VERSION ""

NS_ :

BS_:

BU_: FC ADS HPP APA FR

BO_ 400 FC_190: 64 FC
 SG_ FC_Line03_BlockCtr : 495|4@0+ (1,0) [0|15] "-"  HPP,ADS,APA
 SG_ FC_RollingCounter_190 : 491|4@0+ (1,0) [0|15] ""  HPP,ADS,APA
 SG_ FC_CRCCheck_190 : 503|16@0+ (1,0) [0|65535] ""  HPP,ADS,APA
 SG_ FC_Line_03_MeasureType : 465|2@0+ (1,0) [0|2] ""  HPP,ADS,APA
 SG_ FC_Line_03_curvature_alteration : 371|12@0+ (3.8147E-006,-0.0078125) [-0.0078125|0.0078086965] "1/m2"  HPP,ADS,APA
 SG_ FC_Line_03__curve : 479|13@0+ (3.8147E-006,-0.015625) [-0.015625|0.0156212077] "1/m"  HPP,ADS,APA
 SG_ FC_Line_03_HeadingAngle : 351|13@0+ (0.000488281,-1.6) [-1.6|1.6] "rad"  HPP,ADS,APA
 SG_ FC_Line_03_dy : 462|12@0+ (0.015625,-32) [-32|31.984375] "m"  HPP,ADS,APA
 SG_ FC_Line_03_dx_End_std : 455|9@0+ (0.0078125,0) [0|3.992187] "m"  HPP,ADS,APA
 SG_ FC_Line_03__dx_End : 433|10@0+ (0.25,0) [0|255.75] "m"  HPP,ADS,APA
 SG_ FC_Line_03_dx_Start_std : 426|9@0+ (0.0078125,0) [0|3.9921875] "m"  HPP,ADS,APA
 SG_ FC_Line_03_dx_Start : 423|13@0+ (0.025,0) [0|204.775] "m"  HPP,ADS,APA
 SG_ FC_Line_03_Width : 415|8@0+ (0.01,0) [0|2.55] "m"  HPP,ADS,APA
 SG_ FC_Line_03_color : 402|3@0+ (1,0) [0|7] ""  HPP,ADS,APA
 SG_ FC_Line_03_Id : 399|8@0+ (1,0) [1|255] ""  HPP,ADS,APA
 SG_ FC_Line_03_TypeConfidence : 391|6@0+ (2,0) [0|100] "%"  HPP,ADS,APA
 SG_ FC_Line_03_Type : 407|5@0+ (1,0) [0|31] ""  HPP,ADS,APA
 SG_ FC_Line_02__exist_prob : 325|6@0+ (2,0) [0|100] "%"  HPP,ADS,APA
 SG_ FC_Line_02_MeasureType : 310|2@0+ (1,0) [0|2] ""  HPP,ADS,APA
 SG_ FC_Line_02_curvature_alteration : 307|12@0+ (3.8147E-006,-0.0078125) [-0.0078125|0.0078086965] "1/m2"  HPP,ADS,APA
 SG_ FC_Line_02__curve : 292|13@0+ (3.8147E-006,-0.015625) [-0.015625|0.0156212077] "1/m"  HPP,ADS,APA
 SG_ FC_Line_02_HeadingAngle : 335|13@0+ (0.000488281,-1.6) [-1.6|1.6] "rad"  HPP,ADS,APA
 SG_ FC_Line_02_dy : 270|12@0+ (0.015625,-32) [-32|31.984375] "m"  HPP,ADS,APA
 SG_ FC_Line_02_dx_End_std : 263|9@0+ (0.0078125,0) [0|3.992187] "m"  HPP,ADS,APA
 SG_ FC_Line_02__dx_End : 241|10@0+ (0.25,0) [0|255.75] "m"  HPP,ADS,APA
 SG_ FC_Line_02_dx_Start_std : 234|9@0+ (0.0078125,0) [0|3.9921875] "m"  HPP,ADS,APA
 SG_ FC_Line_02_dx_Start : 231|13@0+ (0.025,0) [0|204.775] "m"  HPP,ADS,APA
 SG_ FC_Line_02_Width : 223|8@0+ (0.01,0) [0|2.55] "m"  HPP,ADS,APA
 SG_ FC_Line_02_color : 210|3@0+ (1,0) [0|7] ""  HPP,ADS,APA
 SG_ FC_Line_02_Id : 207|8@0+ (1,0) [1|255] ""  HPP,ADS,APA
 SG_ FC_Line_02_TypeConfidence : 199|6@0+ (2,0) [0|100] "%"  HPP,ADS,APA
 SG_ FC_Line_02_Type : 215|5@0+ (1,0) [0|31] ""  HPP,ADS,APA
 SG_ FC_Line02_BlockCtr : 187|4@0+ (1,0) [0|15] "-"  HPP,ADS,APA
 SG_ FC_Line01_BlockCtr : 191|4@0+ (1,0) [0|15] "-"  HPP,ADS,APA
 SG_ FC_LineTiOut : 146|1@0+ (1,0) [0|1] "-"  HPP,ADS,APA
 SG_ FC_LineTiLeap : 145|1@0+ (1,0) [0|1] "-"  HPP,ADS,APA
 SG_ FC_LineTiBas : 144|1@0+ (1,0) [0|1] "-"  HPP,ADS,APA
 SG_ FC_LineTiStamp : 159|32@0+ (0.0001,0) [0|429496.7295] "s"  HPP,ADS,APA
 SG_ FC_Line_01__exist_prob : 133|6@0+ (2,0) [0|100] "%"  HPP,ADS,APA
 SG_ FC_Line_01_MeasureType : 118|2@0+ (1,0) [0|2] ""  HPP,ADS,APA
 SG_ FC_Line_01_curvature_alteration : 115|12@0+ (3.8147E-006,-0.0078125) [-0.0078125|0.0078086965] "1/m2"  HPP,ADS,APA
 SG_ FC_Line_01__curve : 100|13@0+ (3.8147E-006,-0.015625) [-0.015625|0.0156212077] "1/m"  HPP,ADS,APA
 SG_ FC_Line_01_HeadingAngle : 143|13@0+ (0.000488281,-1.6) [-1.6|1.6] "rad"  HPP,ADS,APA
 SG_ FC_Line_01_dy : 78|12@0+ (0.015625,-32) [-32|31.984375] "m"  HPP,ADS,APA
 SG_ FC_Line_01_dx_End_std : 71|9@0+ (0.0078125,0) [0|3.992187] "m"  HPP,ADS,APA
 SG_ FC_Line_01__dx_End : 49|10@0+ (0.25,0) [0|255.75] "m"  HPP,ADS,APA
 SG_ FC_Line_01_dx_Start_std : 42|9@0+ (0.0078125,0) [0|3.9921875] "m"  HPP,ADS,APA
 SG_ FC_Line_01_dx_Start : 39|13@0+ (0.025,0) [0|204.775] "m"  HPP,ADS,APA
 SG_ FC_Line_01_Width : 31|8@0+ (0.01,0) [0|2.55] "m"  HPP,ADS,APA
 SG_ FC_Line_01_color : 18|3@0+ (1,0) [0|7] ""  HPP,ADS,APA
 SG_ FC_Line_01_Id : 15|8@0+ (1,0) [1|255] ""  HPP,ADS,APA
 SG_ FC_Line_01_TypeConfidence : 7|6@0+ (2,0) [0|100] "%"  HPP,ADS,APA
 SG_ FC_Line_01_Type : 23|5@0+ (1,0) [0|31] ""  HPP,ADS,APA

BO_ 401 FC_191: 64 FC
 SG_ FC_RollingCounter_191 : 491|4@0+ (1,0) [0|15] ""  HPP,ADS,APA
 SG_ FC_CRCCheck_191 : 503|16@0+ (1,0) [0|65535] ""  HPP,ADS,APA
 SG_ FC_Line_06__exist_prob : 333|6@0+ (2,0) [0|100] "%"  HPP,ADS,APA
 SG_ FC_Line_06_MeasureType : 465|2@0+ (1,0) [0|2] ""  HPP,ADS,APA
 SG_ FC_Line_06_curvature_alteration : 371|12@0+ (3.8147E-006,-0.0078125) [-0.0078125|0.0078086965] "1/m2"  HPP,ADS,APA
 SG_ FC_Line_06__curve : 479|13@0+ (3.8147E-006,-0.015625) [-0.015625|0.0156212077] "1/m"  HPP,ADS,APA
 SG_ FC_Line_06_HeadingAngle : 343|13@0+ (0.000488281,-1.6) [-1.6|1.6] "rad"  HPP,ADS,APA
 SG_ FC_Line_06_dy : 462|12@0+ (0.015625,-32) [-32|31.984375] "m"  HPP,ADS,APA
 SG_ FC_Line_06_dx_End_std : 455|9@0+ (0.0078125,0) [0|3.992187] "m"  HPP,ADS,APA
 SG_ FC_Line_06__dx_End : 433|10@0+ (0.25,0) [0|255.75] "m"  HPP,ADS,APA
 SG_ FC_Line_06_dx_Start_std : 426|9@0+ (0.0078125,0) [0|3.9921875] "m"  HPP,ADS,APA
 SG_ FC_Line_06_dx_Start : 423|13@0+ (0.025,0) [0|204.775] "m"  HPP,ADS,APA
 SG_ FC_Line_06_Width : 415|8@0+ (0.01,0) [0|2.55] "m"  HPP,ADS,APA
 SG_ FC_Line_06_color : 402|3@0+ (1,0) [0|7] ""  HPP,ADS,APA
 SG_ FC_Line_06_Id : 399|8@0+ (1,0) [1|255] ""  HPP,ADS,APA
 SG_ FC_Line_06_TypeConfidence : 391|6@0+ (2,0) [0|100] "%"  HPP,ADS,APA
 SG_ FC_Line_06_Type : 407|5@0+ (1,0) [0|31] ""  HPP,ADS,APA
 SG_ FC_Line_05__exist_prob : 325|6@0+ (2,0) [0|100] "%"  HPP,ADS,APA
 SG_ FC_Line_05_MeasureType : 310|2@0+ (1,0) [0|2] ""  HPP,ADS,APA
 SG_ FC_Line_05_curvature_alteration : 307|12@0+ (3.8147E-006,-0.0078125) [-0.0078125|0.0078086965] "1/m2"  HPP,ADS,APA
 SG_ FC_Line_05__curve : 292|13@0+ (3.8147E-006,-0.015625) [-0.015625|0.0156212077] "1/m"  HPP,ADS,APA
 SG_ FC_Line_05_HeadingAngle : 167|13@0+ (0.000488281,-1.6) [-1.6|1.6] "rad"  HPP,ADS,APA
 SG_ FC_Line_05_dy : 270|12@0+ (0.015625,-32) [-32|31.984375] "m"  HPP,ADS,APA
 SG_ FC_Line_05_dx_End_std : 263|9@0+ (0.0078125,0) [0|3.992187] "m"  HPP,ADS,APA
 SG_ FC_Line_05__dx_End : 241|10@0+ (0.25,0) [0|255.75] "m"  HPP,ADS,APA
 SG_ FC_Line_05_dx_Start_std : 234|9@0+ (0.0078125,0) [0|3.9921875] "m"  HPP,ADS,APA
 SG_ FC_Line_05_dx_Start : 231|13@0+ (0.025,0) [0|204.775] "m"  HPP,ADS,APA
 SG_ FC_Line_05_Width : 223|8@0+ (0.01,0) [0|2.55] "m"  HPP,ADS,APA
 SG_ FC_Line_05_color : 210|3@0+ (1,0) [0|7] ""  HPP,ADS,APA
 SG_ FC_Line_05_Id : 207|8@0+ (1,0) [1|255] ""  HPP,ADS,APA
 SG_ FC_Line_05_TypeConfidence : 199|6@0+ (2,0) [0|100] "%"  HPP,ADS,APA
 SG_ FC_Line_05_Type : 215|5@0+ (1,0) [0|31] ""  HPP,ADS,APA
 SG_ FC_Line_04__exist_prob : 133|6@0+ (2,0) [0|100] "%"  HPP,ADS,APA
 SG_ FC_Line_04_MeasureType : 118|2@0+ (1,0) [0|2] ""  HPP,ADS,APA
 SG_ FC_Line_04_curvature_alteration : 115|12@0+ (3.8147E-006,-0.0078125) [-0.0078125|0.0078086965] "1/m2"  HPP,ADS,APA
 SG_ FC_Line_04__curve : 100|13@0+ (3.8147E-006,-0.015625) [-0.015625|0.0156212077] "1/m"  HPP,ADS,APA
 SG_ FC_Line_04_HeadingAngle : 151|13@0+ (0.000488281,-1.6) [-1.6|1.6] "rad"  HPP,ADS,APA
 SG_ FC_Line_04_dy : 78|12@0+ (0.015625,-32) [-32|31.984375] "m"  HPP,ADS,APA
 SG_ FC_Line_04_dx_End_std : 71|9@0+ (0.0078125,0) [0|3.992187] "m"  HPP,ADS,APA
 SG_ FC_Line_04__dx_End : 49|10@0+ (0.25,0) [0|255.75] "m"  HPP,ADS,APA
 SG_ FC_Line_04_dx_Start_std : 42|9@0+ (0.0078125,0) [0|3.9921875] "m"  HPP,ADS,APA
 SG_ FC_Line_04_dx_Start : 39|13@0+ (0.025,0) [0|204.775] "m"  HPP,ADS,APA
 SG_ FC_Line_04_Width : 31|8@0+ (0.01,0) [0|2.55] "m"  HPP,ADS,APA
 SG_ FC_Line_04_color : 18|3@0+ (1,0) [0|7] ""  HPP,ADS,APA
 SG_ FC_Line_04_Id : 15|8@0+ (1,0) [1|255] ""  HPP,ADS,APA
 SG_ FC_Line_04_TypeConfidence : 7|6@0+ (2,0) [0|100] "%"  HPP,ADS,APA
 SG_ FC_Line_04_Type : 23|5@0+ (1,0) [0|31] ""  HPP,ADS,APA
 SG_ FC_Line_03__exist_prob : 141|6@0+ (2,0) [0|100] "%"  HPP,ADS,APA
 SG_ FC_Line06_BlockCtr : 495|4@0+ (1,0) [0|15] "-"  HPP,ADS,APA
 SG_ FC_Line05_BlockCtr : 187|4@0+ (1,0) [0|15] "-"  HPP,ADS,APA
 SG_ FC_Line04_BlockCtr : 191|4@0+ (1,0) [0|15] "-"  HPP,ADS,APA

BO_ 402 FC_192: 64 FC
 SG_ FC_RoadSignTiOut : 487|1@0+ (1,0) [0|1] "-"  HPP,ADS,APA
 SG_ FC_RoadSignTiLeap : 486|1@0+ (1,0) [0|1] "-"  HPP,ADS,APA
 SG_ FC_RoadSignTiBas : 485|1@0+ (1,0) [0|1] "-"  HPP,ADS,APA
 SG_ FC_RoadSignTiStamp : 455|32@0+ (0.0001,0) [0|429496.7295] "s"  HPP,ADS,APA
 SG_ FC_RollingCounter_192 : 491|4@0+ (1,0) [0|15] ""  HPP,ADS,APA
 SG_ FC_CRCCheck_192 : 503|16@0+ (1,0) [0|65535] ""  HPP,ADS,APA
 SG_ FC_Line_08__exist_prob : 325|6@0+ (2,0) [0|100] "%"  HPP,ADS,APA
 SG_ FC_Line_08_MeasureType : 310|2@0+ (1,0) [0|2] ""  HPP,ADS,APA
 SG_ FC_Line_08_curvature_alteration : 307|12@0+ (3.8147E-006,-0.0078125) [-0.0078125|0.0078086965] "1/m2"  HPP,ADS,APA
 SG_ FC_Line_08__curve : 292|13@0+ (3.8147E-006,-0.015625) [-0.015625|0.0156212077] "1/m"  HPP,ADS,APA
 SG_ FC_Line_08_HeadingAngle : 335|13@0+ (0.000488281,-1.6) [-1.6|1.6] "rad"  HPP,ADS,APA
 SG_ FC_Line_08_dy : 270|12@0+ (0.015625,-32) [-32|31.984375] "m"  HPP,ADS,APA
 SG_ FC_Line_08_dx_End_std : 263|9@0+ (0.0078125,0) [0|3.992187] "m"  HPP,ADS,APA
 SG_ FC_Line_08__dx_End : 241|10@0+ (0.25,0) [0|255.75] "m"  HPP,ADS,APA
 SG_ FC_Line_08_dx_Start_std : 234|9@0+ (0.0078125,0) [0|3.9921875] "m"  HPP,ADS,APA
 SG_ FC_Line_08_dx_Start : 231|13@0+ (0.025,0) [0|204.775] "m"  HPP,ADS,APA
 SG_ FC_Line_08_Width : 223|8@0+ (0.01,0) [0|2.55] "m"  HPP,ADS,APA
 SG_ FC_Line_08_color : 210|3@0+ (1,0) [0|7] ""  HPP,ADS,APA
 SG_ FC_Line_08_Id : 207|8@0+ (1,0) [1|255] ""  HPP,ADS,APA
 SG_ FC_Line_08_TypeConfidence : 199|6@0+ (2,0) [0|100] "%"  HPP,ADS,APA
 SG_ FC_Line_08_Type : 215|5@0+ (1,0) [0|31] ""  HPP,ADS,APA
 SG_ FC_Line_07__exist_prob : 133|6@0+ (2,0) [0|100] "%"  HPP,ADS,APA
 SG_ FC_Line_07_MeasureType : 118|2@0+ (1,0) [0|2] ""  HPP,ADS,APA
 SG_ FC_Line_07_curvature_alteration : 115|12@0+ (3.8147E-006,-0.0078125) [-0.0078125|0.0078086965] "1/m2"  HPP,ADS,APA
 SG_ FC_Line_07__curve : 100|13@0+ (3.8147E-006,-0.015625) [-0.015625|0.0156212077] "1/m"  HPP,ADS,APA
 SG_ FC_Line_07_HeadingAngle : 143|13@0+ (0.000488281,-1.6) [-1.6|1.6] "rad"  HPP,ADS,APA
 SG_ FC_Line_07_dy : 78|12@0+ (0.015625,-32) [-32|31.984375] "m"  HPP,ADS,APA
 SG_ FC_Line_07_dx_End_std : 71|9@0+ (0.0078125,0) [0|3.992187] "m"  HPP,ADS,APA
 SG_ FC_Line_07__dx_End : 49|10@0+ (0.25,0) [0|255.75] "m"  HPP,ADS,APA
 SG_ FC_Line_07_dx_Start_std : 42|9@0+ (0.0078125,0) [0|3.9921875] "m"  HPP,ADS,APA
 SG_ FC_Line_07_dx_Start : 39|13@0+ (0.025,0) [0|204.775] "m"  HPP,ADS,APA
 SG_ FC_Line_07_Width : 31|8@0+ (0.01,0) [0|2.55] "m"  HPP,ADS,APA
 SG_ FC_Line_07_color : 18|3@0+ (1,0) [0|7] ""  HPP,ADS,APA
 SG_ FC_Line_07_Id : 15|8@0+ (1,0) [1|255] ""  HPP,ADS,APA
 SG_ FC_Line_07_TypeConfidence : 7|6@0+ (2,0) [0|100] "%"  HPP,ADS,APA
 SG_ FC_Line_07_Type : 23|5@0+ (1,0) [0|31] ""  HPP,ADS,APA
 SG_ FC_Line08_BlockCtr : 187|4@0+ (1,0) [0|15] "-"  HPP,ADS,APA
 SG_ FC_Line07_BlockCtr : 191|4@0+ (1,0) [0|15] "-"  HPP,ADS,APA

BO_ 403 FC_193: 64 FC
 SG_ FC_SignBoardTiOut : 495|1@0+ (1,0) [0|1] "-"  HPP,ADS
 SG_ FC_SignBoardTiLeap : 494|1@0+ (1,0) [0|1] "-"  HPP,ADS
 SG_ FC_SignBoardTiBas : 493|1@0+ (1,0) [0|1] "-"  HPP,ADS
 SG_ FC_SignBoardTiStamp : 463|32@0+ (0.0001,0) [0|429496.7295] "s"  HPP,ADS
 SG_ FC_RollingCounter_193 : 491|4@0+ (1,0) [0|15] ""  HPP,ADS
 SG_ FC_CRCCheck_193 : 503|16@0+ (1,0) [0|65535] ""  HPP,ADS
 SG_ FC_SignBoardConfidence_3 : 446|7@0+ (1,0) [0|100] "%"  HPP,ADS
 SG_ FC_SignBoardLength_3 : 437|6@0+ (0.05,0) [0|3.15] "m"  HPP,ADS
 SG_ FC_SignBoardWidth_3 : 429|6@0+ (0.05,0) [0|3.15] "m"  HPP,ADS
 SG_ FC_SignBoardHeight_3 : 420|5@0+ (0.5,0) [0|15.5] "m"  HPP,ADS
 SG_ FC_SignBoardCenterLatRange_3 : 413|9@0+ (0.05,-8) [-8|17.55] "m"  HPP,ADS
 SG_ FC_SignBoardCenterLngRange_3 : 392|9@0+ (0.1,0) [0|51.1] "m"  HPP,ADS
 SG_ FC_SpeedLimit_3 : 398|6@0+ (1,0) [0|63] ""  HPP,ADS
 SG_ FC_SignBoardType_3 : 389|5@0+ (1,0) [0|31] ""  HPP,ADS
 SG_ FC_SignBoardConfidence_2 : 382|7@0+ (1,0) [0|100] "%"  HPP,ADS
 SG_ FC_SignBoardLength_2 : 373|6@0+ (0.05,0) [0|3.15] "m"  HPP,ADS
 SG_ FC_SignBoardWidth_2 : 365|6@0+ (0.05,0) [0|3.15] "m"  HPP,ADS
 SG_ FC_SignBoardHeight_2 : 356|5@0+ (0.5,0) [0|15.5] "m"  HPP,ADS
 SG_ FC_SignBoardCenterLatRange_2 : 349|9@0+ (0.05,-8) [-8|17.55] "m"  HPP,ADS
 SG_ FC_SignBoardCenterLngRange_2 : 328|9@0+ (0.1,0) [0|51.1] "m"  HPP,ADS
 SG_ FC_SpeedLimit_2 : 334|6@0+ (1,0) [0|63] ""  HPP,ADS
 SG_ FC_SignBoardType_2 : 325|5@0+ (1,0) [0|31] ""  HPP,ADS
 SG_ FC_SignBoardConfidence_1 : 318|7@0+ (1,0) [0|100] "%"  HPP,ADS
 SG_ FC_SignBoardLength_1 : 309|6@0+ (0.05,0) [0|3.15] "m"  HPP,ADS
 SG_ FC_SignBoardWidth_1 : 301|6@0+ (0.05,0) [0|3.15] "m"  HPP,ADS
 SG_ FC_SignBoardHeight_1 : 292|5@0+ (0.5,0) [0|15.5] "m"  HPP,ADS
 SG_ FC_SignBoardCenterLatRange_1 : 285|9@0+ (0.05,-8) [-8|17.55] "m"  HPP,ADS
 SG_ FC_SignBoardCenterLngRange_1 : 264|9@0+ (0.1,0) [0|51.1] "m"  HPP,ADS
 SG_ FC_SpeedLimit_1 : 270|6@0+ (1,0) [0|63] ""  HPP,ADS
 SG_ FC_SignBoardType_1 : 261|5@0+ (1,0) [0|31] ""  HPP,ADS
 SG_ FC_RoadSignConfidence_4 : 254|7@0+ (1,0) [0|100] "%"  HPP,ADS
 SG_ FC_RoadSignLength_4 : 246|6@0+ (0.05,0) [0|3.15] "m"  HPP,ADS
 SG_ FC_RoadSignWidth_4 : 238|6@0+ (0.05,0) [0|3.15] "m"  HPP,ADS
 SG_ FC_RoadSignCenterLatRange_4 : 217|9@0+ (0.05,-8) [-8|17.55] "m"  HPP,ADS
 SG_ FC_RoadSignCenterLngRange_4 : 211|9@0+ (0.1,0) [0|51.1] "m"  HPP,ADS
 SG_ FC_RoadSignType_4 : 201|5@0+ (1,0) [0|15] ""  HPP,ADS
 SG_ FC_RoadSignConfidence_3 : 190|7@0+ (1,0) [0|100] "%"  HPP,ADS
 SG_ FC_RoadSignLength_3 : 182|6@0+ (0.05,0) [0|3.15] "m"  HPP,ADS
 SG_ FC_RoadSignWidth_3 : 174|6@0+ (0.05,0) [0|3.15] "m"  HPP,ADS
 SG_ FC_RoadSignCenterLatRange_3 : 153|9@0+ (0.05,-8) [-8|17.55] "m"  HPP,ADS
 SG_ FC_RoadSignCenterLngRange_3 : 147|9@0+ (0.1,0) [0|51.1] "m"  HPP,ADS
 SG_ FC_RoadSignType_3 : 137|5@0+ (1,0) [0|15] ""  HPP,ADS
 SG_ FC_RoadSignConfidence_2 : 126|7@0+ (1,0) [0|100] "%"  HPP,ADS
 SG_ FC_RoadSignLength_2 : 118|6@0+ (0.05,0) [0|3.15] "m"  HPP,ADS
 SG_ FC_RoadSignWidth_2 : 110|6@0+ (0.05,0) [0|3.15] "m"  HPP,ADS
 SG_ FC_RoadSignCenterLatRange_2 : 89|9@0+ (0.05,-8) [-8|17.55] "m"  HPP,ADS
 SG_ FC_RoadSignCenterLngRange_2 : 83|9@0+ (0.1,0) [0|51.1] "m"  HPP,ADS
 SG_ FC_RoadSignType_2 : 73|5@0+ (1,0) [0|15] ""  HPP,ADS
 SG_ FC_RoadSignConfidence_1 : 62|7@0+ (1,0) [0|100] "%"  HPP,ADS
 SG_ FC_RoadSignLength_1 : 54|6@0+ (0.05,0) [0|3.15] "m"  HPP,ADS
 SG_ FC_RoadSignWidth_1 : 46|6@0+ (0.05,0) [0|3.15] "m"  HPP,ADS
 SG_ FC_RoadSignCenterLatRange_1 : 25|9@0+ (0.05,-8) [-8|17.55] "m"  HPP,ADS
 SG_ FC_RoadSignCenterLngRange_1 : 19|9@0+ (0.1,0) [0|51.1] "m"  HPP,ADS
 SG_ FC_RoadSignType_1 : 9|5@0+ (1,0) [0|15] ""  HPP,ADS
 SG_ FC_SignBoard03_BlockCtr : 451|4@0+ (1,0) [0|15] "-"  HPP,ADS
 SG_ FC_SignBoardn02_BlockCtr : 455|4@0+ (1,0) [0|15] "-"  HPP,ADS
 SG_ FC_SignBoard01_BlockCtr : 205|4@0+ (1,0) [0|15] "-"  HPP,ADS
 SG_ FC_RoadSign04_BlockCtr : 199|4@0+ (1,0) [0|15] "-"  HPP,ADS
 SG_ FC_RoadSign03_BlockCtr : 135|4@0+ (1,0) [0|15] "-"  HPP,ADS
 SG_ FC_RoadSign02_BlockCtr : 71|4@0+ (1,0) [0|15] "-"  HPP,ADS
 SG_ FC_RoadSign01_BlockCtr : 7|4@0+ (1,0) [0|15] "-"  HPP,ADS

BO_ 404 FC_194: 64 FC
 SG_ FC_TFLTiOut : 487|1@0+ (1,0) [0|1] "-"  HPP,ADS
 SG_ FC_TFLTiLeap : 486|1@0+ (1,0) [0|1] "-"  HPP,ADS
 SG_ FC_TFLTiBas : 485|1@0+ (1,0) [0|1] "-"  HPP,ADS
 SG_ FC_TFLTiStamp : 455|32@0+ (0.0001,0) [0|429496.7295] "s"  HPP,ADS
 SG_ FC_RollingCounter_194 : 491|4@0+ (1,0) [0|15] ""  HPP,ADS
 SG_ FC_CRCCheck_194 : 503|16@0+ (1,0) [0|65535] ""  HPP,ADS
 SG_ FC_Num_Of_TFL_Objects : 378|3@0+ (1,0) [0|7] ""  HPP,ADS
 SG_ FC_TFL6_Confidence : 375|7@0+ (1,0) [0|100] "%"  HPP,ADS
 SG_ FC_TFL6_Direction : 367|3@0+ (1,0) [0|7] ""  HPP,ADS
 SG_ FC_TFL6_Type : 327|2@0+ (1,0) [0|3] ""  HPP,ADS
 SG_ FC_TFL6_PosZ : 359|6@0+ (0.1,0) [1.2|5.5] "m"  HPP,ADS
 SG_ FC_TFL6_PosY : 341|11@0+ (0.01,0) [0|15] "m"  HPP,ADS
 SG_ FC_TFL6_PosX : 321|10@0+ (0.1,0) [0|80] "m"  HPP,ADS
 SG_ FC_TFL5_Confidence : 311|7@0+ (1,0) [0|100] "%"  HPP,ADS
 SG_ FC_TFL5_Direction : 303|3@0+ (1,0) [0|7] ""  HPP,ADS
 SG_ FC_TFL5_Type : 263|2@0+ (1,0) [0|3] ""  HPP,ADS
 SG_ FC_TFL5_PosZ : 295|6@0+ (0.1,0) [1.2|5.5] "m"  HPP,ADS
 SG_ FC_TFL5_PosY : 277|11@0+ (0.01,0) [0|15] "m"  HPP,ADS
 SG_ FC_TFL5_PosX : 257|10@0+ (0.1,0) [0|80] "m"  HPP,ADS
 SG_ FC_TFL4_Confidence : 247|7@0+ (1,0) [0|100] "%"  HPP,ADS
 SG_ FC_TFL4_Direction : 239|3@0+ (1,0) [0|7] ""  HPP,ADS
 SG_ FC_TFL4_Type : 199|2@0+ (1,0) [0|3] ""  HPP,ADS
 SG_ FC_TFL4_PosZ : 231|6@0+ (0.1,0) [1.2|5.5] "m"  HPP,ADS
 SG_ FC_TFL4_PosY : 213|11@0+ (0.01,0) [0|15] "m"  HPP,ADS
 SG_ FC_TFL4_PosX : 193|10@0+ (0.1,0) [0|80] "m"  HPP,ADS
 SG_ FC_TFL3_Confidence : 183|7@0+ (1,0) [0|100] "%"  HPP,ADS
 SG_ FC_TFL3_Direction : 175|3@0+ (1,0) [0|7] ""  HPP,ADS
 SG_ FC_TFL3_Type : 135|2@0+ (1,0) [0|3] ""  HPP,ADS
 SG_ FC_TFL3_PosZ : 167|6@0+ (0.1,0) [1.2|5.5] "m"  HPP,ADS
 SG_ FC_TFL3_PosY : 149|11@0+ (0.01,0) [0|15] "m"  HPP,ADS
 SG_ FC_TFL3_PosX : 129|10@0+ (0.1,0) [0|80] "m"  HPP,ADS
 SG_ FC_TFL2_Confidence : 119|7@0+ (1,0) [0|100] "%"  HPP,ADS
 SG_ FC_TFL2_Direction : 111|3@0+ (1,0) [0|7] ""  HPP,ADS
 SG_ FC_TFL2_Type : 71|2@0+ (1,0) [0|3] ""  HPP,ADS
 SG_ FC_TFL2_PosZ : 103|6@0+ (0.1,0) [1.2|5.5] "m"  HPP,ADS
 SG_ FC_TFL2_PosY : 85|11@0+ (0.01,0) [0|15] "m"  HPP,ADS
 SG_ FC_TFL2_PosX : 65|10@0+ (0.1,0) [0|80] "m"  HPP,ADS
 SG_ FC_TFL1_Confidence : 55|7@0+ (1,0) [0|100] "%"  HPP,ADS
 SG_ FC_TFL1_Direction : 47|3@0+ (1,0) [0|7] ""  HPP,ADS
 SG_ FC_TFL1_Type : 7|2@0+ (1,0) [0|3] ""  HPP,ADS
 SG_ FC_TFL1_PosZ : 39|6@0+ (0.1,0) [1.2|5.5] "m"  HPP,ADS
 SG_ FC_TFL1_PosY : 21|11@0+ (0.01,0) [0|15] "m"  HPP,ADS
 SG_ FC_TFL1_PosX : 1|10@0+ (0.1,0) [0|80] "m"  HPP,ADS
 SG_ FC_SignBoardConfidence_4 : 446|7@0+ (1,0) [0|100] "%"  HPP,ADS
 SG_ FC_SignBoardLength_4 : 437|6@0+ (0.05,0) [0|3.15] "m"  HPP,ADS
 SG_ FC_SignBoardWidth_4 : 429|6@0+ (0.05,0) [0|3.15] "m"  HPP,ADS
 SG_ FC_SignBoardHeight_4 : 420|5@0+ (0.5,0) [0|15.5] "m"  HPP,ADS
 SG_ FC_SignBoardCenterLatRange_4 : 413|9@0+ (0.05,-8) [-8|17.55] "m"  HPP,ADS
 SG_ FC_SignBoardCenterLngRange_4 : 392|9@0+ (0.1,0) [0|51.1] "m"  HPP,ADS
 SG_ FC_SpeedLimit_4 : 398|6@0+ (1,0) [0|63] ""  HPP,ADS
 SG_ FC_SignBoardType_4 : 389|5@0+ (1,0) [0|31] ""  HPP,ADS
 SG_ FC_SignBoard04_BlockCtr : 495|4@0+ (1,0) [0|15] "-"  HPP,ADS
 SG_ FC_TFL06_BlockCtr : 363|4@0+ (1,0) [0|15] "-"  HPP,ADS
 SG_ FC_TFL05_BlockCtr : 299|4@0+ (1,0) [0|15] "-"  HPP,ADS
 SG_ FC_TFL04_BlockCtr : 235|4@0+ (1,0) [0|15] "-"  HPP,ADS
 SG_ FC_TFL03_BlockCtr : 171|4@0+ (1,0) [0|15] "-"  HPP,ADS
 SG_ FC_TFL02_BlockCtr : 107|4@0+ (1,0) [0|15] "-"  HPP,ADS
 SG_ FC_TFL01_BlockCtr : 43|4@0+ (1,0) [0|15] "-"  HPP,ADS

BO_ 405 FC_195: 64 FC
 SG_ FC_Obj9_Dx_Vnce : 475|14@0+ (0.05,0) [0|50] "m2"  ADS,APA
 SG_ FC_Obj9_Dx : 471|12@0+ (0.05,0) [0|204.7] "m"  ADS,APA
 SG_ FC_Obj9_ClassifiedView : 460|3@0+ (1,0) [0|7] ""  ADS,APA
 SG_ FC_Obj9_Vy : 455|10@0+ (0.1,-50) [-50|50] "m/s"  ADS,APA
 SG_ FC_Obj9_Vx : 435|12@0+ (0.1,-154) [-154|50] "m/s"  ADS,APA
 SG_ FC_Obj9_Ay : 431|8@0+ (0.1,-12) [-12|12] "m/s2"  ADS,APA
 SG_ FC_Obj9_Ax : 408|9@0+ (0.1,-16) [-16|16] "m/s2"  ADS,APA
 SG_ FC_Obj9_TypeProb : 415|6@0+ (2,0) [0|100] "%"  ADS,APA
 SG_ FC_Obj9_Type : 397|3@0+ (1,0) [0|7] ""  ADS,APA
 SG_ FC_Obj9_Track_Age : 407|8@0+ (1,0) [0|254] ""  ADS,APA
 SG_ FC_Obj9_Track_ID : 391|8@0+ (1,0) [0|254] ""  ADS,APA
 SG_ FC_RollingCounter_195 : 491|4@0+ (1,0) [0|15] ""  ADS,APA
 SG_ FC_CRCCheck_195 : 503|16@0+ (1,0) [0|65535] ""  ADS,APA
 SG_ FC_ObjTiOut : 346|1@0+ (1,0) [0|1] "-"  ADS,APA
 SG_ FC_ObjTiLeap : 345|1@0+ (1,0) [0|1] "-"  ADS,APA
 SG_ FC_ObjTiBas : 344|1@0+ (1,0) [0|1] "-"  ADS,APA
 SG_ FC_ObjTiStamp : 359|32@0+ (0.0001,0) [0|429496.7295] "s"  ADS,APA
 SG_ FC_obj1_Brakelight_Info : 338|1@0+ (1,0) [0|1] ""  ADS,APA
 SG_ FC_obj1_Taillight_Info : 341|3@0+ (1,0) [0|7] ""  ADS,APA
 SG_ FC_Obj1_PhiTop : 327|12@0+ (0.00025,-0.4) [-0.4|0.4] "rad"  ADS,APA
 SG_ FC_Obj1_PhiRightVel : 311|13@0+ (0.001,-4) [-4|4] "rad/s"  ADS,APA
 SG_ FC_Obj1_PhiRight : 295|13@0+ (0.00025,-1) [-1|1] "rad"  ADS,APA
 SG_ FC_Obj1_PhiMid : 279|13@0+ (0.00025,-1) [-1|1] "rad"  ADS,APA
 SG_ FC_Obj1_PhiLeftVel : 263|13@0+ (0.001,-4) [-4|4] "rad/s"  ADS,APA
 SG_ FC_Obj1_PhiLeft : 247|13@0+ (0.00025,-1) [-1|1] "rad"  ADS,APA
 SG_ FC_Obj1_PhiBottom : 227|12@0+ (0.00025,-0.4) [-0.4|0.4] "rad"  ADS,APA
 SG_ FC_Obj1_Width : 210|11@0+ (0.01,0) [0|12] "m"  ADS,APA
 SG_ FC_Obj1_Length : 204|9@0+ (0.05,0) [0|25.5] "m"  ADS,APA
 SG_ FC_Obj1_Height : 199|9@0+ (0.01,0) [0|5.11] "m"  ADS,APA
 SG_ FC_Obj1_HeadOrientation : 188|4@0+ (1,0) [0|15] ""  ADS,APA
 SG_ FC_Obj1_HeadingAngle : 183|9@0+ (0.01,-1.57) [-1.57|1.57] "rad"  ADS,APA
 SG_ FC_Obj1_ExistProb : 175|6@0+ (2,0) [0|100] "%"  ADS,APA
 SG_ FC_Obj1_Dy_Vnce : 151|10@0+ (0.02,0) [0|20] "m2"  ADS,APA
 SG_ FC_Obj1_Dy : 135|14@0+ (0.01,-80) [-80|80] "m"  ADS,APA
 SG_ FC_Obj1_Dx_Vnce : 103|14@0+ (0.05,0) [0|50] "m2"  ADS,APA
 SG_ FC_Obj1_Dx : 87|12@0+ (0.05,0) [0|204.7] "m"  ADS,APA
 SG_ FC_Obj1_ClassifiedView : 76|3@0+ (1,0) [0|7] ""  ADS,APA
 SG_ FC_Obj1_Vy : 71|10@0+ (0.1,-50) [-50|50] "m/s"  ADS,APA
 SG_ FC_Obj1_Vx : 51|12@0+ (0.1,-154) [-154|50] "m/s"  ADS,APA
 SG_ FC_Obj1_Ay : 47|8@0+ (0.1,-12) [-12|12] "m/s2"  ADS,APA
 SG_ FC_Obj1_Ax : 24|9@0+ (0.1,-16) [-16|16] "m/s2"  ADS,APA
 SG_ FC_Obj1_TypeProb : 31|6@0+ (2,0) [0|100] "%"  ADS,APA
 SG_ FC_Obj1_Type : 13|3@0+ (1,0) [0|7] ""  ADS,APA
 SG_ FC_Obj1_Track_Age : 23|8@0+ (1,0) [0|254] ""  ADS,APA
 SG_ FC_Obj1_Track_ID : 7|8@0+ (1,0) [0|254] ""  ADS,APA
 SG_ FC_Obj01_BlockCtr : 91|4@0+ (1,0) [0|15] "-"  ADS,APA

BO_ 406 FC_196: 64 FC
 SG_ FC_Obj9_PhiLeft : 355|13@0+ (0.00025,-1) [-1|1] "rad"  ADS,APA
 SG_ FC_Obj9_PhiBottom : 351|12@0+ (0.00025,-0.4) [-0.4|0.4] "rad"  ADS,APA
 SG_ FC_Obj9_Width : 466|11@0+ (0.01,0) [0|12] "m"  ADS,APA
 SG_ FC_Obj9_Length : 460|9@0+ (0.05,0) [0|25.5] "m"  ADS,APA
 SG_ FC_Obj9_Height : 455|9@0+ (0.01,0) [0|5.11] "m"  ADS,APA
 SG_ FC_Obj9_HeadOrientation : 444|4@0+ (1,0) [0|15] ""  ADS,APA
 SG_ FC_Obj9_HeadingAngle : 439|9@0+ (0.01,-1.57) [-1.57|1.57] "rad"  ADS,APA
 SG_ FC_Obj9_ExistProb : 431|6@0+ (2,0) [0|100] "%"  ADS,APA
 SG_ FC_Obj9_Dy_Vnce : 407|10@0+ (0.02,0) [0|20] "m2"  ADS,APA
 SG_ FC_Obj9_Dy : 391|14@0+ (0.01,-80) [-80|80] "m"  ADS,APA
 SG_ FC_RollingCounter_196 : 491|4@0+ (1,0) [0|15] ""  ADS,APA
 SG_ FC_CRCCheck_196 : 503|16@0+ (1,0) [0|65535] ""  ADS,APA
 SG_ FC_obj2_Brakelight_Info : 338|1@0+ (1,0) [0|1] ""  ADS,APA
 SG_ FC_obj2_Taillight_Info : 341|3@0+ (1,0) [0|7] ""  ADS,APA
 SG_ FC_Obj2_PhiTop : 327|12@0+ (0.00025,-0.4) [-0.4|0.4] "rad"  ADS,APA
 SG_ FC_Obj2_PhiRightVel : 311|13@0+ (0.001,-4) [-4|4] "rad/s"  ADS,APA
 SG_ FC_Obj2_PhiRight : 295|13@0+ (0.00025,-1) [-1|1] "rad"  ADS,APA
 SG_ FC_Obj2_PhiMid : 279|13@0+ (0.00025,-1) [-1|1] "rad"  ADS,APA
 SG_ FC_Obj2_PhiLeftVel : 263|13@0+ (0.001,-4) [-4|4] "rad/s"  ADS,APA
 SG_ FC_Obj2_PhiLeft : 247|13@0+ (0.00025,-1) [-1|1] "rad"  ADS,APA
 SG_ FC_Obj2_PhiBottom : 227|12@0+ (0.00025,-0.4) [-0.4|0.4] "rad"  ADS,APA
 SG_ FC_Obj2_Width : 210|11@0+ (0.01,0) [0|12] "m"  ADS,APA
 SG_ FC_Obj2_Length : 204|9@0+ (0.05,0) [0|25.5] "m"  ADS,APA
 SG_ FC_Obj2_Height : 199|9@0+ (0.01,0) [0|5.11] "m"  ADS,APA
 SG_ FC_Obj2_HeadOrientation : 188|4@0+ (1,0) [0|15] ""  ADS,APA
 SG_ FC_Obj2_HeadingAngle : 183|9@0+ (0.01,-1.57) [-1.57|1.57] "rad"  ADS,APA
 SG_ FC_Obj2_ExistProb : 175|6@0+ (2,0) [0|100] "%"  ADS,APA
 SG_ FC_Obj2_Dy_Vnce : 151|10@0+ (0.02,0) [0|20] "m2"  ADS,APA
 SG_ FC_Obj2_Dy : 135|14@0+ (0.01,-80) [-80|80] "m"  ADS,APA
 SG_ FC_Obj2_Dx_Vnce : 103|14@0+ (0.05,0) [0|50] "m2"  ADS,APA
 SG_ FC_Obj2_Dx : 87|12@0+ (0.05,0) [0|204.7] "m"  ADS,APA
 SG_ FC_Obj2_ClassifiedView : 76|3@0+ (1,0) [0|7] ""  ADS,APA
 SG_ FC_Obj2_Vy : 71|10@0+ (0.1,-50) [-50|50] "m/s"  ADS,APA
 SG_ FC_Obj2_Vx : 51|12@0+ (0.1,-154) [-154|50] "m/s"  ADS,APA
 SG_ FC_Obj2_Ay : 47|8@0+ (0.1,-12) [-12|12] "m/s2"  ADS,APA
 SG_ FC_Obj2_Ax : 24|9@0+ (0.1,-16) [-16|16] "m/s2"  ADS,APA
 SG_ FC_Obj2_TypeProb : 31|6@0+ (2,0) [0|100] "%"  ADS,APA
 SG_ FC_Obj2_Type : 13|3@0+ (1,0) [0|7] ""  ADS,APA
 SG_ FC_Obj2_Track_Age : 23|8@0+ (1,0) [0|254] ""  ADS,APA
 SG_ FC_Obj2_Track_ID : 7|8@0+ (1,0) [0|254] ""  ADS,APA
 SG_ FC_Obj09_BlockCtr : 495|4@0+ (1,0) [0|15] "-"  ADS,APA
 SG_ FC_Obj02_BlockCtr : 91|4@0+ (1,0) [0|15] "-"  ADS,APA

BO_ 407 FC_197: 64 FC
 SG_ FC_obj9_Brakelight_Info : 466|1@0+ (1,0) [0|1] ""  ADS,APA
 SG_ FC_obj9_Taillight_Info : 469|3@0+ (1,0) [0|7] ""  ADS,APA
 SG_ FC_Obj9_PhiTop : 455|12@0+ (0.00025,-0.4) [-0.4|0.4] "rad"  ADS,APA
 SG_ FC_Obj9_PhiRightVel : 439|13@0+ (0.001,-4) [-4|4] "rad/s"  ADS,APA
 SG_ FC_Obj9_PhiRight : 423|13@0+ (0.00025,-1) [-1|1] "rad"  ADS,APA
 SG_ FC_Obj9_PhiMid : 407|13@0+ (0.00025,-1) [-1|1] "rad"  ADS,APA
 SG_ FC_Obj9_PhiLeftVel : 391|13@0+ (0.001,-4) [-4|4] "rad/s"  ADS,APA
 SG_ FC_RollingCounter_197 : 491|4@0+ (1,0) [0|15] ""  ADS,APA
 SG_ FC_CRCCheck_197 : 503|16@0+ (1,0) [0|65535] ""  ADS,APA
 SG_ FC_obj3_Brakelight_Info : 338|1@0+ (1,0) [0|1] ""  ADS,APA
 SG_ FC_obj3_Taillight_Info : 341|3@0+ (1,0) [0|7] ""  ADS,APA
 SG_ FC_Obj3_PhiTop : 327|12@0+ (0.00025,-0.4) [-0.4|0.4] "rad"  ADS,APA
 SG_ FC_Obj3_PhiRightVel : 311|13@0+ (0.001,-4) [-4|4] "rad/s"  ADS,APA
 SG_ FC_Obj3_PhiRight : 295|13@0+ (0.00025,-1) [-1|1] "rad"  ADS,APA
 SG_ FC_Obj3_PhiMid : 279|13@0+ (0.00025,-1) [-1|1] "rad"  ADS,APA
 SG_ FC_Obj3_PhiLeftVel : 263|13@0+ (0.001,-4) [-4|4] "rad/s"  ADS,APA
 SG_ FC_Obj3_PhiLeft : 247|13@0+ (0.00025,-1) [-1|1] "rad"  ADS,APA
 SG_ FC_Obj3_PhiBottom : 227|12@0+ (0.00025,-0.4) [-0.4|0.4] "rad"  ADS,APA
 SG_ FC_Obj3_Width : 210|11@0+ (0.01,0) [0|12] "m"  ADS,APA
 SG_ FC_Obj3_Length : 204|9@0+ (0.05,0) [0|25.5] "m"  ADS,APA
 SG_ FC_Obj3_Height : 199|9@0+ (0.01,0) [0|5.11] "m"  ADS,APA
 SG_ FC_Obj3_HeadOrientation : 188|4@0+ (1,0) [0|15] ""  ADS,APA
 SG_ FC_Obj3_HeadingAngle : 183|9@0+ (0.01,-1.57) [-1.57|1.57] "rad"  ADS,APA
 SG_ FC_Obj3_ExistProb : 175|6@0+ (2,0) [0|100] "%"  ADS,APA
 SG_ FC_Obj3_Dy_Vnce : 151|10@0+ (0.02,0) [0|20] "m2"  ADS,APA
 SG_ FC_Obj3_Dy : 135|14@0+ (0.01,-80) [-80|80] "m"  ADS,APA
 SG_ FC_Obj3_Dx_Vnce : 103|14@0+ (0.05,0) [0|50] "m2"  ADS,APA
 SG_ FC_Obj3_Dx : 87|12@0+ (0.05,0) [0|204.7] "m"  ADS,APA
 SG_ FC_Obj3_ClassifiedView : 76|3@0+ (1,0) [0|7] ""  ADS,APA
 SG_ FC_Obj3_Vy : 71|10@0+ (0.1,-50) [-50|50] "m/s"  ADS,APA
 SG_ FC_Obj3_Vx : 51|12@0+ (0.1,-154) [-154|50] "m/s"  ADS,APA
 SG_ FC_Obj3_Ay : 47|8@0+ (0.1,-12) [-12|12] "m/s2"  ADS,APA
 SG_ FC_Obj3_Ax : 24|9@0+ (0.1,-16) [-16|16] "m/s2"  ADS,APA
 SG_ FC_Obj3_TypeProb : 31|6@0+ (2,0) [0|100] "%"  ADS,APA
 SG_ FC_Obj3_Type : 13|3@0+ (1,0) [0|7] ""  ADS,APA
 SG_ FC_Obj3_Track_Age : 23|8@0+ (1,0) [0|254] ""  ADS,APA
 SG_ FC_Obj3_Track_ID : 7|8@0+ (1,0) [0|254] ""  ADS,APA
 SG_ FC_Obj03_BlockCtr : 91|4@0+ (1,0) [0|15] "-"  ADS,APA

BO_ 408 FC_198: 64 FC
 SG_ FC_Obj11_Dx_Vnce : 475|14@0+ (0.05,0) [0|50] "m2"  ADS,APA
 SG_ FC_Obj11_Dx : 471|12@0+ (0.05,0) [0|204.7] "m"  ADS,APA
 SG_ FC_Obj11_ClassifiedView : 460|3@0+ (1,0) [0|7] ""  ADS,APA
 SG_ FC_Obj11_Vy : 455|10@0+ (0.1,-50) [-50|50] "m/s"  ADS,APA
 SG_ FC_Obj11_Vx : 435|12@0+ (0.1,-154) [-154|50] "m/s"  ADS,APA
 SG_ FC_Obj11_Ay : 431|8@0+ (0.1,-12) [-12|12] "m/s2"  ADS,APA
 SG_ FC_Obj11_Ax : 408|9@0+ (0.1,-16) [-16|16] "m/s2"  ADS,APA
 SG_ FC_Obj11_TypeProb : 415|6@0+ (2,0) [0|100] "%"  ADS,APA
 SG_ FC_Obj11_Type : 397|3@0+ (1,0) [0|7] ""  ADS,APA
 SG_ FC_Obj11_Track_Age : 407|8@0+ (1,0) [0|254] ""  ADS,APA
 SG_ FC_Obj11_Track_ID : 391|8@0+ (1,0) [0|254] ""  ADS,APA
 SG_ FC_RollingCounter_198 : 491|4@0+ (1,0) [0|15] ""  ADS,APA
 SG_ FC_CRCCheck_198 : 503|16@0+ (1,0) [0|65535] ""  ADS,APA
 SG_ FC_obj4_Brakelight_Info : 338|1@0+ (1,0) [0|1] ""  ADS,APA
 SG_ FC_obj4_Taillight_Info : 341|3@0+ (1,0) [0|7] ""  ADS,APA
 SG_ FC_Obj4_PhiTop : 327|12@0+ (0.00025,-0.4) [-0.4|0.4] "rad"  ADS,APA
 SG_ FC_Obj4_PhiRightVel : 311|13@0+ (0.001,-4) [-4|4] "rad/s"  ADS,APA
 SG_ FC_Obj4_PhiRight : 295|13@0+ (0.00025,-1) [-1|1] "rad"  ADS,APA
 SG_ FC_Obj4_PhiMid : 279|13@0+ (0.00025,-1) [-1|1] "rad"  ADS,APA
 SG_ FC_Obj4_PhiLeftVel : 263|13@0+ (0.001,-4) [-4|4] "rad/s"  ADS,APA
 SG_ FC_Obj4_PhiLeft : 247|13@0+ (0.00025,-1) [-1|1] "rad"  ADS,APA
 SG_ FC_Obj4_PhiBottom : 227|12@0+ (0.00025,-0.4) [-0.4|0.4] "rad"  ADS,APA
 SG_ FC_Obj4_Width : 210|11@0+ (0.01,0) [0|12] "m"  ADS,APA
 SG_ FC_Obj4_Length : 204|9@0+ (0.05,0) [0|25.5] "m"  ADS,APA
 SG_ FC_Obj4_Height : 199|9@0+ (0.01,0) [0|5.11] "m"  ADS,APA
 SG_ FC_Obj4_HeadOrientation : 188|4@0+ (1,0) [0|15] ""  ADS,APA
 SG_ FC_Obj4_HeadingAngle : 183|9@0+ (0.01,-1.57) [-1.57|1.57] "rad"  ADS,APA
 SG_ FC_Obj4_ExistProb : 175|6@0+ (2,0) [0|100] "%"  ADS,APA
 SG_ FC_Obj4_Dy_Vnce : 151|10@0+ (0.02,0) [0|20] "m2"  ADS,APA
 SG_ FC_Obj4_Dy : 135|14@0+ (0.01,-80) [-80|80] "m"  ADS,APA
 SG_ FC_Obj4_Dx_Vnce : 103|14@0+ (0.05,0) [0|50] "m2"  ADS,APA
 SG_ FC_Obj4_Dx : 87|12@0+ (0.05,0) [0|204.7] "m"  ADS,APA
 SG_ FC_Obj4_ClassifiedView : 76|3@0+ (1,0) [0|7] ""  ADS,APA
 SG_ FC_Obj4_Vy : 71|10@0+ (0.1,-50) [-50|50] "m/s"  ADS,APA
 SG_ FC_Obj4_Vx : 51|12@0+ (0.1,-154) [-154|50] "m/s"  ADS,APA
 SG_ FC_Obj4_Ay : 47|8@0+ (0.1,-12) [-12|12] "m/s2"  ADS,APA
 SG_ FC_Obj4_Ax : 24|9@0+ (0.1,-16) [-16|16] "m/s2"  ADS,APA
 SG_ FC_Obj4_TypeProb : 31|6@0+ (2,0) [0|100] "%"  ADS,APA
 SG_ FC_Obj4_Type : 13|3@0+ (1,0) [0|7] ""  ADS,APA
 SG_ FC_Obj4_Track_Age : 23|8@0+ (1,0) [0|254] ""  ADS,APA
 SG_ FC_Obj4_Track_ID : 7|8@0+ (1,0) [0|254] ""  ADS,APA
 SG_ FC_Obj04_BlockCtr : 91|4@0+ (1,0) [0|15] "-"  ADS,APA

BO_ 409 FC_199: 64 FC
 SG_ FC_Obj11_PhiLeft : 355|13@0+ (0.00025,-1) [-1|1] "rad"  ADS,APA
 SG_ FC_Obj11_PhiBottom : 351|12@0+ (0.00025,-0.4) [-0.4|0.4] "rad"  ADS,APA
 SG_ FC_Obj11_Width : 466|11@0+ (0.01,0) [0|12] "m"  ADS,APA
 SG_ FC_Obj11_Length : 460|9@0+ (0.05,0) [0|25.5] "m"  ADS,APA
 SG_ FC_Obj11_Height : 455|9@0+ (0.01,0) [0|5.11] "m"  ADS,APA
 SG_ FC_Obj11_HeadOrientation : 444|4@0+ (1,0) [0|15] ""  ADS,APA
 SG_ FC_Obj11_HeadingAngle : 439|9@0+ (0.01,-1.57) [-1.57|1.57] "rad"  ADS,APA
 SG_ FC_Obj11_ExistProb : 431|6@0+ (2,0) [0|100] "%"  ADS,APA
 SG_ FC_Obj11_Dy_Vnce : 407|10@0+ (0.02,0) [0|20] "m2"  ADS,APA
 SG_ FC_Obj11_Dy : 391|14@0+ (0.01,-80) [-80|80] "m"  ADS,APA
 SG_ FC_RollingCounter_199 : 491|4@0+ (1,0) [0|15] ""  ADS,APA
 SG_ FC_CRCCheck_199 : 503|16@0+ (1,0) [0|65535] ""  ADS,APA
 SG_ FC_obj5_Brakelight_Info : 338|1@0+ (1,0) [0|1] ""  ADS,APA
 SG_ FC_obj5_Taillight_Info : 341|3@0+ (1,0) [0|7] ""  ADS,APA
 SG_ FC_Obj5_PhiTop : 327|12@0+ (0.00025,-0.4) [-0.4|0.4] "rad"  ADS,APA
 SG_ FC_Obj5_PhiRightVel : 311|13@0+ (0.001,-4) [-4|4] "rad/s"  ADS,APA
 SG_ FC_Obj5_PhiRight : 295|13@0+ (0.00025,-1) [-1|1] "rad"  ADS,APA
 SG_ FC_Obj5_PhiMid : 279|13@0+ (0.00025,-1) [-1|1] "rad"  ADS,APA
 SG_ FC_Obj5_PhiLeftVel : 263|13@0+ (0.001,-4) [-4|4] "rad/s"  ADS,APA
 SG_ FC_Obj5_PhiLeft : 247|13@0+ (0.00025,-1) [-1|1] "rad"  ADS,APA
 SG_ FC_Obj5_PhiBottom : 227|12@0+ (0.00025,-0.4) [-0.4|0.4] "rad"  ADS,APA
 SG_ FC_Obj5_Width : 210|11@0+ (0.01,0) [0|12] "m"  ADS,APA
 SG_ FC_Obj5_Length : 204|9@0+ (0.05,0) [0|25.5] "m"  ADS,APA
 SG_ FC_Obj5_Height : 199|9@0+ (0.01,0) [0|5.11] "m"  ADS,APA
 SG_ FC_Obj5_HeadOrientation : 188|4@0+ (1,0) [0|15] ""  ADS,APA
 SG_ FC_Obj5_HeadingAngle : 183|9@0+ (0.01,-1.57) [-1.57|1.57] "rad"  ADS,APA
 SG_ FC_Obj5_ExistProb : 175|6@0+ (2,0) [0|100] "%"  ADS,APA
 SG_ FC_Obj5_Dy_Vnce : 151|10@0+ (0.02,0) [0|20] "m2"  ADS,APA
 SG_ FC_Obj5_Dy : 135|14@0+ (0.01,-80) [-80|80] "m"  ADS,APA
 SG_ FC_Obj5_Dx_Vnce : 103|14@0+ (0.05,0) [0|50] "m2"  ADS,APA
 SG_ FC_Obj5_Dx : 87|12@0+ (0.05,0) [0|204.7] "m"  ADS,APA
 SG_ FC_Obj5_ClassifiedView : 76|3@0+ (1,0) [0|7] ""  ADS,APA
 SG_ FC_Obj5_Vy : 71|10@0+ (0.1,-50) [-50|50] "m/s"  ADS,APA
 SG_ FC_Obj5_Vx : 51|12@0+ (0.1,-154) [-154|50] "m/s"  ADS,APA
 SG_ FC_Obj5_Ay : 47|8@0+ (0.1,-12) [-12|12] "m/s2"  ADS,APA
 SG_ FC_Obj5_Ax : 24|9@0+ (0.1,-16) [-16|16] "m/s2"  ADS,APA
 SG_ FC_Obj5_TypeProb : 31|6@0+ (2,0) [0|100] "%"  ADS,APA
 SG_ FC_Obj5_Type : 13|3@0+ (1,0) [0|7] ""  ADS,APA
 SG_ FC_Obj5_Track_Age : 23|8@0+ (1,0) [0|254] ""  ADS,APA
 SG_ FC_Obj5_Track_ID : 7|8@0+ (1,0) [0|254] ""  ADS,APA
 SG_ FC_Obj11_BlockCtr : 495|4@0+ (1,0) [0|15] "-"  ADS,APA
 SG_ FC_Obj05_BlockCtr : 91|4@0+ (1,0) [0|15] "-"  ADS,APA

BO_ 410 FC_19A: 64 FC
 SG_ FC_obj11_Brakelight_Info : 466|1@0+ (1,0) [0|1] ""  ADS,APA
 SG_ FC_obj11_Taillight_Info : 469|3@0+ (1,0) [0|7] ""  ADS,APA
 SG_ FC_Obj11_PhiTop : 455|12@0+ (0.00025,-0.4) [-0.4|0.4] "rad"  ADS,APA
 SG_ FC_Obj11_PhiRightVel : 439|13@0+ (0.001,-4) [-4|4] "rad/s"  ADS,APA
 SG_ FC_Obj11_PhiRight : 423|13@0+ (0.00025,-1) [-1|1] "rad"  ADS,APA
 SG_ FC_Obj11_PhiMid : 407|13@0+ (0.00025,-1) [-1|1] "rad"  ADS,APA
 SG_ FC_Obj11_PhiLeftVel : 391|13@0+ (0.001,-4) [-4|4] "rad/s"  ADS,APA
 SG_ FC_RollingCounter_19A : 491|4@0+ (1,0) [0|15] ""  ADS,APA
 SG_ FC_CRCCheck_19A : 503|16@0+ (1,0) [0|65535] ""  ADS,APA
 SG_ FC_obj6_Brakelight_Info : 338|1@0+ (1,0) [0|1] ""  ADS,APA
 SG_ FC_obj6_Taillight_Info : 341|3@0+ (1,0) [0|7] ""  ADS,APA
 SG_ FC_Obj6_PhiTop : 327|12@0+ (0.00025,-0.4) [-0.4|0.4] "rad"  ADS,APA
 SG_ FC_Obj6_PhiRightVel : 311|13@0+ (0.001,-4) [-4|4] "rad/s"  ADS,APA
 SG_ FC_Obj6_PhiRight : 295|13@0+ (0.00025,-1) [-1|1] "rad"  ADS,APA
 SG_ FC_Obj6_PhiMid : 279|13@0+ (0.00025,-1) [-1|1] "rad"  ADS,APA
 SG_ FC_Obj6_PhiLeftVel : 263|13@0+ (0.001,-4) [-4|4] "rad/s"  ADS,APA
 SG_ FC_Obj6_PhiLeft : 247|13@0+ (0.00025,-1) [-1|1] "rad"  ADS,APA
 SG_ FC_Obj6_PhiBottom : 227|12@0+ (0.00025,-0.4) [-0.4|0.4] "rad"  ADS,APA
 SG_ FC_Obj6_Width : 210|11@0+ (0.01,0) [0|12] "m"  ADS,APA
 SG_ FC_Obj6_Length : 204|9@0+ (0.05,0) [0|25.5] "m"  ADS,APA
 SG_ FC_Obj6_Height : 199|9@0+ (0.01,0) [0|5.11] "m"  ADS,APA
 SG_ FC_Obj6_HeadOrientation : 188|4@0+ (1,0) [0|15] ""  ADS,APA
 SG_ FC_Obj6_HeadingAngle : 183|9@0+ (0.01,-1.57) [-1.57|1.57] "rad"  ADS,APA
 SG_ FC_Obj6_ExistProb : 175|6@0+ (2,0) [0|100] "%"  ADS,APA
 SG_ FC_Obj6_Dy_Vnce : 151|10@0+ (0.02,0) [0|20] "m2"  ADS,APA
 SG_ FC_Obj6_Dy : 135|14@0+ (0.01,-80) [-80|80] "m"  ADS,APA
 SG_ FC_Obj6_Dx_Vnce : 103|14@0+ (0.05,0) [0|50] "m2"  ADS,APA
 SG_ FC_Obj6_Dx : 87|12@0+ (0.05,0) [0|204.7] "m"  ADS,APA
 SG_ FC_Obj6_ClassifiedView : 76|3@0+ (1,0) [0|7] ""  ADS,APA
 SG_ FC_Obj6_Vy : 71|10@0+ (0.1,-50) [-50|50] "m/s"  ADS,APA
 SG_ FC_Obj6_Vx : 51|12@0+ (0.1,-154) [-154|50] "m/s"  ADS,APA
 SG_ FC_Obj6_Ay : 47|8@0+ (0.1,-12) [-12|12] "m/s2"  ADS,APA
 SG_ FC_Obj6_Ax : 24|9@0+ (0.1,-16) [-16|16] "m/s2"  ADS,APA
 SG_ FC_Obj6_TypeProb : 31|6@0+ (2,0) [0|100] "%"  ADS,APA
 SG_ FC_Obj6_Type : 13|3@0+ (1,0) [0|7] ""  ADS,APA
 SG_ FC_Obj6_Track_Age : 23|8@0+ (1,0) [0|254] ""  ADS,APA
 SG_ FC_Obj6_Track_ID : 7|8@0+ (1,0) [0|254] ""  ADS,APA
 SG_ FC_Obj06_BlockCtr : 91|4@0+ (1,0) [0|15] "-"  ADS,APA

BO_ 411 FC_19B: 64 FC
 SG_ FC_RollingCounter_19B : 491|4@0+ (1,0) [0|15] ""  ADS,APA
 SG_ FC_CRCCheck_19B : 503|16@0+ (1,0) [0|65535] ""  ADS,APA
 SG_ FC_obj7_Brakelight_Info : 338|1@0+ (1,0) [0|1] ""  ADS,APA
 SG_ FC_obj7_Taillight_Info : 341|3@0+ (1,0) [0|7] ""  ADS,APA
 SG_ FC_Obj7_PhiTop : 327|12@0+ (0.00025,-0.4) [-0.4|0.4] "rad"  ADS,APA
 SG_ FC_Obj7_PhiRightVel : 311|13@0+ (0.001,-4) [-4|4] "rad/s"  ADS,APA
 SG_ FC_Obj7_PhiRight : 295|13@0+ (0.00025,-1) [-1|1] "rad"  ADS,APA
 SG_ FC_Obj7_PhiMid : 279|13@0+ (0.00025,-1) [-1|1] "rad"  ADS,APA
 SG_ FC_Obj7_PhiLeftVel : 263|13@0+ (0.001,-4) [-4|4] "rad/s"  ADS,APA
 SG_ FC_Obj7_PhiLeft : 247|13@0+ (0.00025,-1) [-1|1] "rad"  ADS,APA
 SG_ FC_Obj7_PhiBottom : 227|12@0+ (0.00025,-0.4) [-0.4|0.4] "rad"  ADS,APA
 SG_ FC_Obj7_Width : 210|11@0+ (0.01,0) [0|12] "m"  ADS,APA
 SG_ FC_Obj7_Length : 204|9@0+ (0.05,0) [0|25.5] "m"  ADS,APA
 SG_ FC_Obj7_Height : 199|9@0+ (0.01,0) [0|5.11] "m"  ADS,APA
 SG_ FC_Obj7_HeadOrientation : 188|4@0+ (1,0) [0|15] ""  ADS,APA
 SG_ FC_Obj7_HeadingAngle : 183|9@0+ (0.01,-1.57) [-1.57|1.57] "rad"  ADS,APA
 SG_ FC_Obj7_ExistProb : 175|6@0+ (2,0) [0|100] "%"  ADS,APA
 SG_ FC_Obj7_Dy_Vnce : 151|10@0+ (0.02,0) [0|20] "m2"  ADS,APA
 SG_ FC_Obj7_Dy : 135|14@0+ (0.01,-80) [-80|80] "m"  ADS,APA
 SG_ FC_Obj7_Dx_Vnce : 103|14@0+ (0.05,0) [0|50] "m2"  ADS,APA
 SG_ FC_Obj7_Dx : 87|12@0+ (0.05,0) [0|204.7] "m"  ADS,APA
 SG_ FC_Obj7_ClassifiedView : 76|3@0+ (1,0) [0|7] ""  ADS,APA
 SG_ FC_Obj7_Vy : 71|10@0+ (0.1,-50) [-50|50] "m/s"  ADS,APA
 SG_ FC_Obj7_Vx : 51|12@0+ (0.1,-154) [-154|50] "m/s"  ADS,APA
 SG_ FC_Obj7_Ay : 47|8@0+ (0.1,-12) [-12|12] "m/s2"  ADS,APA
 SG_ FC_Obj7_Ax : 24|9@0+ (0.1,-16) [-16|16] "m/s2"  ADS,APA
 SG_ FC_Obj7_TypeProb : 31|6@0+ (2,0) [0|100] "%"  ADS,APA
 SG_ FC_Obj7_Type : 13|3@0+ (1,0) [0|7] ""  ADS,APA
 SG_ FC_Obj7_Track_Age : 23|8@0+ (1,0) [0|254] ""  ADS,APA
 SG_ FC_Obj7_Track_ID : 7|8@0+ (1,0) [0|254] ""  ADS,APA
 SG_ FC_Obj07_BlockCtr : 91|4@0+ (1,0) [0|15] "-"  ADS,APA

BO_ 412 FC_19C: 64 FC
 SG_ FC_RollingCounter_19C : 491|4@0+ (1,0) [0|15] ""  ADS,APA
 SG_ FC_CRCCheck_19C : 503|16@0+ (1,0) [0|65535] ""  ADS,APA
 SG_ FC_obj8_Brakelight_Info : 338|1@0+ (1,0) [0|1] ""  ADS,APA
 SG_ FC_obj8_Taillight_Info : 341|3@0+ (1,0) [0|7] ""  ADS,APA
 SG_ FC_Obj8_PhiTop : 327|12@0+ (0.00025,-0.4) [-0.4|0.4] "rad"  ADS,APA
 SG_ FC_Obj8_PhiRightVel : 311|13@0+ (0.001,-4) [-4|4] "rad/s"  ADS,APA
 SG_ FC_Obj8_PhiRight : 295|13@0+ (0.00025,-1) [-1|1] "rad"  ADS,APA
 SG_ FC_Obj8_PhiMid : 279|13@0+ (0.00025,-1) [-1|1] "rad"  ADS,APA
 SG_ FC_Obj8_PhiLeftVel : 263|13@0+ (0.001,-4) [-4|4] "rad/s"  ADS,APA
 SG_ FC_Obj8_PhiLeft : 247|13@0+ (0.00025,-1) [-1|1] "rad"  ADS,APA
 SG_ FC_Obj8_PhiBottom : 227|12@0+ (0.00025,-0.4) [-0.4|0.4] "rad"  ADS,APA
 SG_ FC_Obj8_Width : 210|11@0+ (0.01,0) [0|12] "m"  ADS,APA
 SG_ FC_Obj8_Length : 204|9@0+ (0.05,0) [0|25.5] "m"  ADS,APA
 SG_ FC_Obj8_Height : 199|9@0+ (0.01,0) [0|5.11] "m"  ADS,APA
 SG_ FC_Obj8_HeadOrientation : 188|4@0+ (1,0) [0|15] ""  ADS,APA
 SG_ FC_Obj8_HeadingAngle : 183|9@0+ (0.01,-1.57) [-1.57|1.57] "rad"  ADS,APA
 SG_ FC_Obj8_ExistProb : 175|6@0+ (2,0) [0|100] "%"  ADS,APA
 SG_ FC_Obj8_Dy_Vnce : 151|10@0+ (0.02,0) [0|20] "m2"  ADS,APA
 SG_ FC_Obj8_Dy : 135|14@0+ (0.01,-80) [-80|80] "m"  ADS,APA
 SG_ FC_Obj8_Dx_Vnce : 103|14@0+ (0.05,0) [0|50] "m2"  ADS,APA
 SG_ FC_Obj8_Dx : 87|12@0+ (0.05,0) [0|204.7] "m"  ADS,APA
 SG_ FC_Obj8_ClassifiedView : 76|3@0+ (1,0) [0|7] ""  ADS,APA
 SG_ FC_Obj8_Vy : 71|10@0+ (0.1,-50) [-50|50] "m/s"  ADS,APA
 SG_ FC_Obj8_Vx : 51|12@0+ (0.1,-154) [-154|50] "m/s"  ADS,APA
 SG_ FC_Obj8_Ay : 47|8@0+ (0.1,-12) [-12|12] "m/s2"  ADS,APA
 SG_ FC_Obj8_Ax : 24|9@0+ (0.1,-16) [-16|16] "m/s2"  ADS,APA
 SG_ FC_Obj8_TypeProb : 31|6@0+ (2,0) [0|100] "%"  ADS,APA
 SG_ FC_Obj8_Type : 13|3@0+ (1,0) [0|7] ""  ADS,APA
 SG_ FC_Obj8_Track_Age : 23|8@0+ (1,0) [0|254] ""  ADS,APA
 SG_ FC_Obj8_Track_ID : 7|8@0+ (1,0) [0|254] ""  ADS,APA
 SG_ FC_Obj08_BlockCtr : 91|4@0+ (1,0) [0|15] "-"  ADS,APA

BO_ 413 FC_19D: 64 FC
 SG_ FC_RollingCounter_19D : 491|4@0+ (1,0) [0|15] ""  ADS,APA
 SG_ FC_CRCCheck_19D : 503|16@0+ (1,0) [0|65535] ""  ADS,APA
 SG_ FC_obj10_Brakelight_Info : 338|1@0+ (1,0) [0|1] ""  ADS,APA
 SG_ FC_obj10_Taillight_Info : 341|3@0+ (1,0) [0|7] ""  ADS,APA
 SG_ FC_Obj10_PhiTop : 327|12@0+ (0.00025,-0.4) [-0.4|0.4] "rad"  ADS,APA
 SG_ FC_Obj10_PhiRightVel : 311|13@0+ (0.001,-4) [-4|4] "rad/s"  ADS,APA
 SG_ FC_Obj10_PhiRight : 295|13@0+ (0.00025,-1) [-1|1] "rad"  ADS,APA
 SG_ FC_Obj10_PhiMid : 279|13@0+ (0.00025,-1) [-1|1] "rad"  ADS,APA
 SG_ FC_Obj10_PhiLeftVel : 263|13@0+ (0.001,-4) [-4|4] "rad/s"  ADS,APA
 SG_ FC_Obj10_PhiLeft : 247|13@0+ (0.00025,-1) [-1|1] "rad"  ADS,APA
 SG_ FC_Obj10_PhiBottom : 227|12@0+ (0.00025,-0.4) [-0.4|0.4] "rad"  ADS,APA
 SG_ FC_Obj10_Width : 210|11@0+ (0.01,0) [0|12] "m"  ADS,APA
 SG_ FC_Obj10_Length : 204|9@0+ (0.05,0) [0|25.5] "m"  ADS,APA
 SG_ FC_Obj10_Height : 199|9@0+ (0.01,0) [0|5.11] "m"  ADS,APA
 SG_ FC_Obj10_HeadOrientation : 188|4@0+ (1,0) [0|15] ""  ADS,APA
 SG_ FC_Obj10_HeadingAngle : 183|9@0+ (0.01,-1.57) [-1.57|1.57] "rad"  ADS,APA
 SG_ FC_Obj10_ExistProb : 175|6@0+ (2,0) [0|100] "%"  ADS,APA
 SG_ FC_Obj10_Dy_Vnce : 151|10@0+ (0.02,0) [0|20] "m2"  ADS,APA
 SG_ FC_Obj10_Dy : 135|14@0+ (0.01,-80) [-80|80] "m"  ADS,APA
 SG_ FC_Obj10_Dx_Vnce : 103|14@0+ (0.05,0) [0|50] "m2"  ADS,APA
 SG_ FC_Obj10_Dx : 87|12@0+ (0.05,0) [0|204.7] "m"  ADS,APA
 SG_ FC_Obj10_ClassifiedView : 76|3@0+ (1,0) [0|7] ""  ADS,APA
 SG_ FC_Obj10_Vy : 71|10@0+ (0.1,-50) [-50|50] "m/s"  ADS,APA
 SG_ FC_Obj10_Vx : 51|12@0+ (0.1,-154) [-154|50] "m/s"  ADS,APA
 SG_ FC_Obj10_Ay : 47|8@0+ (0.1,-12) [-12|12] "m/s2"  ADS,APA
 SG_ FC_Obj10_Ax : 24|9@0+ (0.1,-16) [-16|16] "m/s2"  ADS,APA
 SG_ FC_Obj10_TypeProb : 31|6@0+ (2,0) [0|100] "%"  ADS,APA
 SG_ FC_Obj10_Type : 13|3@0+ (1,0) [0|7] ""  ADS,APA
 SG_ FC_Obj10_Track_Age : 23|8@0+ (1,0) [0|254] ""  ADS,APA
 SG_ FC_Obj10_Track_ID : 7|8@0+ (1,0) [0|254] ""  ADS,APA
 SG_ FC_Obj10_BlockCtr : 91|4@0+ (1,0) [0|15] "-"  ADS,APA

BO_ 414 FC_19E: 64 FC
 SG_ FC_RollingCounter_19E : 491|4@0+ (1,0) [0|15] ""  ADS,APA
 SG_ FC_CRCCheck_19E : 503|16@0+ (1,0) [0|65535] ""  ADS,APA
 SG_ FC_obj12_Brakelight_Info : 338|1@0+ (1,0) [0|1] ""  ADS,APA
 SG_ FC_obj12_Taillight_Info : 341|3@0+ (1,0) [0|7] ""  ADS,APA
 SG_ FC_Obj12_PhiTop : 327|12@0+ (0.00025,-0.4) [-0.4|0.4] "rad"  ADS,APA
 SG_ FC_Obj12_PhiRightVel : 311|13@0+ (0.001,-4) [-4|4] "rad/s"  ADS,APA
 SG_ FC_Obj12_PhiRight : 295|13@0+ (0.00025,-1) [-1|1] "rad"  ADS,APA
 SG_ FC_Obj12_PhiMid : 279|13@0+ (0.00025,-1) [-1|1] "rad"  ADS,APA
 SG_ FC_Obj12_PhiLeftVel : 263|13@0+ (0.001,-4) [-4|4] "rad/s"  ADS,APA
 SG_ FC_Obj12_PhiLeft : 247|13@0+ (0.00025,-1) [-1|1] "rad"  ADS,APA
 SG_ FC_Obj12_PhiBottom : 227|12@0+ (0.00025,-0.4) [-0.4|0.4] "rad"  ADS,APA
 SG_ FC_Obj12_Width : 210|11@0+ (0.01,0) [0|12] "m"  ADS,APA
 SG_ FC_Obj12_Length : 204|9@0+ (0.05,0) [0|25.5] "m"  ADS,APA
 SG_ FC_Obj12_Height : 199|9@0+ (0.01,0) [0|5.11] "m"  ADS,APA
 SG_ FC_Obj12_HeadOrientation : 188|4@0+ (1,0) [0|15] ""  ADS,APA
 SG_ FC_Obj12_HeadingAngle : 183|9@0+ (0.01,-1.57) [-1.57|1.57] "rad"  ADS,APA
 SG_ FC_Obj12_ExistProb : 175|6@0+ (2,0) [0|100] "%"  ADS,APA
 SG_ FC_Obj12_Dy_Vnce : 151|10@0+ (0.02,0) [0|20] "m2"  ADS,APA
 SG_ FC_Obj12_Dy : 135|14@0+ (0.01,-80) [-80|80] "m"  ADS,APA
 SG_ FC_Obj12_Dx_Vnce : 103|14@0+ (0.05,0) [0|50] "m2"  ADS,APA
 SG_ FC_Obj12_Dx : 87|12@0+ (0.05,0) [0|204.7] "m"  ADS,APA
 SG_ FC_Obj12_ClassifiedView : 76|3@0+ (1,0) [0|7] ""  ADS,APA
 SG_ FC_Obj12_Vy : 71|10@0+ (0.1,-50) [-50|50] "m/s"  ADS,APA
 SG_ FC_Obj12_Vx : 51|12@0+ (0.1,-154) [-154|50] "m/s"  ADS,APA
 SG_ FC_Obj12_Ay : 47|8@0+ (0.1,-12) [-12|12] "m/s2"  ADS,APA
 SG_ FC_Obj12_Ax : 24|9@0+ (0.1,-16) [-16|16] "m/s2"  ADS,APA
 SG_ FC_Obj12_TypeProb : 31|6@0+ (2,0) [0|100] "%"  ADS,APA
 SG_ FC_Obj12_Type : 13|3@0+ (1,0) [0|7] ""  ADS,APA
 SG_ FC_Obj12_Track_Age : 23|8@0+ (1,0) [0|254] ""  ADS,APA
 SG_ FC_Obj12_Track_ID : 7|8@0+ (1,0) [0|254] ""  ADS,APA
 SG_ FC_Obj12_BlockCtr : 91|4@0+ (1,0) [0|15] "-"  ADS,APA

BO_ 415 FC_19F: 64 FC
 SG_ FC_RollingCounter_19F : 491|4@0+ (1,0) [0|15] ""  ADS,APA
 SG_ FC_CRCCheck_19F : 503|16@0+ (1,0) [0|65535] ""  ADS,APA
 SG_ FC_obj13_Brakelight_Info : 338|1@0+ (1,0) [0|1] ""  ADS,APA
 SG_ FC_obj13_Taillight_Info : 341|3@0+ (1,0) [0|7] ""  ADS,APA
 SG_ FC_Obj13_PhiTop : 327|12@0+ (0.00025,-0.4) [-0.4|0.4] "rad"  ADS,APA
 SG_ FC_Obj13_PhiRightVel : 311|13@0+ (0.001,-4) [-4|4] "rad/s"  ADS,APA
 SG_ FC_Obj13_PhiRight : 295|13@0+ (0.00025,-1) [-1|1] "rad"  ADS,APA
 SG_ FC_Obj13_PhiMid : 279|13@0+ (0.00025,-1) [-1|1] "rad"  ADS,APA
 SG_ FC_Obj13_PhiLeftVel : 263|13@0+ (0.001,-4) [-4|4] "rad/s"  ADS,APA
 SG_ FC_Obj13_PhiLeft : 247|13@0+ (0.00025,-1) [-1|1] "rad"  ADS,APA
 SG_ FC_Obj13_PhiBottom : 227|12@0+ (0.00025,-0.4) [-0.4|0.4] "rad"  ADS,APA
 SG_ FC_Obj13_Width : 210|11@0+ (0.01,0) [0|12] "m"  ADS,APA
 SG_ FC_Obj13_Length : 204|9@0+ (0.05,0) [0|25.5] "m"  ADS,APA
 SG_ FC_Obj13_Height : 199|9@0+ (0.01,0) [0|5.11] "m"  ADS,APA
 SG_ FC_Obj13_HeadOrientation : 188|4@0+ (1,0) [0|15] ""  ADS,APA
 SG_ FC_Obj13_HeadingAngle : 183|9@0+ (0.01,-1.57) [-1.57|1.57] "rad"  ADS,APA
 SG_ FC_Obj13_ExistProb : 175|6@0+ (2,0) [0|100] "%"  ADS,APA
 SG_ FC_Obj13_Dy_Vnce : 151|10@0+ (0.02,0) [0|20] "m2"  ADS,APA
 SG_ FC_Obj13_Dy : 135|14@0+ (0.01,-80) [-80|80] "m"  ADS,APA
 SG_ FC_Obj13_Dx_Vnce : 103|14@0+ (0.05,0) [0|50] "m2"  ADS,APA
 SG_ FC_Obj13_Dx : 87|12@0+ (0.05,0) [0|204.7] "m"  ADS,APA
 SG_ FC_Obj13_ClassifiedView : 76|3@0+ (1,0) [0|7] ""  ADS,APA
 SG_ FC_Obj13_Vy : 71|10@0+ (0.1,-50) [-50|50] "m/s"  ADS,APA
 SG_ FC_Obj13_Vx : 51|12@0+ (0.1,-154) [-154|50] "m/s"  ADS,APA
 SG_ FC_Obj13_Ay : 47|8@0+ (0.1,-12) [-12|12] "m/s2"  ADS,APA
 SG_ FC_Obj13_Ax : 24|9@0+ (0.1,-16) [-16|16] "m/s2"  ADS,APA
 SG_ FC_Obj13_TypeProb : 31|6@0+ (2,0) [0|100] "%"  ADS,APA
 SG_ FC_Obj13_Type : 13|3@0+ (1,0) [0|7] ""  ADS,APA
 SG_ FC_Obj13_Track_Age : 23|8@0+ (1,0) [0|254] ""  ADS,APA
 SG_ FC_Obj13_Track_ID : 7|8@0+ (1,0) [0|254] ""  ADS,APA
 SG_ FC_Obj13_BlockCtr : 91|4@0+ (1,0) [0|15] "-"  ADS,APA

BO_ 416 FC_1A0: 64 FC
 SG_ FC_RollingCounter_1A0 : 491|4@0+ (1,0) [0|15] ""  ADS,APA
 SG_ FC_CRCCheck_1A0 : 503|16@0+ (1,0) [0|65535] ""  ADS,APA
 SG_ FC_obj14_Brakelight_Info : 338|1@0+ (1,0) [0|1] ""  ADS,APA
 SG_ FC_obj14_Taillight_Info : 341|3@0+ (1,0) [0|7] ""  ADS,APA
 SG_ FC_Obj14_PhiTop : 327|12@0+ (0.00025,-0.4) [-0.4|0.4] "rad"  ADS,APA
 SG_ FC_Obj14_PhiRightVel : 311|13@0+ (0.001,-4) [-4|4] "rad/s"  ADS,APA
 SG_ FC_Obj14_PhiRight : 295|13@0+ (0.00025,-1) [-1|1] "rad"  ADS,APA
 SG_ FC_Obj14_PhiMid : 279|13@0+ (0.00025,-1) [-1|1] "rad"  ADS,APA
 SG_ FC_Obj14_PhiLeftVel : 263|13@0+ (0.001,-4) [-4|4] "rad/s"  ADS,APA
 SG_ FC_Obj14_PhiLeft : 247|13@0+ (0.00025,-1) [-1|1] "rad"  ADS,APA
 SG_ FC_Obj14_PhiBottom : 227|12@0+ (0.00025,-0.4) [-0.4|0.4] "rad"  ADS,APA
 SG_ FC_Obj14_Width : 210|11@0+ (0.01,0) [0|12] "m"  ADS,APA
 SG_ FC_Obj14_Length : 204|9@0+ (0.05,0) [0|25.5] "m"  ADS,APA
 SG_ FC_Obj14_Height : 199|9@0+ (0.01,0) [0|5.11] "m"  ADS,APA
 SG_ FC_Obj14_HeadOrientation : 188|4@0+ (1,0) [0|15] ""  ADS,APA
 SG_ FC_Obj14_HeadingAngle : 183|9@0+ (0.01,-1.57) [-1.57|1.57] "rad"  ADS,APA
 SG_ FC_Obj14_ExistProb : 175|6@0+ (2,0) [0|100] "%"  ADS,APA
 SG_ FC_Obj14_Dy_Vnce : 151|10@0+ (0.02,0) [0|20] "m2"  ADS,APA
 SG_ FC_Obj14_Dy : 135|14@0+ (0.01,-80) [-80|80] "m"  ADS,APA
 SG_ FC_Obj14_Dx_Vnce : 103|14@0+ (0.05,0) [0|50] "m2"  ADS,APA
 SG_ FC_Obj14_Dx : 87|12@0+ (0.05,0) [0|204.7] "m"  ADS,APA
 SG_ FC_Obj14_ClassifiedView : 76|3@0+ (1,0) [0|7] ""  ADS,APA
 SG_ FC_Obj14_Vy : 71|10@0+ (0.1,-50) [-50|50] "m/s"  ADS,APA
 SG_ FC_Obj14_Vx : 51|12@0+ (0.1,-154) [-154|50] "m/s"  ADS,APA
 SG_ FC_Obj14_Ay : 47|8@0+ (0.1,-12) [-12|12] "m/s2"  ADS,APA
 SG_ FC_Obj14_Ax : 24|9@0+ (0.1,-16) [-16|16] "m/s2"  ADS,APA
 SG_ FC_Obj14_TypeProb : 31|6@0+ (2,0) [0|100] "%"  ADS,APA
 SG_ FC_Obj14_Type : 13|3@0+ (1,0) [0|7] ""  ADS,APA
 SG_ FC_Obj14_Track_Age : 23|8@0+ (1,0) [0|254] ""  ADS,APA
 SG_ FC_Obj14_Track_ID : 7|8@0+ (1,0) [0|254] ""  ADS,APA
 SG_ FC_Obj14_BlockCtr : 91|4@0+ (1,0) [0|15] "-"  ADS,APA

BO_ 417 FC_1A1: 64 FC
 SG_ FC_RollingCounter_1A1 : 491|4@0+ (1,0) [0|15] ""  ADS,APA
 SG_ FC_CRCCheck_1A1 : 503|16@0+ (1,0) [0|65535] ""  ADS,APA
 SG_ FC_obj15_Brakelight_Info : 338|1@0+ (1,0) [0|1] ""  ADS,APA
 SG_ FC_obj15_Taillight_Info : 341|3@0+ (1,0) [0|7] ""  ADS,APA
 SG_ FC_Obj15_PhiTop : 327|12@0+ (0.00025,-0.4) [-0.4|0.4] "rad"  ADS,APA
 SG_ FC_Obj15_PhiRightVel : 311|13@0+ (0.001,-4) [-4|4] "rad/s"  ADS,APA
 SG_ FC_Obj15_PhiRight : 295|13@0+ (0.00025,-1) [-1|1] "rad"  ADS,APA
 SG_ FC_Obj15_PhiMid : 279|13@0+ (0.00025,-1) [-1|1] "rad"  ADS,APA
 SG_ FC_Obj15_PhiLeftVel : 263|13@0+ (0.001,-4) [-4|4] "rad/s"  ADS,APA
 SG_ FC_Obj15_PhiLeft : 247|13@0+ (0.00025,-1) [-1|1] "rad"  ADS,APA
 SG_ FC_Obj15_PhiBottom : 227|12@0+ (0.00025,-0.4) [-0.4|0.4] "rad"  ADS,APA
 SG_ FC_Obj15_Width : 210|11@0+ (0.01,0) [0|12] "m"  ADS,APA
 SG_ FC_Obj15_Length : 204|9@0+ (0.05,0) [0|25.5] "m"  ADS,APA
 SG_ FC_Obj15_Height : 199|9@0+ (0.01,0) [0|5.11] "m"  ADS,APA
 SG_ FC_Obj15_HeadOrientation : 188|4@0+ (1,0) [0|15] ""  ADS,APA
 SG_ FC_Obj15_HeadingAngle : 183|9@0+ (0.01,-1.57) [-1.57|1.57] "rad"  ADS,APA
 SG_ FC_Obj15_ExistProb : 175|6@0+ (2,0) [0|100] "%"  ADS,APA
 SG_ FC_Obj15_Dy_Vnce : 151|10@0+ (0.02,0) [0|20] "m2"  ADS,APA
 SG_ FC_Obj15_Dy : 135|14@0+ (0.01,-80) [-80|80] "m"  ADS,APA
 SG_ FC_Obj15_Dx_Vnce : 103|14@0+ (0.05,0) [0|50] "m2"  ADS,APA
 SG_ FC_Obj15_Dx : 87|12@0+ (0.05,0) [0|204.7] "m"  ADS,APA
 SG_ FC_Obj15_ClassifiedView : 76|3@0+ (1,0) [0|7] ""  ADS,APA
 SG_ FC_Obj15_Vy : 71|10@0+ (0.1,-50) [-50|50] "m/s"  ADS,APA
 SG_ FC_Obj15_Vx : 51|12@0+ (0.1,-154) [-154|50] "m/s"  ADS,APA
 SG_ FC_Obj15_Ay : 47|8@0+ (0.1,-12) [-12|12] "m/s2"  ADS,APA
 SG_ FC_Obj15_Ax : 24|9@0+ (0.1,-16) [-16|16] "m/s2"  ADS,APA
 SG_ FC_Obj15_TypeProb : 31|6@0+ (2,0) [0|100] "%"  ADS,APA
 SG_ FC_Obj15_Type : 13|3@0+ (1,0) [0|7] ""  ADS,APA
 SG_ FC_Obj15_Track_Age : 23|8@0+ (1,0) [0|254] ""  ADS,APA
 SG_ FC_Obj15_Track_ID : 7|8@0+ (1,0) [0|254] ""  ADS,APA
 SG_ FC_Obj15_BlockCtr : 91|4@0+ (1,0) [0|15] "-"  ADS,APA

BO_ 418 FC_1A2: 64 FC
 SG_ FC_RollingCounter_1A2 : 491|4@0+ (1,0) [0|15] ""  ADS,APA
 SG_ FC_CRCCheck_1A2 : 503|16@0+ (1,0) [0|65535] ""  ADS,APA
 SG_ FC_obj16_Brakelight_Info : 338|1@0+ (1,0) [0|1] ""  ADS,APA
 SG_ FC_obj16_Taillight_Info : 341|3@0+ (1,0) [0|7] ""  ADS,APA
 SG_ FC_Obj16_PhiTop : 327|12@0+ (0.00025,-0.4) [-0.4|0.4] "rad"  ADS,APA
 SG_ FC_Obj16_PhiRightVel : 311|13@0+ (0.001,-4) [-4|4] "rad/s"  ADS,APA
 SG_ FC_Obj16_PhiRight : 295|13@0+ (0.00025,-1) [-1|1] "rad"  ADS,APA
 SG_ FC_Obj16_PhiMid : 279|13@0+ (0.00025,-1) [-1|1] "rad"  ADS,APA
 SG_ FC_Obj16_PhiLeftVel : 263|13@0+ (0.001,-4) [-4|4] "rad/s"  ADS,APA
 SG_ FC_Obj16_PhiLeft : 247|13@0+ (0.00025,-1) [-1|1] "rad"  ADS,APA
 SG_ FC_Obj16_PhiBottom : 227|12@0+ (0.00025,-0.4) [-0.4|0.4] "rad"  ADS,APA
 SG_ FC_Obj16_Width : 210|11@0+ (0.01,0) [0|12] "m"  ADS,APA
 SG_ FC_Obj16_Length : 204|9@0+ (0.05,0) [0|25.5] "m"  ADS,APA
 SG_ FC_Obj16_Height : 199|9@0+ (0.01,0) [0|5.11] "m"  ADS,APA
 SG_ FC_Obj16_HeadOrientation : 188|4@0+ (1,0) [0|15] ""  ADS,APA
 SG_ FC_Obj16_HeadingAngle : 183|9@0+ (0.01,-1.57) [-1.57|1.57] "rad"  ADS,APA
 SG_ FC_Obj16_ExistProb : 175|6@0+ (2,0) [0|100] "%"  ADS,APA
 SG_ FC_Obj16_Dy_Vnce : 151|10@0+ (0.02,0) [0|20] "m2"  ADS,APA
 SG_ FC_Obj16_Dy : 135|14@0+ (0.01,-80) [-80|80] "m"  ADS,APA
 SG_ FC_Obj16_Dx_Vnce : 103|14@0+ (0.05,0) [0|50] "m2"  ADS,APA
 SG_ FC_Obj16_Dx : 87|12@0+ (0.05,0) [0|204.7] "m"  ADS,APA
 SG_ FC_Obj16_ClassifiedView : 76|3@0+ (1,0) [0|7] ""  ADS,APA
 SG_ FC_Obj16_Vy : 71|10@0+ (0.1,-50) [-50|50] "m/s"  ADS,APA
 SG_ FC_Obj16_Vx : 51|12@0+ (0.1,-154) [-154|50] "m/s"  ADS,APA
 SG_ FC_Obj16_Ay : 47|8@0+ (0.1,-12) [-12|12] "m/s2"  ADS,APA
 SG_ FC_Obj16_Ax : 24|9@0+ (0.1,-16) [-16|16] "m/s2"  ADS,APA
 SG_ FC_Obj16_TypeProb : 31|6@0+ (2,0) [0|100] "%"  ADS,APA
 SG_ FC_Obj16_Type : 13|3@0+ (1,0) [0|7] ""  ADS,APA
 SG_ FC_Obj16_Track_Age : 23|8@0+ (1,0) [0|254] ""  ADS,APA
 SG_ FC_Obj16_Track_ID : 7|8@0+ (1,0) [0|254] ""  ADS,APA
 SG_ FC_Obj16_BlockCtr : 91|4@0+ (1,0) [0|15] "-"  ADS,APA

BO_ 419 FC_1A3: 64 FC
 SG_ FC_RollingCounter_1A3 : 491|4@0+ (1,0) [0|15] ""  ADS,APA
 SG_ FC_CRCCheck_1A3 : 503|16@0+ (1,0) [0|65535] ""  ADS,APA
 SG_ FC_obj17_Brakelight_Info : 338|1@0+ (1,0) [0|1] ""  ADS,APA
 SG_ FC_obj17_Taillight_Info : 341|3@0+ (1,0) [0|7] ""  ADS,APA
 SG_ FC_Obj17_PhiTop : 327|12@0+ (0.00025,-0.4) [-0.4|0.4] "rad"  ADS,APA
 SG_ FC_Obj17_PhiRightVel : 311|13@0+ (0.001,-4) [-4|4] "rad/s"  ADS,APA
 SG_ FC_Obj17_PhiRight : 295|13@0+ (0.00025,-1) [-1|1] "rad"  ADS,APA
 SG_ FC_Obj17_PhiMid : 279|13@0+ (0.00025,-1) [-1|1] "rad"  ADS,APA
 SG_ FC_Obj17_PhiLeftVel : 263|13@0+ (0.001,-4) [-4|4] "rad/s"  ADS,APA
 SG_ FC_Obj17_PhiLeft : 247|13@0+ (0.00025,-1) [-1|1] "rad"  ADS,APA
 SG_ FC_Obj17_PhiBottom : 227|12@0+ (0.00025,-0.4) [-0.4|0.4] "rad"  ADS,APA
 SG_ FC_Obj17_Width : 210|11@0+ (0.01,0) [0|12] "m"  ADS,APA
 SG_ FC_Obj17_Length : 204|9@0+ (0.05,0) [0|25.5] "m"  ADS,APA
 SG_ FC_Obj17_Height : 199|9@0+ (0.01,0) [0|5.11] "m"  ADS,APA
 SG_ FC_Obj17_HeadOrientation : 188|4@0+ (1,0) [0|15] ""  ADS,APA
 SG_ FC_Obj17_HeadingAngle : 183|9@0+ (0.01,-1.57) [-1.57|1.57] "rad"  ADS,APA
 SG_ FC_Obj17_ExistProb : 175|6@0+ (2,0) [0|100] "%"  ADS,APA
 SG_ FC_Obj17_Dy_Vnce : 151|10@0+ (0.02,0) [0|20] "m2"  ADS,APA
 SG_ FC_Obj17_Dy : 135|14@0+ (0.01,-80) [-80|80] "m"  ADS,APA
 SG_ FC_Obj17_Dx_Vnce : 103|14@0+ (0.05,0) [0|50] "m2"  ADS,APA
 SG_ FC_Obj17_Dx : 87|12@0+ (0.05,0) [0|204.7] "m"  ADS,APA
 SG_ FC_Obj17_ClassifiedView : 76|3@0+ (1,0) [0|7] ""  ADS,APA
 SG_ FC_Obj17_Vy : 71|10@0+ (0.1,-50) [-50|50] "m/s"  ADS,APA
 SG_ FC_Obj17_Vx : 51|12@0+ (0.1,-154) [-154|50] "m/s"  ADS,APA
 SG_ FC_Obj17_Ay : 47|8@0+ (0.1,-12) [-12|12] "m/s2"  ADS,APA
 SG_ FC_Obj17_Ax : 24|9@0+ (0.1,-16) [-16|16] "m/s2"  ADS,APA
 SG_ FC_Obj17_TypeProb : 31|6@0+ (2,0) [0|100] "%"  ADS,APA
 SG_ FC_Obj17_Type : 13|3@0+ (1,0) [0|7] ""  ADS,APA
 SG_ FC_Obj17_Track_Age : 23|8@0+ (1,0) [0|254] ""  ADS,APA
 SG_ FC_Obj17_Track_ID : 7|8@0+ (1,0) [0|254] ""  ADS,APA
 SG_ FC_Obj17_BlockCtr : 91|4@0+ (1,0) [0|15] "-"  ADS,APA

BO_ 420 FC_1A4: 64 FC
 SG_ FC_RollingCounter_1A4 : 491|4@0+ (1,0) [0|15] ""  ADS,APA
 SG_ FC_CRCCheck_1A4 : 503|16@0+ (1,0) [0|65535] ""  ADS,APA
 SG_ FC_obj18_Brakelight_Info : 338|1@0+ (1,0) [0|1] ""  ADS,APA
 SG_ FC_obj18_Taillight_Info : 341|3@0+ (1,0) [0|7] ""  ADS,APA
 SG_ FC_Obj18_PhiTop : 327|12@0+ (0.00025,-0.4) [-0.4|0.4] "rad"  ADS,APA
 SG_ FC_Obj18_PhiRightVel : 311|13@0+ (0.001,-4) [-4|4] "rad/s"  ADS,APA
 SG_ FC_Obj18_PhiRight : 295|13@0+ (0.00025,-1) [-1|1] "rad"  ADS,APA
 SG_ FC_Obj18_PhiMid : 279|13@0+ (0.00025,-1) [-1|1] "rad"  ADS,APA
 SG_ FC_Obj18_PhiLeftVel : 263|13@0+ (0.001,-4) [-4|4] "rad/s"  ADS,APA
 SG_ FC_Obj18_PhiLeft : 247|13@0+ (0.00025,-1) [-1|1] "rad"  ADS,APA
 SG_ FC_Obj18_PhiBottom : 227|12@0+ (0.00025,-0.4) [-0.4|0.4] "rad"  ADS,APA
 SG_ FC_Obj18_Width : 210|11@0+ (0.01,0) [0|12] "m"  ADS,APA
 SG_ FC_Obj18_Length : 204|9@0+ (0.05,0) [0|25.5] "m"  ADS,APA
 SG_ FC_Obj18_Height : 199|9@0+ (0.01,0) [0|5.11] "m"  ADS,APA
 SG_ FC_Obj18_HeadOrientation : 188|4@0+ (1,0) [0|15] ""  ADS,APA
 SG_ FC_Obj18_HeadingAngle : 183|9@0+ (0.01,-1.57) [-1.57|1.57] "rad"  ADS,APA
 SG_ FC_Obj18_ExistProb : 175|6@0+ (2,0) [0|100] "%"  ADS,APA
 SG_ FC_Obj18_Dy_Vnce : 151|10@0+ (0.02,0) [0|20] "m2"  ADS,APA
 SG_ FC_Obj18_Dy : 135|14@0+ (0.01,-80) [-80|80] "m"  ADS,APA
 SG_ FC_Obj18_Dx_Vnce : 103|14@0+ (0.05,0) [0|50] "m2"  ADS,APA
 SG_ FC_Obj18_Dx : 87|12@0+ (0.05,0) [0|204.7] "m"  ADS,APA
 SG_ FC_Obj18_ClassifiedView : 76|3@0+ (1,0) [0|7] ""  ADS,APA
 SG_ FC_Obj18_Vy : 71|10@0+ (0.1,-50) [-50|50] "m/s"  ADS,APA
 SG_ FC_Obj18_Vx : 51|12@0+ (0.1,-154) [-154|50] "m/s"  ADS,APA
 SG_ FC_Obj18_Ay : 47|8@0+ (0.1,-12) [-12|12] "m/s2"  ADS,APA
 SG_ FC_Obj18_Ax : 24|9@0+ (0.1,-16) [-16|16] "m/s2"  ADS,APA
 SG_ FC_Obj18_TypeProb : 31|6@0+ (2,0) [0|100] "%"  ADS,APA
 SG_ FC_Obj18_Type : 13|3@0+ (1,0) [0|7] ""  ADS,APA
 SG_ FC_Obj18_Track_Age : 23|8@0+ (1,0) [0|254] ""  ADS,APA
 SG_ FC_Obj18_Track_ID : 7|8@0+ (1,0) [0|254] ""  ADS,APA
 SG_ FC_Obj18_BlockCtr : 91|4@0+ (1,0) [0|15] "-"  ADS,APA

BO_ 421 FC_1A5: 64 FC
 SG_ FC_RollingCounter_1A5 : 491|4@0+ (1,0) [0|15] ""  ADS,APA
 SG_ FC_CRCCheck_1A5 : 503|16@0+ (1,0) [0|65535] ""  ADS,APA
 SG_ FC_obj19_Brakelight_Info : 338|1@0+ (1,0) [0|1] ""  ADS,APA
 SG_ FC_obj19_Taillight_Info : 341|3@0+ (1,0) [0|7] ""  ADS,APA
 SG_ FC_Obj19_PhiTop : 327|12@0+ (0.00025,-0.4) [-0.4|0.4] "rad"  ADS,APA
 SG_ FC_Obj19_PhiRightVel : 311|13@0+ (0.001,-4) [-4|4] "rad/s"  ADS,APA
 SG_ FC_Obj19_PhiRight : 295|13@0+ (0.00025,-1) [-1|1] "rad"  ADS,APA
 SG_ FC_Obj19_PhiMid : 279|13@0+ (0.00025,-1) [-1|1] "rad"  ADS,APA
 SG_ FC_Obj19_PhiLeftVel : 263|13@0+ (0.001,-4) [-4|4] "rad/s"  ADS,APA
 SG_ FC_Obj19_PhiLeft : 247|13@0+ (0.00025,-1) [-1|1] "rad"  ADS,APA
 SG_ FC_Obj19_PhiBottom : 227|12@0+ (0.00025,-0.4) [-0.4|0.4] "rad"  ADS,APA
 SG_ FC_Obj19_Width : 210|11@0+ (0.01,0) [0|12] "m"  ADS,APA
 SG_ FC_Obj19_Length : 204|9@0+ (0.05,0) [0|25.5] "m"  ADS,APA
 SG_ FC_Obj19_Height : 199|9@0+ (0.01,0) [0|5.11] "m"  ADS,APA
 SG_ FC_Obj19_HeadOrientation : 188|4@0+ (1,0) [0|15] ""  ADS,APA
 SG_ FC_Obj19_HeadingAngle : 183|9@0+ (0.01,-1.57) [-1.57|1.57] "rad"  ADS,APA
 SG_ FC_Obj19_ExistProb : 175|6@0+ (2,0) [0|100] "%"  ADS,APA
 SG_ FC_Obj19_Dy_Vnce : 151|10@0+ (0.02,0) [0|20] "m2"  ADS,APA
 SG_ FC_Obj19_Dy : 135|14@0+ (0.01,-80) [-80|80] "m"  ADS,APA
 SG_ FC_Obj19_Dx_Vnce : 103|14@0+ (0.05,0) [0|50] "m2"  ADS,APA
 SG_ FC_Obj19_Dx : 87|12@0+ (0.05,0) [0|204.7] "m"  ADS,APA
 SG_ FC_Obj19_ClassifiedView : 76|3@0+ (1,0) [0|7] ""  ADS,APA
 SG_ FC_Obj19_Vy : 71|10@0+ (0.1,-50) [-50|50] "m/s"  ADS,APA
 SG_ FC_Obj19_Vx : 51|12@0+ (0.1,-154) [-154|50] "m/s"  ADS,APA
 SG_ FC_Obj19_Ay : 47|8@0+ (0.1,-12) [-12|12] "m/s2"  ADS,APA
 SG_ FC_Obj19_Ax : 24|9@0+ (0.1,-16) [-16|16] "m/s2"  ADS,APA
 SG_ FC_Obj19_TypeProb : 31|6@0+ (2,0) [0|100] "%"  ADS,APA
 SG_ FC_Obj19_Type : 13|3@0+ (1,0) [0|7] ""  ADS,APA
 SG_ FC_Obj19_Track_Age : 23|8@0+ (1,0) [0|254] ""  ADS,APA
 SG_ FC_Obj19_Track_ID : 7|8@0+ (1,0) [0|254] ""  ADS,APA
 SG_ FC_Obj19_BlockCtr : 91|4@0+ (1,0) [0|15] "-"  ADS,APA

BO_ 422 FC_1A6: 64 FC
 SG_ FC_RollingCounter_1A6 : 491|4@0+ (1,0) [0|15] ""  ADS,APA
 SG_ FC_CRCCheck_1A6 : 503|16@0+ (1,0) [0|65535] ""  ADS,APA
 SG_ FC_obj20_Brakelight_Info : 338|1@0+ (1,0) [0|1] ""  ADS,APA
 SG_ FC_obj20_Taillight_Info : 341|3@0+ (1,0) [0|7] ""  ADS,APA
 SG_ FC_Obj20_PhiTop : 327|12@0+ (0.00025,-0.4) [-0.4|0.4] "rad"  ADS,APA
 SG_ FC_Obj20_PhiRightVel : 311|13@0+ (0.001,-4) [-4|4] "rad/s"  ADS,APA
 SG_ FC_Obj20_PhiRight : 295|13@0+ (0.00025,-1) [-1|1] "rad"  ADS,APA
 SG_ FC_Obj20_PhiMid : 279|13@0+ (0.00025,-1) [-1|1] "rad"  ADS,APA
 SG_ FC_Obj20_PhiLeftVel : 263|13@0+ (0.001,-4) [-4|4] "rad/s"  ADS,APA
 SG_ FC_Obj20_PhiLeft : 247|13@0+ (0.00025,-1) [-1|1] "rad"  ADS,APA
 SG_ FC_Obj20_PhiBottom : 227|12@0+ (0.00025,-0.4) [-0.4|0.4] "rad"  ADS,APA
 SG_ FC_Obj20_Width : 210|11@0+ (0.01,0) [0|12] "m"  ADS,APA
 SG_ FC_Obj20_Length : 204|9@0+ (0.05,0) [0|25.5] "m"  ADS,APA
 SG_ FC_Obj20_Height : 199|9@0+ (0.01,0) [0|5.11] "m"  ADS,APA
 SG_ FC_Obj20_HeadOrientation : 188|4@0+ (1,0) [0|15] ""  ADS,APA
 SG_ FC_Obj20_HeadingAngle : 183|9@0+ (0.01,-1.57) [-1.57|1.57] "rad"  ADS,APA
 SG_ FC_Obj20_ExistProb : 175|6@0+ (2,0) [0|100] "%"  ADS,APA
 SG_ FC_Obj20_Dy_Vnce : 151|10@0+ (0.02,0) [0|20] "m2"  ADS,APA
 SG_ FC_Obj20_Dy : 135|14@0+ (0.01,-80) [-80|80] "m"  ADS,APA
 SG_ FC_Obj20_Dx_Vnce : 103|14@0+ (0.05,0) [0|50] "m2"  ADS,APA
 SG_ FC_Obj20_Dx : 87|12@0+ (0.05,0) [0|204.7] "m"  ADS,APA
 SG_ FC_Obj20_ClassifiedView : 76|3@0+ (1,0) [0|7] ""  ADS,APA
 SG_ FC_Obj20_Vy : 71|10@0+ (0.1,-50) [-50|50] "m/s"  ADS,APA
 SG_ FC_Obj20_Vx : 51|12@0+ (0.1,-154) [-154|50] "m/s"  ADS,APA
 SG_ FC_Obj20_Ay : 47|8@0+ (0.1,-12) [-12|12] "m/s2"  ADS,APA
 SG_ FC_Obj20_Ax : 24|9@0+ (0.1,-16) [-16|16] "m/s2"  ADS,APA
 SG_ FC_Obj20_TypeProb : 31|6@0+ (2,0) [0|100] "%"  ADS,APA
 SG_ FC_Obj20_Type : 13|3@0+ (1,0) [0|7] ""  ADS,APA
 SG_ FC_Obj20_Track_Age : 23|8@0+ (1,0) [0|254] ""  ADS,APA
 SG_ FC_Obj20_Track_ID : 7|8@0+ (1,0) [0|254] ""  ADS,APA
 SG_ FC_Obj20_BlockCtr : 91|4@0+ (1,0) [0|15] "-"  ADS,APA

BO_ 424 FC_1A8: 64 FC
 SG_ FC_TSRRightLaneStatus : 439|3@0+ (1,0) [0|7] ""  ADS
 SG_ FC_TSRLeftLaneStatus : 431|3@0+ (1,0) [0|7] ""  ADS
 SG_ FC_TSRRightLaneSpdLimit : 319|8@0+ (1,0) [0|255] ""  ADS
 SG_ FC_TSRLeftLaneSpdLimit : 311|8@0+ (1,0) [0|255] ""  ADS
 SG_ FC_TLAStopLine_HostLane : 460|8@0+ (1,0) [0|255] ""  ADS
 SG_ FC_TLADistance_HostLane : 487|8@0+ (1,0) [0|255] ""  ADS
 SG_ FC_TLACountDownTime_HostLane : 478|7@0+ (1,0) [0|127] ""  ADS
 SG_ FC_TSRMandatorySign : 454|4@0+ (1,0) [0|15] ""  ADS
 SG_ FC_TSRWarningSign : 467|4@0+ (1,0) [0|15] ""  ADS
 SG_ FC_TSRProhibitionSign : 450|5@0+ (1,0) [0|31] ""  ADS
 SG_ FC_OverspeedSoundWarningEnSt : 411|1@0+ (1,0) [0|1] ""  ADS
 SG_ FC_TSREnable : 414|1@0+ (1,0) [0|1] ""  ADS
 SG_ FC_HMAEnableStatus : 406|1@0+ (1,0) [0|1] ""  ADS
 SG_ FC_HMALightDistribution : 392|1@0+ (1,0) [0|1] ""  ADS
 SG_ FC_HMAStatus : 428|2@0+ (1,0) [0|3] ""  ADS
 SG_ FC_TSRHostSpdLimitUnits : 425|2@0+ (1,0) [0|3] ""  ADS
 SG_ FC_TSRHostSpdLimit : 423|8@0+ (1,0) [0|255] ""  ADS
 SG_ FC_TSRStatus : 410|3@0+ (1,0) [0|7] ""  ADS
 SG_ FC_FrontCameraFailureStatus : 401|2@0+ (1,0) [0|3] ""  ADS
 SG_ FC_OverspeedWarningOffset : 398|5@0+ (1,-10) [-10|10] "km/h"  ADS
 SG_ FC_OverspeedWarningEnableStatus : 399|1@0+ (1,0) [0|1] ""  ADS
 SG_ FC_OverspeedSoundWarning : 386|1@0+ (1,0) [0|1] ""  ADS
 SG_ FC_OverspeedVisualWarning : 389|1@0+ (1,0) [0|1] ""  ADS
 SG_ FC_TLAArrowDirection_RightLane : 364|3@0+ (1,0) [0|7] ""  ADS
 SG_ FC_TLAObjectType_RightLane : 367|3@0+ (1,0) [0|7] ""  ADS
 SG_ FC_TLAObjectStatus_RightLane : 375|2@0+ (1,0) [0|3] ""  ADS
 SG_ FC_TLAObjectColour_RightLane : 353|2@0+ (1,0) [0|3] ""  ADS
 SG_ FC_TLAObjectDetection_RightLane : 355|1@0+ (1,0) [0|1] ""  ADS
 SG_ FC_TLAArrowDirection_LeftLane : 344|3@0+ (1,0) [0|7] ""  ADS
 SG_ FC_TLAObjectType_LeftLane : 347|3@0+ (1,0) [0|7] ""  ADS
 SG_ FC_TLAObjectStatus_LeftLane : 373|2@0+ (1,0) [0|3] ""  ADS
 SG_ FC_TLAObjectColour_LeftLane : 349|2@0+ (1,0) [0|3] ""  ADS
 SG_ FC_TLAObjectDetection_LeftLane : 351|1@0+ (1,0) [0|1] ""  ADS
 SG_ FC_TLAArrowDirection_HostLane : 343|3@0+ (1,0) [0|7] ""  ADS
 SG_ FC_TLAObjectStatus_HostLane : 327|2@0+ (1,0) [0|3] ""  ADS
 SG_ FC_TLAObjectType_HostLane : 340|3@0+ (1,0) [0|7] ""  ADS
 SG_ FC_TLAObjectColour_HostLane : 332|2@0+ (1,0) [0|3] ""  ADS
 SG_ FC_TLAObjectDetection_HostLane : 328|1@0+ (1,0) [0|1] ""  ADS
 SG_ FC_TLAWarninglevel : 325|2@0+ (1,0) [0|3] ""  ADS
 SG_ FC_TLAStatus : 321|2@0+ (1,0) [0|3] ""  ADS
 SG_ FC_TLAEnable : 322|1@0+ (1,0) [0|1] ""  ADS
 SG_ FC_RollingCounter_1A8 : 491|4@0+ (1,0) [0|15] ""  ADS
 SG_ FC_CRCCheck_1A8 : 503|16@0+ (1,0) [0|65535] ""  ADS
 SG_ FC_FrontCameraCalibrationStatus : 261|2@0+ (1,0) [0|3] ""  ADS
 SG_ FC_SLASpdLimit : 303|8@0+ (1,0) [0|255] ""  ADS
 SG_ FC_LaneCurvature_80m : 294|7@0+ (0.0005,-0.03) [-0.03|0.03] "1/m"  ADS
 SG_ FC_LaneCurvature_50m : 286|7@0+ (0.0005,-0.03) [-0.03|0.03] "1/m"  ADS
 SG_ FC_LaneCurvature_10m : 278|7@0+ (0.0005,-0.03) [-0.03|0.03] "1/m"  ADS
 SG_ FC_LaneCurvature_0m : 270|7@0+ (0.0005,-0.03) [-0.03|0.03] "1/m"  ADS
 SG_ FC_LaneChangeStatus : 258|3@0+ (1,0) [0|4] ""  ADS

BO_ 444 FC_1BC: 64 FC
 SG_ FC_ELKEnableStatus : 52|1@0+ (1,0) [0|1] ""  ADS
 SG_ FC_HostLaneLeftStatus : 27|4@0+ (1,0) [15|15] ""  ADS
 SG_ FC_HostLaneRightStatus : 31|4@0+ (1,0) [0|15] ""  ADS
 SG_ FC_Voiceinfo : 23|5@0+ (1,0) [0|31] ""  ADS
 SG_ FC_ELKInterventionMode : 50|2@0+ (1,0) [0|3] ""  ADS
 SG_ FC_ELKMode : 55|3@0+ (1,0) [0|7] ""  ADS
 SG_ FC_LDWShakeLevStatus : 47|2@0+ (1,0) [0|3] ""  ADS
 SG_ FC_LASWarningModeSelectionSts : 34|3@0+ (1,0) [0|7] ""  ADS
 SG_ FC_LASModeSelectionStatus : 38|3@0+ (1,0) [0|7] ""  ADS
 SG_ FC_RollingCounter_1BC : 491|4@0+ (1,0) [0|15] ""  ADS
 SG_ FC_CRCCheck_1BC : 503|16@0+ (1,0) [0|65535] ""  ADS
 SG_ FC_LKATakeoverReq : 0|1@0+ (1,0) [0|1] ""  ADS
 SG_ FC_LKAStatus : 7|2@0+ (1,0) [0|3] ""  ADS
 SG_ FC_LDWVibrationWarningReq : 11|2@0+ (1,0) [0|3] ""  ADS
 SG_ FC_LDWStatus : 13|2@0+ (1,0) [0|3] ""  ADS

BO_ 445 FC_1BD: 64 FC
 SG_ FC_RollingCounter_1BD : 491|4@0+ (1,0) [0|15] ""  ADS
 SG_ FC_CRCCheck_1BD : 503|16@0+ (1,0) [0|65535] ""  ADS
 SG_ FC_LatAngReqActive : 31|1@0+ (1,0) [0|1] ""  ADS
 SG_ FC_LatAngReq : 29|14@0+ (0.1,-720) [-720|720] "degree"  ADS
 SG_ FC_MotorTorqueMinLimitRequest : 10|11@0+ (0.02,-20.48) [-20.48|20.46] "Nm"  ADS
 SG_ FC_MotorTorqueMaxLimitRequest : 7|11@0+ (0.02,-20.48) [-20.48|20.46] "Nm"  ADS

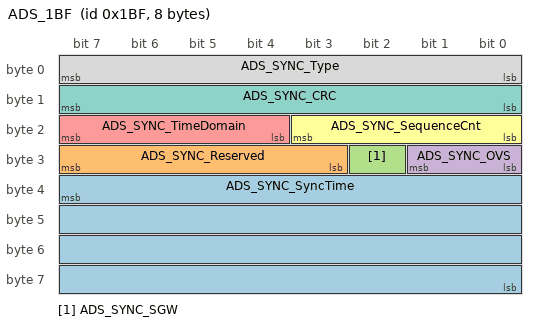
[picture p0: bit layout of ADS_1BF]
BO_ 447 ADS_1BF: 8 ADS
 SG_ ADS_SYNC_SyncTime : 39|32@0+ (1,0) [0|4294967295] "-"  FC,FR,ADS,HPP
 SG_ ADS_SYNC_Reserved : 31|5@0+ (1,0) [0|31] "-"  FC,FR,ADS,HPP
 SG_ ADS_SYNC_SGW : 26|1@0+ (1,0) [0|1] "-"  FC,FR,ADS,HPP
 SG_ ADS_SYNC_OVS : 25|2@0+ (1,0) [0|3] "-"  FC,FR,ADS,HPP
 SG_ ADS_SYNC_TimeDomain : 23|4@0+ (1,0) [0|15] "-"  FC,FR,ADS,HPP
 SG_ ADS_SYNC_SequenceCnt : 19|4@0+ (1,0) [0|15] "-"  FC,FR,ADS,HPP
 SG_ ADS_SYNC_CRC : 15|8@0+ (1,0) [0|0] "-"  FC,FR,ADS,HPP
 SG_ ADS_SYNC_Type : 7|8@0+ (1,0) [0|255] "-"  FC,FR,ADS,HPP

BO_ 448 ADS_1C0: 64 ADS
 SG_ ADS_UDLCStatus : 15|4@0+ (1,0) [0|15] ""  FC,FR,ADS
 SG_ ADS_IACCHWAMode : 6|3@0+ (1,0) [0|7] ""  FC,FR,ADS

BO_ 423 FC_1A7: 64 FC
 SG_ FC_RollingCounter_1A7 : 491|4@0+ (1,0) [0|15] ""  ADS,APA
 SG_ FC_CRCCheck_1A7 : 503|16@0+ (1,0) [0|65535] ""  ADS,APA
 SG_ FC_PostLine_BlockCtr : 495|4@0+ (1,0) [0|15] "-"  ADS,APA
 SG_ FC_PostLineTiOut : 450|1@0+ (1,0) [0|1] "-"  ADS,APA
 SG_ FC_PostLineTiLeap : 449|1@0+ (1,0) [0|1] "-"  ADS,APA
 SG_ FC_PostLineTiBas : 448|1@0+ (1,0) [0|1] "-"  ADS,APA
 SG_ FC_PostLineTiStamp : 463|32@0+ (0.0001,0) [0|429496.7295] "s"  ADS,APA
 SG_ FC_Line_Trajectory__dx_Range : 183|10@0+ (0.25,0) [0|255.75] "m"  ADS,APA
 SG_ FC_Line_Trajectory_Reliability : 174|7@0+ (1,0) [0|100] "%"  ADS,APA
 SG_ FC_Line_Trajectory_Valid : 161|2@0+ (1,0) [0|3] "-"  ADS,APA
 SG_ FC_Line_Trajectory_curvature_alt : 123|12@0+ (3.8147E-006,-0.0078125) [-0.0078125|0.0078086965] "1/m2"  ADS,APA
 SG_ FC_Line_Trajectory__curve : 159|13@0+ (3.8147E-006,-0.015625) [-0.015625|0.0156212077] "1/m"  ADS,APA
 SG_ FC_Line_Trajectory_HeadingAngle : 140|13@0+ (0.000488281,-1.6) [-1.6|1.6] "rad"  ADS,APA
 SG_ FC_Line_Trajectory_dy : 119|12@0+ (0.015625,-32) [-32|31.984375] "m"  ADS,APA
 SG_ FC_Line_Right_curvature_alt : 67|12@0+ (3.8147E-006,-0.0078125) [-0.0078125|0.0078086965] "1/m2"  ADS,APA
 SG_ FC_Line_Right__curve : 103|13@0+ (3.8147E-006,-0.015625) [-0.015625|0.0156212077] "1/m"  ADS,APA
 SG_ FC_Line_Right_HeadingAngle : 84|13@0+ (0.000488281,-1.6) [-1.6|1.6] "rad"  ADS,APA
 SG_ FC_Line_Right_dy : 63|12@0+ (0.015625,-32) [-32|31.984375] "m"  ADS,APA
 SG_ FC_Line_Left_curvature_alt : 11|12@0+ (3.8147E-006,-0.0078125) [-0.0078125|0.0078086965] "1/m2"  ADS,APA
 SG_ FC_Line_Left__curve : 47|13@0+ (3.8147E-006,-0.015625) [-0.015625|0.0156212077] "1/m"  ADS,APA
 SG_ FC_Line_Left_HeadingAngle : 28|13@0+ (0.000488281,-1.6) [-1.6|1.6] "rad"  ADS,APA
 SG_ FC_Line_Left_dy : 7|12@0+ (0.015625,-32) [-32|31.984375] "m"  ADS,APA

CM_ BO_ 400 " ";
CM_ SG_ 400 FC_Line03_BlockCtr " ";
CM_ SG_ 400 FC_Line_03_MeasureType " ";
CM_ SG_ 400 FC_Line_03_curvature_alteration " ";
CM_ SG_ 400 FC_Line_03__curve " ";
CM_ SG_ 400 FC_Line_03_HeadingAngle " ";
CM_ SG_ 400 FC_Line_03_dy " ";
CM_ SG_ 400 FC_Line_03_dx_End_std " ";
CM_ SG_ 400 FC_Line_03__dx_End " ";
CM_ SG_ 400 FC_Line_03_dx_Start_std " ";
CM_ SG_ 400 FC_Line_03_dx_Start " ";
CM_ SG_ 400 FC_Line_03_Width " ";
CM_ SG_ 400 FC_Line_03_color " ";
CM_ SG_ 400 FC_Line_03_Id " ";
CM_ SG_ 400 FC_Line_03_TypeConfidence " ";
CM_ SG_ 400 FC_Line_03_Type " ";
CM_ SG_ 400 FC_Line_02__exist_prob " ";
CM_ SG_ 400 FC_Line_02_MeasureType " ";
CM_ SG_ 400 FC_Line_02_curvature_alteration " ";
CM_ SG_ 400 FC_Line_02__curve " ";
CM_ SG_ 400 FC_Line_02_HeadingAngle " ";
CM_ SG_ 400 FC_Line_02_dy " ";
CM_ SG_ 400 FC_Line_02_dx_End_std " ";
CM_ SG_ 400 FC_Line_02__dx_End " ";
CM_ SG_ 400 FC_Line_02_dx_Start_std " ";
CM_ SG_ 400 FC_Line_02_dx_Start " ";
CM_ SG_ 400 FC_Line_02_Width " ";
CM_ SG_ 400 FC_Line_02_color " ";
CM_ SG_ 400 FC_Line_02_Id " ";
CM_ SG_ 400 FC_Line_02_TypeConfidence " ";
CM_ SG_ 400 FC_Line_02_Type " ";
CM_ SG_ 400 FC_Line02_BlockCtr " ";
CM_ SG_ 400 FC_Line01_BlockCtr " ";
CM_ SG_ 400 FC_LineTiOut " ";
CM_ SG_ 400 FC_LineTiLeap " ";
CM_ SG_ 400 FC_LineTiBas " ";
CM_ SG_ 400 FC_LineTiStamp " ";
CM_ SG_ 400 FC_Line_01__exist_prob " ";
CM_ SG_ 400 FC_Line_01_MeasureType " ";
CM_ SG_ 400 FC_Line_01_curvature_alteration " ";
CM_ SG_ 400 FC_Line_01__curve " ";
CM_ SG_ 400 FC_Line_01_HeadingAngle " ";
CM_ SG_ 400 FC_Line_01_dy " ";
CM_ SG_ 400 FC_Line_01_dx_End_std " ";
CM_ SG_ 400 FC_Line_01__dx_End " ";
CM_ SG_ 400 FC_Line_01_dx_Start_std " ";
CM_ SG_ 400 FC_Line_01_dx_Start " ";
CM_ SG_ 400 FC_Line_01_Width " ";
CM_ SG_ 400 FC_Line_01_color " ";
CM_ SG_ 400 FC_Line_01_Id " ";
CM_ SG_ 400 FC_Line_01_TypeConfidence " ";
CM_ SG_ 400 FC_Line_01_Type " ";
CM_ BO_ 401 " ";
CM_ SG_ 401 FC_Line_06__exist_prob " ";
CM_ SG_ 401 FC_Line_06_MeasureType " ";
CM_ SG_ 401 FC_Line_06_curvature_alteration " ";
CM_ SG_ 401 FC_Line_06__curve " ";
CM_ SG_ 401 FC_Line_06_HeadingAngle " ";
CM_ SG_ 401 FC_Line_06_dy " ";
CM_ SG_ 401 FC_Line_06_dx_End_std " ";
CM_ SG_ 401 FC_Line_06__dx_End " ";
CM_ SG_ 401 FC_Line_06_dx_Start_std " ";
CM_ SG_ 401 FC_Line_06_dx_Start " ";
CM_ SG_ 401 FC_Line_06_Width " ";
CM_ SG_ 401 FC_Line_06_color " ";
CM_ SG_ 401 FC_Line_06_Id " ";
CM_ SG_ 401 FC_Line_06_TypeConfidence " ";
CM_ SG_ 401 FC_Line_06_Type " ";
CM_ SG_ 401 FC_Line_05__exist_prob " ";
CM_ SG_ 401 FC_Line_05_MeasureType " ";
CM_ SG_ 401 FC_Line_05_curvature_alteration " ";
CM_ SG_ 401 FC_Line_05__curve " ";
CM_ SG_ 401 FC_Line_05_HeadingAngle " ";
CM_ SG_ 401 FC_Line_05_dy " ";
CM_ SG_ 401 FC_Line_05_dx_End_std " ";
CM_ SG_ 401 FC_Line_05__dx_End " ";
CM_ SG_ 401 FC_Line_05_dx_Start_std " ";
CM_ SG_ 401 FC_Line_05_dx_Start " ";
CM_ SG_ 401 FC_Line_05_Width " ";
CM_ SG_ 401 FC_Line_05_color " ";
CM_ SG_ 401 FC_Line_05_Id " ";
CM_ SG_ 401 FC_Line_05_TypeConfidence " ";
CM_ SG_ 401 FC_Line_05_Type " ";
CM_ SG_ 401 FC_Line_04__exist_prob " ";
CM_ SG_ 401 FC_Line_04_MeasureType " ";
CM_ SG_ 401 FC_Line_04_curvature_alteration " ";
CM_ SG_ 401 FC_Line_04__curve " ";
CM_ SG_ 401 FC_Line_04_HeadingAngle " ";
CM_ SG_ 401 FC_Line_04_dy " ";
CM_ SG_ 401 FC_Line_04_dx_End_std " ";
CM_ SG_ 401 FC_Line_04__dx_End " ";
CM_ SG_ 401 FC_Line_04_dx_Start_std " ";
CM_ SG_ 401 FC_Line_04_dx_Start " ";
CM_ SG_ 401 FC_Line_04_Width " ";
CM_ SG_ 401 FC_Line_04_color " ";
CM_ SG_ 401 FC_Line_04_Id " ";
CM_ SG_ 401 FC_Line_04_TypeConfidence " ";
CM_ SG_ 401 FC_Line_04_Type " ";
CM_ SG_ 401 FC_Line_03__exist_prob " ";
CM_ SG_ 401 FC_Line06_BlockCtr " ";
CM_ SG_ 401 FC_Line05_BlockCtr " ";
CM_ SG_ 401 FC_Line04_BlockCtr " ";
CM_ BO_ 402 " ";
CM_ SG_ 402 FC_RoadSignTiOut " ";
CM_ SG_ 402 FC_RoadSignTiLeap " ";
CM_ SG_ 402 FC_RoadSignTiBas " ";
CM_ SG_ 402 FC_RoadSignTiStamp " ";
CM_ SG_ 402 FC_Line_08__exist_prob " ";
CM_ SG_ 402 FC_Line_08_MeasureType " ";
CM_ SG_ 402 FC_Line_08_curvature_alteration " ";
CM_ SG_ 402 FC_Line_08__curve " ";
CM_ SG_ 402 FC_Line_08_HeadingAngle " ";
CM_ SG_ 402 FC_Line_08_dy " ";
CM_ SG_ 402 FC_Line_08_dx_End_std " ";
CM_ SG_ 402 FC_Line_08__dx_End " ";
CM_ SG_ 402 FC_Line_08_dx_Start_std " ";
CM_ SG_ 402 FC_Line_08_dx_Start " ";
CM_ SG_ 402 FC_Line_08_Width " ";
CM_ SG_ 402 FC_Line_08_color " ";
CM_ SG_ 402 FC_Line_08_Id " ";
CM_ SG_ 402 FC_Line_08_TypeConfidence " ";
CM_ SG_ 402 FC_Line_08_Type " ";
CM_ SG_ 402 FC_Line_07__exist_prob " ";
CM_ SG_ 402 FC_Line_07_MeasureType " ";
CM_ SG_ 402 FC_Line_07_curvature_alteration " ";
CM_ SG_ 402 FC_Line_07__curve " ";
CM_ SG_ 402 FC_Line_07_HeadingAngle " ";
CM_ SG_ 402 FC_Line_07_dy " ";
CM_ SG_ 402 FC_Line_07_dx_End_std " ";
CM_ SG_ 402 FC_Line_07__dx_End " ";
CM_ SG_ 402 FC_Line_07_dx_Start_std " ";
CM_ SG_ 402 FC_Line_07_dx_Start " ";
CM_ SG_ 402 FC_Line_07_Width " ";
CM_ SG_ 402 FC_Line_07_color " ";
CM_ SG_ 402 FC_Line_07_Id " ";
CM_ SG_ 402 FC_Line_07_TypeConfidence " ";
CM_ SG_ 402 FC_Line_07_Type " ";
CM_ SG_ 402 FC_Line08_BlockCtr " ";
CM_ SG_ 402 FC_Line07_BlockCtr " ";
CM_ BO_ 403 " ";
CM_ SG_ 403 FC_SignBoardTiOut " ";
CM_ SG_ 403 FC_SignBoardTiLeap " ";
CM_ SG_ 403 FC_SignBoardTiBas " ";
CM_ SG_ 403 FC_SignBoardTiStamp " ";
CM_ SG_ 403 FC_SignBoardConfidence_3 " ";
CM_ SG_ 403 FC_SignBoardLength_3 " ";
CM_ SG_ 403 FC_SignBoardWidth_3 " ";
CM_ SG_ 403 FC_SignBoardHeight_3 " ";
CM_ SG_ 403 FC_SignBoardCenterLatRange_3 " ";
CM_ SG_ 403 FC_SignBoardCenterLngRange_3 " ";
CM_ SG_ 403 FC_SpeedLimit_3 " ";
CM_ SG_ 403 FC_SignBoardType_3 " ";
CM_ SG_ 403 FC_SignBoardConfidence_2 " ";
CM_ SG_ 403 FC_SignBoardLength_2 " ";
CM_ SG_ 403 FC_SignBoardWidth_2 " ";
CM_ SG_ 403 FC_SignBoardHeight_2 " ";
CM_ SG_ 403 FC_SignBoardCenterLatRange_2 " ";
CM_ SG_ 403 FC_SignBoardCenterLngRange_2 " ";
CM_ SG_ 403 FC_SpeedLimit_2 " ";
CM_ SG_ 403 FC_SignBoardType_2 " ";
CM_ SG_ 403 FC_SignBoardConfidence_1 " ";
CM_ SG_ 403 FC_SignBoardLength_1 " ";
CM_ SG_ 403 FC_SignBoardWidth_1 " ";
CM_ SG_ 403 FC_SignBoardHeight_1 " ";
CM_ SG_ 403 FC_SignBoardCenterLatRange_1 " ";
CM_ SG_ 403 FC_SignBoardCenterLngRange_1 " ";
CM_ SG_ 403 FC_SpeedLimit_1 " ";
CM_ SG_ 403 FC_SignBoardType_1 " ";
CM_ SG_ 403 FC_RoadSignConfidence_4 " ";
CM_ SG_ 403 FC_RoadSignLength_4 " ";
CM_ SG_ 403 FC_RoadSignWidth_4 " ";
CM_ SG_ 403 FC_RoadSignCenterLatRange_4 " ";
CM_ SG_ 403 FC_RoadSignCenterLngRange_4 " ";
CM_ SG_ 403 FC_RoadSignType_4 " ";
CM_ SG_ 403 FC_RoadSignConfidence_3 " ";
CM_ SG_ 403 FC_RoadSignLength_3 " ";
CM_ SG_ 403 FC_RoadSignWidth_3 " ";
CM_ SG_ 403 FC_RoadSignCenterLatRange_3 " ";
CM_ SG_ 403 FC_RoadSignCenterLngRange_3 " ";
CM_ SG_ 403 FC_RoadSignType_3 " ";
CM_ SG_ 403 FC_RoadSignConfidence_2 " ";
CM_ SG_ 403 FC_RoadSignLength_2 " ";
CM_ SG_ 403 FC_RoadSignWidth_2 " ";
CM_ SG_ 403 FC_RoadSignCenterLatRange_2 " ";
CM_ SG_ 403 FC_RoadSignCenterLngRange_2 " ";
CM_ SG_ 403 FC_RoadSignType_2 " ";
CM_ SG_ 403 FC_RoadSignConfidence_1 " ";
CM_ SG_ 403 FC_RoadSignLength_1 " ";
CM_ SG_ 403 FC_RoadSignWidth_1 " ";
CM_ SG_ 403 FC_RoadSignCenterLatRange_1 " ";
CM_ SG_ 403 FC_RoadSignCenterLngRange_1 " ";
CM_ SG_ 403 FC_RoadSignType_1 " ";
CM_ SG_ 403 FC_SignBoard03_BlockCtr " ";
CM_ SG_ 403 FC_SignBoardn02_BlockCtr " ";
CM_ SG_ 403 FC_SignBoard01_BlockCtr " ";
CM_ SG_ 403 FC_RoadSign04_BlockCtr " ";
CM_ SG_ 403 FC_RoadSign03_BlockCtr " ";
CM_ SG_ 403 FC_RoadSign02_BlockCtr " ";
CM_ SG_ 403 FC_RoadSign01_BlockCtr " ";
CM_ BO_ 404 " ";
CM_ SG_ 404 FC_TFLTiOut " ";
CM_ SG_ 404 FC_TFLTiLeap " ";
CM_ SG_ 404 FC_TFLTiBas " ";
CM_ SG_ 404 FC_TFLTiStamp " ";
CM_ SG_ 404 FC_Num_Of_TFL_Objects " ";
CM_ SG_ 404 FC_TFL6_Confidence " ";
CM_ SG_ 404 FC_TFL6_Direction " ";
CM_ SG_ 404 FC_TFL6_Type " ";
CM_ SG_ 404 FC_TFL6_PosZ " ";
CM_ SG_ 404 FC_TFL6_PosY " ";
CM_ SG_ 404 FC_TFL6_PosX " ";
CM_ SG_ 404 FC_TFL5_Confidence " ";
CM_ SG_ 404 FC_TFL5_Direction " ";
CM_ SG_ 404 FC_TFL5_Type " ";
CM_ SG_ 404 FC_TFL5_PosZ " ";
CM_ SG_ 404 FC_TFL5_PosY " ";
CM_ SG_ 404 FC_TFL5_PosX " ";
CM_ SG_ 404 FC_TFL4_Confidence " ";
CM_ SG_ 404 FC_TFL4_Direction " ";
CM_ SG_ 404 FC_TFL4_Type " ";
CM_ SG_ 404 FC_TFL4_PosZ " ";
CM_ SG_ 404 FC_TFL4_PosY " ";
CM_ SG_ 404 FC_TFL4_PosX " ";
CM_ SG_ 404 FC_TFL3_Confidence " ";
CM_ SG_ 404 FC_TFL3_Direction " ";
CM_ SG_ 404 FC_TFL3_Type " ";
CM_ SG_ 404 FC_TFL3_PosZ " ";
CM_ SG_ 404 FC_TFL3_PosY " ";
CM_ SG_ 404 FC_TFL3_PosX " ";
CM_ SG_ 404 FC_TFL2_Confidence " ";
CM_ SG_ 404 FC_TFL2_Direction " ";
CM_ SG_ 404 FC_TFL2_Type " ";
CM_ SG_ 404 FC_TFL2_PosZ " ";
CM_ SG_ 404 FC_TFL2_PosY " ";
CM_ SG_ 404 FC_TFL2_PosX " ";
CM_ SG_ 404 FC_TFL1_Confidence " ";
CM_ SG_ 404 FC_TFL1_Direction " ";
CM_ SG_ 404 FC_TFL1_Type " ";
CM_ SG_ 404 FC_TFL1_PosZ " ";
CM_ SG_ 404 FC_TFL1_PosY " ";
CM_ SG_ 404 FC_TFL1_PosX " ";
CM_ SG_ 404 FC_SignBoardConfidence_4 " ";
CM_ SG_ 404 FC_SignBoardLength_4 " ";
CM_ SG_ 404 FC_SignBoardWidth_4 " ";
CM_ SG_ 404 FC_SignBoardHeight_4 " ";
CM_ SG_ 404 FC_SignBoardCenterLatRange_4 " ";
CM_ SG_ 404 FC_SignBoardCenterLngRange_4 " ";
CM_ SG_ 404 FC_SpeedLimit_4 " ";
CM_ SG_ 404 FC_SignBoardType_4 " ";
CM_ SG_ 404 FC_SignBoard04_BlockCtr " ";
CM_ SG_ 404 FC_TFL06_BlockCtr " ";
CM_ SG_ 404 FC_TFL05_BlockCtr " ";
CM_ SG_ 404 FC_TFL04_BlockCtr " ";
CM_ SG_ 404 FC_TFL03_BlockCtr " ";
CM_ SG_ 404 FC_TFL02_BlockCtr " ";
CM_ SG_ 404 FC_TFL01_BlockCtr " ";
CM_ BO_ 405 " ";
CM_ SG_ 405 FC_Obj9_Dx_Vnce " ";
CM_ SG_ 405 FC_Obj9_Dx " ";
CM_ SG_ 405 FC_Obj9_ClassifiedView " ";
CM_ SG_ 405 FC_Obj9_Vy " ";
CM_ SG_ 405 FC_Obj9_Vx " ";
CM_ SG_ 405 FC_Obj9_Ay " ";
CM_ SG_ 405 FC_Obj9_Ax " ";
CM_ SG_ 405 FC_Obj9_TypeProb " ";
CM_ SG_ 405 FC_Obj9_Type " ";
CM_ SG_ 405 FC_Obj9_Track_Age " ";
CM_ SG_ 405 FC_Obj9_Track_ID " ";
CM_ SG_ 405 FC_ObjTiOut " ";
CM_ SG_ 405 FC_ObjTiLeap " ";
CM_ SG_ 405 FC_ObjTiBas " ";
CM_ SG_ 405 FC_ObjTiStamp " ";
CM_ SG_ 405 FC_obj1_Brakelight_Info " ";
CM_ SG_ 405 FC_obj1_Taillight_Info " ";
CM_ SG_ 405 FC_Obj1_PhiTop " ";
CM_ SG_ 405 FC_Obj1_PhiRightVel " ";
CM_ SG_ 405 FC_Obj1_PhiRight " ";
CM_ SG_ 405 FC_Obj1_PhiMid " ";
CM_ SG_ 405 FC_Obj1_PhiLeftVel " ";
CM_ SG_ 405 FC_Obj1_PhiLeft " ";
CM_ SG_ 405 FC_Obj1_PhiBottom " ";
CM_ SG_ 405 FC_Obj1_Width " ";
CM_ SG_ 405 FC_Obj1_Length " ";
CM_ SG_ 405 FC_Obj1_Height " ";
CM_ SG_ 405 FC_Obj1_HeadOrientation " ";
CM_ SG_ 405 FC_Obj1_HeadingAngle " ";
CM_ SG_ 405 FC_Obj1_ExistProb " ";
CM_ SG_ 405 FC_Obj1_Dy_Vnce " ";
CM_ SG_ 405 FC_Obj1_Dy " ";
CM_ SG_ 405 FC_Obj1_Dx_Vnce " ";
CM_ SG_ 405 FC_Obj1_Dx " ";
CM_ SG_ 405 FC_Obj1_ClassifiedView " ";
CM_ SG_ 405 FC_Obj1_Vy " ";
CM_ SG_ 405 FC_Obj1_Vx " ";
CM_ SG_ 405 FC_Obj1_Ay " ";
CM_ SG_ 405 FC_Obj1_Ax " ";
CM_ SG_ 405 FC_Obj1_TypeProb " ";
CM_ SG_ 405 FC_Obj1_Type " ";
CM_ SG_ 405 FC_Obj1_Track_Age " ";
CM_ SG_ 405 FC_Obj1_Track_ID " ";
CM_ SG_ 405 FC_Obj01_BlockCtr " ";
CM_ BO_ 406 " ";
CM_ SG_ 406 FC_Obj9_PhiLeft " ";
CM_ SG_ 406 FC_Obj9_PhiBottom " ";
CM_ SG_ 406 FC_Obj9_Width " ";
CM_ SG_ 406 FC_Obj9_Length " ";
CM_ SG_ 406 FC_Obj9_Height " ";
CM_ SG_ 406 FC_Obj9_HeadOrientation " ";
CM_ SG_ 406 FC_Obj9_HeadingAngle " ";
CM_ SG_ 406 FC_Obj9_ExistProb " ";
CM_ SG_ 406 FC_Obj9_Dy_Vnce " ";
CM_ SG_ 406 FC_Obj9_Dy " ";
CM_ SG_ 406 FC_obj2_Brakelight_Info " ";
CM_ SG_ 406 FC_obj2_Taillight_Info " ";
CM_ SG_ 406 FC_Obj2_PhiTop " ";
CM_ SG_ 406 FC_Obj2_PhiRightVel " ";
CM_ SG_ 406 FC_Obj2_PhiRight " ";
CM_ SG_ 406 FC_Obj2_PhiMid " ";
CM_ SG_ 406 FC_Obj2_PhiLeftVel " ";
CM_ SG_ 406 FC_Obj2_PhiLeft " ";
CM_ SG_ 406 FC_Obj2_PhiBottom " ";
CM_ SG_ 406 FC_Obj2_Width " ";
CM_ SG_ 406 FC_Obj2_Length " ";
CM_ SG_ 406 FC_Obj2_Height " ";
CM_ SG_ 406 FC_Obj2_HeadOrientation " ";
CM_ SG_ 406 FC_Obj2_HeadingAngle " ";
CM_ SG_ 406 FC_Obj2_ExistProb " ";
CM_ SG_ 406 FC_Obj2_Dy_Vnce " ";
CM_ SG_ 406 FC_Obj2_Dy " ";
CM_ SG_ 406 FC_Obj2_Dx_Vnce " ";
CM_ SG_ 406 FC_Obj2_Dx " ";
CM_ SG_ 406 FC_Obj2_ClassifiedView " ";
CM_ SG_ 406 FC_Obj2_Vy " ";
CM_ SG_ 406 FC_Obj2_Vx " ";
CM_ SG_ 406 FC_Obj2_Ay " ";
CM_ SG_ 406 FC_Obj2_Ax " ";
CM_ SG_ 406 FC_Obj2_TypeProb " ";
CM_ SG_ 406 FC_Obj2_Type " ";
CM_ SG_ 406 FC_Obj2_Track_Age " ";
CM_ SG_ 406 FC_Obj2_Track_ID " ";
CM_ SG_ 406 FC_Obj09_BlockCtr " ";
CM_ SG_ 406 FC_Obj02_BlockCtr " ";
CM_ BO_ 407 " ";
CM_ SG_ 407 FC_obj9_Brakelight_Info " ";
CM_ SG_ 407 FC_obj9_Taillight_Info " ";
CM_ SG_ 407 FC_Obj9_PhiTop " ";
CM_ SG_ 407 FC_Obj9_PhiRightVel " ";
CM_ SG_ 407 FC_Obj9_PhiRight " ";
CM_ SG_ 407 FC_Obj9_PhiMid " ";
CM_ SG_ 407 FC_Obj9_PhiLeftVel " ";
CM_ SG_ 407 FC_obj3_Brakelight_Info " ";
CM_ SG_ 407 FC_obj3_Taillight_Info " ";
CM_ SG_ 407 FC_Obj3_PhiTop " ";
CM_ SG_ 407 FC_Obj3_PhiRightVel " ";
CM_ SG_ 407 FC_Obj3_PhiRight " ";
CM_ SG_ 407 FC_Obj3_PhiMid " ";
CM_ SG_ 407 FC_Obj3_PhiLeftVel " ";
CM_ SG_ 407 FC_Obj3_PhiLeft " ";
CM_ SG_ 407 FC_Obj3_PhiBottom " ";
CM_ SG_ 407 FC_Obj3_Width " ";
CM_ SG_ 407 FC_Obj3_Length " ";
CM_ SG_ 407 FC_Obj3_Height " ";
CM_ SG_ 407 FC_Obj3_HeadOrientation " ";
CM_ SG_ 407 FC_Obj3_HeadingAngle " ";
CM_ SG_ 407 FC_Obj3_ExistProb " ";
CM_ SG_ 407 FC_Obj3_Dy_Vnce " ";
CM_ SG_ 407 FC_Obj3_Dy " ";
CM_ SG_ 407 FC_Obj3_Dx_Vnce " ";
CM_ SG_ 407 FC_Obj3_Dx " ";
CM_ SG_ 407 FC_Obj3_ClassifiedView " ";
CM_ SG_ 407 FC_Obj3_Vy " ";
CM_ SG_ 407 FC_Obj3_Vx " ";
CM_ SG_ 407 FC_Obj3_Ay " ";
CM_ SG_ 407 FC_Obj3_Ax " ";
CM_ SG_ 407 FC_Obj3_TypeProb " ";
CM_ SG_ 407 FC_Obj3_Type " ";
CM_ SG_ 407 FC_Obj3_Track_Age " ";
CM_ SG_ 407 FC_Obj3_Track_ID " ";
CM_ SG_ 407 FC_Obj03_BlockCtr " ";
CM_ BO_ 408 " ";
CM_ SG_ 408 FC_Obj11_Dx_Vnce " ";
CM_ SG_ 408 FC_Obj11_Dx " ";
CM_ SG_ 408 FC_Obj11_ClassifiedView " ";
CM_ SG_ 408 FC_Obj11_Vy " ";
CM_ SG_ 408 FC_Obj11_Vx " ";
CM_ SG_ 408 FC_Obj11_Ay " ";
CM_ SG_ 408 FC_Obj11_Ax " ";
CM_ SG_ 408 FC_Obj11_TypeProb " ";
CM_ SG_ 408 FC_Obj11_Type " ";
CM_ SG_ 408 FC_Obj11_Track_Age " ";
CM_ SG_ 408 FC_Obj11_Track_ID " ";
CM_ SG_ 408 FC_obj4_Brakelight_Info " ";
CM_ SG_ 408 FC_obj4_Taillight_Info " ";
CM_ SG_ 408 FC_Obj4_PhiTop " ";
CM_ SG_ 408 FC_Obj4_PhiRightVel " ";
CM_ SG_ 408 FC_Obj4_PhiRight " ";
CM_ SG_ 408 FC_Obj4_PhiMid " ";
CM_ SG_ 408 FC_Obj4_PhiLeftVel " ";
CM_ SG_ 408 FC_Obj4_PhiLeft " ";
CM_ SG_ 408 FC_Obj4_PhiBottom " ";
CM_ SG_ 408 FC_Obj4_Width " ";
CM_ SG_ 408 FC_Obj4_Length " ";
CM_ SG_ 408 FC_Obj4_Height " ";
CM_ SG_ 408 FC_Obj4_HeadOrientation " ";
CM_ SG_ 408 FC_Obj4_HeadingAngle " ";
CM_ SG_ 408 FC_Obj4_ExistProb " ";
CM_ SG_ 408 FC_Obj4_Dy_Vnce " ";
CM_ SG_ 408 FC_Obj4_Dy " ";
CM_ SG_ 408 FC_Obj4_Dx_Vnce " ";
CM_ SG_ 408 FC_Obj4_Dx " ";
CM_ SG_ 408 FC_Obj4_ClassifiedView " ";
CM_ SG_ 408 FC_Obj4_Vy " ";
CM_ SG_ 408 FC_Obj4_Vx " ";
CM_ SG_ 408 FC_Obj4_Ay " ";
CM_ SG_ 408 FC_Obj4_Ax " ";
CM_ SG_ 408 FC_Obj4_TypeProb " ";
CM_ SG_ 408 FC_Obj4_Type " ";
CM_ SG_ 408 FC_Obj4_Track_Age " ";
CM_ SG_ 408 FC_Obj4_Track_ID " ";
CM_ SG_ 408 FC_Obj04_BlockCtr " ";
CM_ BO_ 409 " ";
CM_ SG_ 409 FC_Obj11_PhiLeft " ";
CM_ SG_ 409 FC_Obj11_PhiBottom " ";
CM_ SG_ 409 FC_Obj11_Width " ";
CM_ SG_ 409 FC_Obj11_Length " ";
CM_ SG_ 409 FC_Obj11_Height " ";
CM_ SG_ 409 FC_Obj11_HeadOrientation " ";
CM_ SG_ 409 FC_Obj11_HeadingAngle " ";
CM_ SG_ 409 FC_Obj11_ExistProb " ";
CM_ SG_ 409 FC_Obj11_Dy_Vnce " ";
CM_ SG_ 409 FC_Obj11_Dy " ";
CM_ SG_ 409 FC_obj5_Brakelight_Info " ";
CM_ SG_ 409 FC_obj5_Taillight_Info " ";
CM_ SG_ 409 FC_Obj5_PhiTop " ";
CM_ SG_ 409 FC_Obj5_PhiRightVel " ";
CM_ SG_ 409 FC_Obj5_PhiRight " ";
CM_ SG_ 409 FC_Obj5_PhiMid " ";
CM_ SG_ 409 FC_Obj5_PhiLeftVel " ";
CM_ SG_ 409 FC_Obj5_PhiLeft " ";
CM_ SG_ 409 FC_Obj5_PhiBottom " ";
CM_ SG_ 409 FC_Obj5_Width " ";
CM_ SG_ 409 FC_Obj5_Length " ";
CM_ SG_ 409 FC_Obj5_Height " ";
CM_ SG_ 409 FC_Obj5_HeadOrientation " ";
CM_ SG_ 409 FC_Obj5_HeadingAngle " ";
CM_ SG_ 409 FC_Obj5_ExistProb " ";
CM_ SG_ 409 FC_Obj5_Dy_Vnce " ";
CM_ SG_ 409 FC_Obj5_Dy " ";
CM_ SG_ 409 FC_Obj5_Dx_Vnce " ";
CM_ SG_ 409 FC_Obj5_Dx " ";
CM_ SG_ 409 FC_Obj5_ClassifiedView " ";
CM_ SG_ 409 FC_Obj5_Vy " ";
CM_ SG_ 409 FC_Obj5_Vx " ";
CM_ SG_ 409 FC_Obj5_Ay " ";
CM_ SG_ 409 FC_Obj5_Ax " ";
CM_ SG_ 409 FC_Obj5_TypeProb " ";
CM_ SG_ 409 FC_Obj5_Type " ";
CM_ SG_ 409 FC_Obj5_Track_Age " ";
CM_ SG_ 409 FC_Obj5_Track_ID " ";
CM_ SG_ 409 FC_Obj11_BlockCtr " ";
CM_ SG_ 409 FC_Obj05_BlockCtr " ";
CM_ BO_ 410 " ";
CM_ SG_ 410 FC_obj11_Brakelight_Info " ";
CM_ SG_ 410 FC_obj11_Taillight_Info " ";
CM_ SG_ 410 FC_Obj11_PhiTop " ";
CM_ SG_ 410 FC_Obj11_PhiRightVel " ";
CM_ SG_ 410 FC_Obj11_PhiRight " ";
CM_ SG_ 410 FC_Obj11_PhiMid " ";
CM_ SG_ 410 FC_Obj11_PhiLeftVel " ";
CM_ SG_ 410 FC_obj6_Brakelight_Info " ";
CM_ SG_ 410 FC_obj6_Taillight_Info " ";
CM_ SG_ 410 FC_Obj6_PhiTop " ";
CM_ SG_ 410 FC_Obj6_PhiRightVel " ";
CM_ SG_ 410 FC_Obj6_PhiRight " ";
CM_ SG_ 410 FC_Obj6_PhiMid " ";
CM_ SG_ 410 FC_Obj6_PhiLeftVel " ";
CM_ SG_ 410 FC_Obj6_PhiLeft " ";
CM_ SG_ 410 FC_Obj6_PhiBottom " ";
CM_ SG_ 410 FC_Obj6_Width " ";
CM_ SG_ 410 FC_Obj6_Length " ";
CM_ SG_ 410 FC_Obj6_Height " ";
CM_ SG_ 410 FC_Obj6_HeadOrientation " ";
CM_ SG_ 410 FC_Obj6_HeadingAngle " ";
CM_ SG_ 410 FC_Obj6_ExistProb " ";
CM_ SG_ 410 FC_Obj6_Dy_Vnce " ";
CM_ SG_ 410 FC_Obj6_Dy " ";
CM_ SG_ 410 FC_Obj6_Dx_Vnce " ";
CM_ SG_ 410 FC_Obj6_Dx " ";
CM_ SG_ 410 FC_Obj6_ClassifiedView " ";
CM_ SG_ 410 FC_Obj6_Vy " ";
CM_ SG_ 410 FC_Obj6_Vx " ";
CM_ SG_ 410 FC_Obj6_Ay " ";
CM_ SG_ 410 FC_Obj6_Ax " ";
CM_ SG_ 410 FC_Obj6_TypeProb " ";
CM_ SG_ 410 FC_Obj6_Type " ";
CM_ SG_ 410 FC_Obj6_Track_Age " ";
CM_ SG_ 410 FC_Obj6_Track_ID " ";
CM_ SG_ 410 FC_Obj06_BlockCtr " ";
CM_ BO_ 411 " ";
CM_ SG_ 411 FC_obj7_Brakelight_Info " ";
CM_ SG_ 411 FC_obj7_Taillight_Info " ";
CM_ SG_ 411 FC_Obj7_PhiTop " ";
CM_ SG_ 411 FC_Obj7_PhiRightVel " ";
CM_ SG_ 411 FC_Obj7_PhiRight " ";
CM_ SG_ 411 FC_Obj7_PhiMid " ";
CM_ SG_ 411 FC_Obj7_PhiLeftVel " ";
CM_ SG_ 411 FC_Obj7_PhiLeft " ";
CM_ SG_ 411 FC_Obj7_PhiBottom " ";
CM_ SG_ 411 FC_Obj7_Width " ";
CM_ SG_ 411 FC_Obj7_Length " ";
CM_ SG_ 411 FC_Obj7_Height " ";
CM_ SG_ 411 FC_Obj7_HeadOrientation " ";
CM_ SG_ 411 FC_Obj7_HeadingAngle " ";
CM_ SG_ 411 FC_Obj7_ExistProb " ";
CM_ SG_ 411 FC_Obj7_Dy_Vnce " ";
CM_ SG_ 411 FC_Obj7_Dy " ";
CM_ SG_ 411 FC_Obj7_Dx_Vnce " ";
CM_ SG_ 411 FC_Obj7_Dx " ";
CM_ SG_ 411 FC_Obj7_ClassifiedView " ";
CM_ SG_ 411 FC_Obj7_Vy " ";
CM_ SG_ 411 FC_Obj7_Vx " ";
CM_ SG_ 411 FC_Obj7_Ay " ";
CM_ SG_ 411 FC_Obj7_Ax " ";
CM_ SG_ 411 FC_Obj7_TypeProb " ";
CM_ SG_ 411 FC_Obj7_Type " ";
CM_ SG_ 411 FC_Obj7_Track_Age " ";
CM_ SG_ 411 FC_Obj7_Track_ID " ";
CM_ SG_ 411 FC_Obj07_BlockCtr " ";
CM_ BO_ 412 " ";
CM_ SG_ 412 FC_obj8_Brakelight_Info " ";
CM_ SG_ 412 FC_obj8_Taillight_Info " ";
CM_ SG_ 412 FC_Obj8_PhiTop " ";
CM_ SG_ 412 FC_Obj8_PhiRightVel " ";
CM_ SG_ 412 FC_Obj8_PhiRight " ";
CM_ SG_ 412 FC_Obj8_PhiMid " ";
CM_ SG_ 412 FC_Obj8_PhiLeftVel " ";
CM_ SG_ 412 FC_Obj8_PhiLeft " ";
CM_ SG_ 412 FC_Obj8_PhiBottom " ";
CM_ SG_ 412 FC_Obj8_Width " ";
CM_ SG_ 412 FC_Obj8_Length " ";
CM_ SG_ 412 FC_Obj8_Height " ";
CM_ SG_ 412 FC_Obj8_HeadOrientation " ";
CM_ SG_ 412 FC_Obj8_HeadingAngle " ";
CM_ SG_ 412 FC_Obj8_ExistProb " ";
CM_ SG_ 412 FC_Obj8_Dy_Vnce " ";
CM_ SG_ 412 FC_Obj8_Dy " ";
CM_ SG_ 412 FC_Obj8_Dx_Vnce " ";
CM_ SG_ 412 FC_Obj8_Dx " ";
CM_ SG_ 412 FC_Obj8_ClassifiedView " ";
CM_ SG_ 412 FC_Obj8_Vy " ";
CM_ SG_ 412 FC_Obj8_Vx " ";
CM_ SG_ 412 FC_Obj8_Ay " ";
CM_ SG_ 412 FC_Obj8_Ax " ";
CM_ SG_ 412 FC_Obj8_TypeProb " ";
CM_ SG_ 412 FC_Obj8_Type " ";
CM_ SG_ 412 FC_Obj8_Track_Age " ";
CM_ SG_ 412 FC_Obj8_Track_ID " ";
CM_ SG_ 412 FC_Obj08_BlockCtr " ";
CM_ BO_ 413 " ";
CM_ SG_ 413 FC_obj10_Brakelight_Info " ";
CM_ SG_ 413 FC_obj10_Taillight_Info " ";
CM_ SG_ 413 FC_Obj10_PhiTop " ";
CM_ SG_ 413 FC_Obj10_PhiRightVel " ";
CM_ SG_ 413 FC_Obj10_PhiRight " ";
CM_ SG_ 413 FC_Obj10_PhiMid " ";
CM_ SG_ 413 FC_Obj10_PhiLeftVel " ";
CM_ SG_ 413 FC_Obj10_PhiLeft " ";
CM_ SG_ 413 FC_Obj10_PhiBottom " ";
CM_ SG_ 413 FC_Obj10_Width " ";
CM_ SG_ 413 FC_Obj10_Length " ";
CM_ SG_ 413 FC_Obj10_Height " ";
CM_ SG_ 413 FC_Obj10_HeadOrientation " ";
CM_ SG_ 413 FC_Obj10_HeadingAngle " ";
CM_ SG_ 413 FC_Obj10_ExistProb " ";
CM_ SG_ 413 FC_Obj10_Dy_Vnce " ";
CM_ SG_ 413 FC_Obj10_Dy " ";
CM_ SG_ 413 FC_Obj10_Dx_Vnce " ";
CM_ SG_ 413 FC_Obj10_Dx " ";
CM_ SG_ 413 FC_Obj10_ClassifiedView " ";
CM_ SG_ 413 FC_Obj10_Vy " ";
CM_ SG_ 413 FC_Obj10_Vx " ";
CM_ SG_ 413 FC_Obj10_Ay " ";
CM_ SG_ 413 FC_Obj10_Ax " ";
CM_ SG_ 413 FC_Obj10_TypeProb " ";
CM_ SG_ 413 FC_Obj10_Type " ";
CM_ SG_ 413 FC_Obj10_Track_Age " ";
CM_ SG_ 413 FC_Obj10_Track_ID " ";
CM_ SG_ 413 FC_Obj10_BlockCtr " ";
CM_ BO_ 414 " ";
CM_ SG_ 414 FC_obj12_Brakelight_Info " ";
CM_ SG_ 414 FC_obj12_Taillight_Info " ";
CM_ SG_ 414 FC_Obj12_PhiTop " ";
CM_ SG_ 414 FC_Obj12_PhiRightVel " ";
CM_ SG_ 414 FC_Obj12_PhiRight " ";
CM_ SG_ 414 FC_Obj12_PhiMid " ";
CM_ SG_ 414 FC_Obj12_PhiLeftVel " ";
CM_ SG_ 414 FC_Obj12_PhiLeft " ";
CM_ SG_ 414 FC_Obj12_PhiBottom " ";
CM_ SG_ 414 FC_Obj12_Width " ";
CM_ SG_ 414 FC_Obj12_Length " ";
CM_ SG_ 414 FC_Obj12_Height " ";
CM_ SG_ 414 FC_Obj12_HeadOrientation " ";
CM_ SG_ 414 FC_Obj12_HeadingAngle " ";
CM_ SG_ 414 FC_Obj12_ExistProb " ";
CM_ SG_ 414 FC_Obj12_Dy_Vnce " ";
CM_ SG_ 414 FC_Obj12_Dy " ";
CM_ SG_ 414 FC_Obj12_Dx_Vnce " ";
CM_ SG_ 414 FC_Obj12_Dx " ";
CM_ SG_ 414 FC_Obj12_ClassifiedView " ";
CM_ SG_ 414 FC_Obj12_Vy " ";
CM_ SG_ 414 FC_Obj12_Vx " ";
CM_ SG_ 414 FC_Obj12_Ay " ";
CM_ SG_ 414 FC_Obj12_Ax " ";
CM_ SG_ 414 FC_Obj12_TypeProb " ";
CM_ SG_ 414 FC_Obj12_Type " ";
CM_ SG_ 414 FC_Obj12_Track_Age " ";
CM_ SG_ 414 FC_Obj12_Track_ID " ";
CM_ SG_ 414 FC_Obj12_BlockCtr " ";
CM_ BO_ 415 " ";
CM_ SG_ 415 FC_obj13_Brakelight_Info " ";
CM_ SG_ 415 FC_obj13_Taillight_Info " ";
CM_ SG_ 415 FC_Obj13_PhiTop " ";
CM_ SG_ 415 FC_Obj13_PhiRightVel " ";
CM_ SG_ 415 FC_Obj13_PhiRight " ";
CM_ SG_ 415 FC_Obj13_PhiMid " ";
CM_ SG_ 415 FC_Obj13_PhiLeftVel " ";
CM_ SG_ 415 FC_Obj13_PhiLeft " ";
CM_ SG_ 415 FC_Obj13_PhiBottom " ";
CM_ SG_ 415 FC_Obj13_Width " ";
CM_ SG_ 415 FC_Obj13_Length " ";
CM_ SG_ 415 FC_Obj13_Height " ";
CM_ SG_ 415 FC_Obj13_HeadOrientation " ";
CM_ SG_ 415 FC_Obj13_HeadingAngle " ";
CM_ SG_ 415 FC_Obj13_ExistProb " ";
CM_ SG_ 415 FC_Obj13_Dy_Vnce " ";
CM_ SG_ 415 FC_Obj13_Dy " ";
CM_ SG_ 415 FC_Obj13_Dx_Vnce " ";
CM_ SG_ 415 FC_Obj13_Dx " ";
CM_ SG_ 415 FC_Obj13_ClassifiedView " ";
CM_ SG_ 415 FC_Obj13_Vy " ";
CM_ SG_ 415 FC_Obj13_Vx " ";
CM_ SG_ 415 FC_Obj13_Ay " ";
CM_ SG_ 415 FC_Obj13_Ax " ";
CM_ SG_ 415 FC_Obj13_TypeProb " ";
CM_ SG_ 415 FC_Obj13_Type " ";
CM_ SG_ 415 FC_Obj13_Track_Age " ";
CM_ SG_ 415 FC_Obj13_Track_ID " ";
CM_ SG_ 415 FC_Obj13_BlockCtr " ";
CM_ BO_ 416 " ";
CM_ SG_ 416 FC_obj14_Brakelight_Info " ";
CM_ SG_ 416 FC_obj14_Taillight_Info " ";
CM_ SG_ 416 FC_Obj14_PhiTop " ";
CM_ SG_ 416 FC_Obj14_PhiRightVel " ";
CM_ SG_ 416 FC_Obj14_PhiRight " ";
CM_ SG_ 416 FC_Obj14_PhiMid " ";
CM_ SG_ 416 FC_Obj14_PhiLeftVel " ";
CM_ SG_ 416 FC_Obj14_PhiLeft " ";
CM_ SG_ 416 FC_Obj14_PhiBottom " ";
CM_ SG_ 416 FC_Obj14_Width " ";
CM_ SG_ 416 FC_Obj14_Length " ";
CM_ SG_ 416 FC_Obj14_Height " ";
CM_ SG_ 416 FC_Obj14_HeadOrientation " ";
CM_ SG_ 416 FC_Obj14_HeadingAngle " ";
CM_ SG_ 416 FC_Obj14_ExistProb " ";
CM_ SG_ 416 FC_Obj14_Dy_Vnce " ";
CM_ SG_ 416 FC_Obj14_Dy " ";
CM_ SG_ 416 FC_Obj14_Dx_Vnce " ";
CM_ SG_ 416 FC_Obj14_Dx " ";
CM_ SG_ 416 FC_Obj14_ClassifiedView " ";
CM_ SG_ 416 FC_Obj14_Vy " ";
CM_ SG_ 416 FC_Obj14_Vx " ";
CM_ SG_ 416 FC_Obj14_Ay " ";
CM_ SG_ 416 FC_Obj14_Ax " ";
CM_ SG_ 416 FC_Obj14_TypeProb " ";
CM_ SG_ 416 FC_Obj14_Type " ";
CM_ SG_ 416 FC_Obj14_Track_Age " ";
CM_ SG_ 416 FC_Obj14_Track_ID " ";
CM_ SG_ 416 FC_Obj14_BlockCtr " ";
CM_ BO_ 417 " ";
CM_ SG_ 417 FC_obj15_Brakelight_Info " ";
CM_ SG_ 417 FC_obj15_Taillight_Info " ";
CM_ SG_ 417 FC_Obj15_PhiTop " ";
CM_ SG_ 417 FC_Obj15_PhiRightVel " ";
CM_ SG_ 417 FC_Obj15_PhiRight " ";
CM_ SG_ 417 FC_Obj15_PhiMid " ";
CM_ SG_ 417 FC_Obj15_PhiLeftVel " ";
CM_ SG_ 417 FC_Obj15_PhiLeft " ";
CM_ SG_ 417 FC_Obj15_PhiBottom " ";
CM_ SG_ 417 FC_Obj15_Width " ";
CM_ SG_ 417 FC_Obj15_Length " ";
CM_ SG_ 417 FC_Obj15_Height " ";
CM_ SG_ 417 FC_Obj15_HeadOrientation " ";
CM_ SG_ 417 FC_Obj15_HeadingAngle " ";
CM_ SG_ 417 FC_Obj15_ExistProb " ";
CM_ SG_ 417 FC_Obj15_Dy_Vnce " ";
CM_ SG_ 417 FC_Obj15_Dy " ";
CM_ SG_ 417 FC_Obj15_Dx_Vnce " ";
CM_ SG_ 417 FC_Obj15_Dx " ";
CM_ SG_ 417 FC_Obj15_ClassifiedView " ";
CM_ SG_ 417 FC_Obj15_Vy " ";
CM_ SG_ 417 FC_Obj15_Vx " ";
CM_ SG_ 417 FC_Obj15_Ay " ";
CM_ SG_ 417 FC_Obj15_Ax " ";
CM_ SG_ 417 FC_Obj15_TypeProb " ";
CM_ SG_ 417 FC_Obj15_Type " ";
CM_ SG_ 417 FC_Obj15_Track_Age " ";
CM_ SG_ 417 FC_Obj15_Track_ID " ";
CM_ SG_ 417 FC_Obj15_BlockCtr " ";
CM_ BO_ 418 " ";
CM_ SG_ 418 FC_obj16_Brakelight_Info " ";
CM_ SG_ 418 FC_obj16_Taillight_Info " ";
CM_ SG_ 418 FC_Obj16_PhiTop " ";
CM_ SG_ 418 FC_Obj16_PhiRightVel " ";
CM_ SG_ 418 FC_Obj16_PhiRight " ";
CM_ SG_ 418 FC_Obj16_PhiMid " ";
CM_ SG_ 418 FC_Obj16_PhiLeftVel " ";
CM_ SG_ 418 FC_Obj16_PhiLeft " ";
CM_ SG_ 418 FC_Obj16_PhiBottom " ";
CM_ SG_ 418 FC_Obj16_Width " ";
CM_ SG_ 418 FC_Obj16_Length " ";
CM_ SG_ 418 FC_Obj16_Height " ";
CM_ SG_ 418 FC_Obj16_HeadOrientation " ";
CM_ SG_ 418 FC_Obj16_HeadingAngle " ";
CM_ SG_ 418 FC_Obj16_ExistProb " ";
CM_ SG_ 418 FC_Obj16_Dy_Vnce " ";
CM_ SG_ 418 FC_Obj16_Dy " ";
CM_ SG_ 418 FC_Obj16_Dx_Vnce " ";
CM_ SG_ 418 FC_Obj16_Dx " ";
CM_ SG_ 418 FC_Obj16_ClassifiedView " ";
CM_ SG_ 418 FC_Obj16_Vy " ";
CM_ SG_ 418 FC_Obj16_Vx " ";
CM_ SG_ 418 FC_Obj16_Ay " ";
CM_ SG_ 418 FC_Obj16_Ax " ";
CM_ SG_ 418 FC_Obj16_TypeProb " ";
CM_ SG_ 418 FC_Obj16_Type " ";
CM_ SG_ 418 FC_Obj16_Track_Age " ";
CM_ SG_ 418 FC_Obj16_Track_ID " ";
CM_ SG_ 418 FC_Obj16_BlockCtr " ";
CM_ BO_ 419 " ";
CM_ SG_ 419 FC_obj17_Brakelight_Info " ";
CM_ SG_ 419 FC_obj17_Taillight_Info " ";
CM_ SG_ 419 FC_Obj17_PhiTop " ";
CM_ SG_ 419 FC_Obj17_PhiRightVel " ";
CM_ SG_ 419 FC_Obj17_PhiRight " ";
CM_ SG_ 419 FC_Obj17_PhiMid " ";
CM_ SG_ 419 FC_Obj17_PhiLeftVel " ";
CM_ SG_ 419 FC_Obj17_PhiLeft " ";
CM_ SG_ 419 FC_Obj17_PhiBottom " ";
CM_ SG_ 419 FC_Obj17_Width " ";
CM_ SG_ 419 FC_Obj17_Length " ";
CM_ SG_ 419 FC_Obj17_Height " ";
CM_ SG_ 419 FC_Obj17_HeadOrientation " ";
CM_ SG_ 419 FC_Obj17_HeadingAngle " ";
CM_ SG_ 419 FC_Obj17_ExistProb " ";
CM_ SG_ 419 FC_Obj17_Dy_Vnce " ";
CM_ SG_ 419 FC_Obj17_Dy " ";
CM_ SG_ 419 FC_Obj17_Dx_Vnce " ";
CM_ SG_ 419 FC_Obj17_Dx " ";
CM_ SG_ 419 FC_Obj17_ClassifiedView " ";
CM_ SG_ 419 FC_Obj17_Vy " ";
CM_ SG_ 419 FC_Obj17_Vx " ";
CM_ SG_ 419 FC_Obj17_Ay " ";
CM_ SG_ 419 FC_Obj17_Ax " ";
CM_ SG_ 419 FC_Obj17_TypeProb " ";
CM_ SG_ 419 FC_Obj17_Type " ";
CM_ SG_ 419 FC_Obj17_Track_Age " ";
CM_ SG_ 419 FC_Obj17_Track_ID " ";
CM_ SG_ 419 FC_Obj17_BlockCtr " ";
CM_ BO_ 420 " ";
CM_ SG_ 420 FC_obj18_Brakelight_Info " ";
CM_ SG_ 420 FC_obj18_Taillight_Info " ";
CM_ SG_ 420 FC_Obj18_PhiTop " ";
CM_ SG_ 420 FC_Obj18_PhiRightVel " ";
CM_ SG_ 420 FC_Obj18_PhiRight " ";
CM_ SG_ 420 FC_Obj18_PhiMid " ";
CM_ SG_ 420 FC_Obj18_PhiLeftVel " ";
CM_ SG_ 420 FC_Obj18_PhiLeft " ";
CM_ SG_ 420 FC_Obj18_PhiBottom " ";
CM_ SG_ 420 FC_Obj18_Width " ";
CM_ SG_ 420 FC_Obj18_Length " ";
CM_ SG_ 420 FC_Obj18_Height " ";
CM_ SG_ 420 FC_Obj18_HeadOrientation " ";
CM_ SG_ 420 FC_Obj18_HeadingAngle " ";
CM_ SG_ 420 FC_Obj18_ExistProb " ";
CM_ SG_ 420 FC_Obj18_Dy_Vnce " ";
CM_ SG_ 420 FC_Obj18_Dy " ";
CM_ SG_ 420 FC_Obj18_Dx_Vnce " ";
CM_ SG_ 420 FC_Obj18_Dx " ";
CM_ SG_ 420 FC_Obj18_ClassifiedView " ";
CM_ SG_ 420 FC_Obj18_Vy " ";
CM_ SG_ 420 FC_Obj18_Vx " ";
CM_ SG_ 420 FC_Obj18_Ay " ";
CM_ SG_ 420 FC_Obj18_Ax " ";
CM_ SG_ 420 FC_Obj18_TypeProb " ";
CM_ SG_ 420 FC_Obj18_Type " ";
CM_ SG_ 420 FC_Obj18_Track_Age " ";
CM_ SG_ 420 FC_Obj18_Track_ID " ";
CM_ SG_ 420 FC_Obj18_BlockCtr " ";
CM_ BO_ 421 " ";
CM_ SG_ 421 FC_obj19_Brakelight_Info " ";
CM_ SG_ 421 FC_obj19_Taillight_Info " ";
CM_ SG_ 421 FC_Obj19_PhiTop " ";
CM_ SG_ 421 FC_Obj19_PhiRightVel " ";
CM_ SG_ 421 FC_Obj19_PhiRight " ";
CM_ SG_ 421 FC_Obj19_PhiMid " ";
CM_ SG_ 421 FC_Obj19_PhiLeftVel " ";
CM_ SG_ 421 FC_Obj19_PhiLeft " ";
CM_ SG_ 421 FC_Obj19_PhiBottom " ";
CM_ SG_ 421 FC_Obj19_Width " ";
CM_ SG_ 421 FC_Obj19_Length " ";
CM_ SG_ 421 FC_Obj19_Height " ";
CM_ SG_ 421 FC_Obj19_HeadOrientation " ";
CM_ SG_ 421 FC_Obj19_HeadingAngle " ";
CM_ SG_ 421 FC_Obj19_ExistProb " ";
CM_ SG_ 421 FC_Obj19_Dy_Vnce " ";
CM_ SG_ 421 FC_Obj19_Dy " ";
CM_ SG_ 421 FC_Obj19_Dx_Vnce " ";
CM_ SG_ 421 FC_Obj19_Dx " ";
CM_ SG_ 421 FC_Obj19_ClassifiedView " ";
CM_ SG_ 421 FC_Obj19_Vy " ";
CM_ SG_ 421 FC_Obj19_Vx " ";
CM_ SG_ 421 FC_Obj19_Ay " ";
CM_ SG_ 421 FC_Obj19_Ax " ";
CM_ SG_ 421 FC_Obj19_TypeProb " ";
CM_ SG_ 421 FC_Obj19_Type " ";
CM_ SG_ 421 FC_Obj19_Track_Age " ";
CM_ SG_ 421 FC_Obj19_Track_ID " ";
CM_ SG_ 421 FC_Obj19_BlockCtr " ";
CM_ BO_ 422 " ";
CM_ SG_ 422 FC_obj20_Brakelight_Info " ";
CM_ SG_ 422 FC_obj20_Taillight_Info " ";
CM_ SG_ 422 FC_Obj20_PhiTop " ";
CM_ SG_ 422 FC_Obj20_PhiRightVel " ";
CM_ SG_ 422 FC_Obj20_PhiRight " ";
CM_ SG_ 422 FC_Obj20_PhiMid " ";
CM_ SG_ 422 FC_Obj20_PhiLeftVel " ";
CM_ SG_ 422 FC_Obj20_PhiLeft " ";
CM_ SG_ 422 FC_Obj20_PhiBottom " ";
CM_ SG_ 422 FC_Obj20_Width " ";
CM_ SG_ 422 FC_Obj20_Length " ";
CM_ SG_ 422 FC_Obj20_Height " ";
CM_ SG_ 422 FC_Obj20_HeadOrientation " ";
CM_ SG_ 422 FC_Obj20_HeadingAngle " ";
CM_ SG_ 422 FC_Obj20_ExistProb " ";
CM_ SG_ 422 FC_Obj20_Dy_Vnce " ";
CM_ SG_ 422 FC_Obj20_Dy " ";
CM_ SG_ 422 FC_Obj20_Dx_Vnce " ";
CM_ SG_ 422 FC_Obj20_Dx " ";
CM_ SG_ 422 FC_Obj20_ClassifiedView " ";
CM_ SG_ 422 FC_Obj20_Vy " ";
CM_ SG_ 422 FC_Obj20_Vx " ";
CM_ SG_ 422 FC_Obj20_Ay " ";
CM_ SG_ 422 FC_Obj20_Ax " ";
CM_ SG_ 422 FC_Obj20_TypeProb " ";
CM_ SG_ 422 FC_Obj20_Type " ";
CM_ SG_ 422 FC_Obj20_Track_Age " ";
CM_ SG_ 422 FC_Obj20_Track_ID " ";
CM_ SG_ 422 FC_Obj20_BlockCtr " ";
CM_ BO_ 424 " ";
CM_ SG_ 424 FC_TSRRightLaneStatus " ";
CM_ SG_ 424 FC_TSRLeftLaneStatus " ";
CM_ SG_ 424 FC_TSRRightLaneSpdLimit " ";
CM_ SG_ 424 FC_TSRLeftLaneSpdLimit " ";
CM_ SG_ 424 FC_TLAStopLine_HostLane " ";
CM_ SG_ 424 FC_TLADistance_HostLane " ";
CM_ SG_ 424 FC_TLACountDownTime_HostLane " ";
CM_ SG_ 424 FC_HMALightDistribution " ";
CM_ SG_ 424 FC_HMAStatus " ";
CM_ SG_ 424 FC_TSRHostSpdLimitUnits " ";
CM_ SG_ 424 FC_TSRStatus " ";
CM_ SG_ 424 FC_FrontCameraFailureStatus " ";
CM_ SG_ 424 FC_TLAArrowDirection_RightLane " ";
CM_ SG_ 424 FC_TLAObjectType_RightLane " ";
CM_ SG_ 424 FC_TLAObjectStatus_RightLane " ";
CM_ SG_ 424 FC_TLAObjectColour_RightLane " ";
CM_ SG_ 424 FC_TLAObjectDetection_RightLane " ";
CM_ SG_ 424 FC_TLAArrowDirection_LeftLane " ";
CM_ SG_ 424 FC_TLAObjectType_LeftLane " ";
CM_ SG_ 424 FC_TLAObjectStatus_LeftLane " ";
CM_ SG_ 424 FC_TLAObjectColour_LeftLane " ";
CM_ SG_ 424 FC_TLAObjectDetection_LeftLane " ";
CM_ SG_ 424 FC_TLAArrowDirection_HostLane " ";
CM_ SG_ 424 FC_TLAObjectStatus_HostLane " ";
CM_ SG_ 424 FC_TLAObjectType_HostLane " ";
CM_ SG_ 424 FC_TLAObjectColour_HostLane " ";
CM_ SG_ 424 FC_TLAObjectDetection_HostLane " ";
CM_ SG_ 424 FC_TLAWarninglevel " ";
CM_ SG_ 424 FC_TLAStatus " ";
CM_ SG_ 424 FC_TLAEnable " ";
CM_ SG_ 424 FC_FrontCameraCalibrationStatus " ";
CM_ SG_ 424 FC_SLASpdLimit " ";
CM_ SG_ 424 FC_LaneCurvature_80m " ";
CM_ SG_ 424 FC_LaneCurvature_50m " ";
CM_ SG_ 424 FC_LaneCurvature_10m " ";
CM_ SG_ 424 FC_LaneCurvature_0m " ";
CM_ SG_ 424 FC_LaneChangeStatus " ";
CM_ BO_ 444 " ";
CM_ SG_ 444 FC_ELKEnableStatus " ";
CM_ SG_ 444 FC_HostLaneLeftStatus " ";
CM_ SG_ 444 FC_HostLaneRightStatus " ";
CM_ SG_ 444 FC_Voiceinfo " ";
CM_ SG_ 444 FC_ELKInterventionMode " ";
CM_ SG_ 444 FC_ELKMode " ";
CM_ SG_ 444 FC_LKATakeoverReq " ";
CM_ SG_ 444 FC_LKAStatus " ";
CM_ SG_ 444 FC_LDWVibrationWarningReq " ";
CM_ SG_ 444 FC_LDWStatus " ";
CM_ BO_ 445 " ";
CM_ SG_ 445 FC_LatAngReqActive " ";
CM_ SG_ 445 FC_LatAngReq " ";
CM_ SG_ 445 FC_MotorTorqueMinLimitRequest " ";
CM_ SG_ 445 FC_MotorTorqueMaxLimitRequest " ";
CM_ BO_ 447 " ";
CM_ SG_ 447 ADS_SYNC_SyncTime " ";
CM_ SG_ 447 ADS_SYNC_Reserved " ";
CM_ SG_ 447 ADS_SYNC_SGW " ";
CM_ SG_ 447 ADS_SYNC_OVS " ";
CM_ SG_ 447 ADS_SYNC_TimeDomain " ";
CM_ SG_ 447 ADS_SYNC_SequenceCnt " ";
CM_ SG_ 447 ADS_SYNC_CRC " ";
CM_ SG_ 447 ADS_SYNC_Type " ";
CM_ BO_ 448 " ";
CM_ SG_ 448 ADS_UDLCStatus " ";
CM_ SG_ 448 ADS_IACCHWAMode " ";
CM_ BO_ 423 "Processed Line and Track ";
CM_ SG_ 423 FC_PostLine_BlockCtr " ";
CM_ SG_ 423 FC_PostLineTiOut " ";
CM_ SG_ 423 FC_PostLineTiLeap " ";
CM_ SG_ 423 FC_PostLineTiBas " ";
CM_ SG_ 423 FC_PostLineTiStamp " ";
CM_ SG_ 423 FC_Line_Trajectory__dx_Range " ";
CM_ SG_ 423 FC_Line_Trajectory_Reliability " ";
CM_ SG_ 423 FC_Line_Trajectory_Valid " ";
CM_ SG_ 423 FC_Line_Trajectory_curvature_alt " ";
CM_ SG_ 423 FC_Line_Trajectory__curve " ";
CM_ SG_ 423 FC_Line_Trajectory_HeadingAngle " ";
CM_ SG_ 423 FC_Line_Trajectory_dy " ";
CM_ SG_ 423 FC_Line_Right_curvature_alt " ";
CM_ SG_ 423 FC_Line_Right__curve " ";
CM_ SG_ 423 FC_Line_Right_HeadingAngle " ";
CM_ SG_ 423 FC_Line_Right_dy " ";
CM_ SG_ 423 FC_Line_Left_curvature_alt " ";
CM_ SG_ 423 FC_Line_Left__curve " ";
CM_ SG_ 423 FC_Line_Left_HeadingAngle " ";
CM_ SG_ 423 FC_Line_Left_dy " ";
BA_DEF_ SG_  "GenSigStartValue" INT 0 0;
BA_DEF_ SG_  "GenSigInvalidValue" STRING ;
BA_DEF_ SG_  "GenSigCycleTime" INT 0 0;
BA_DEF_ SG_  "GenSigSendType" ENUM  "Cyclic","OnWrite","OnWriteWithRepetition","OnChange","OnChangeWithRepetition","IfActive","IfActiveWithRepetition","NoSigSendType","NotUsed","NotUsed","NotUsed","NotUsed","NotUsed";
BA_DEF_  "Baudrate" INT 0 1000000;
BA_DEF_  "NmType" STRING ;
BA_DEF_  "Manufacturer" STRING ;
BA_DEF_  "VersionYear" INT 2009 2210;
BA_DEF_  "VersionNumber" INT 0 65535;
BA_DEF_  "VersionMonth" INT 0 18;
BA_DEF_  "VersionDay" INT 0 49;
BA_DEF_ BU_  "NodeLayerModules" STRING ;
BA_DEF_ BU_  "ILUsed" ENUM  "No","Yes";
BA_DEF_  "GenNWMTalkNM" STRING ;
BA_DEF_  "GenNWMGotoMode_BusSleep" STRING ;
BA_DEF_  "GenNWMGotoMode_Awake" STRING ;
BA_DEF_  "GenNWMApCanWakeUp" STRING ;
BA_DEF_  "GenNWMApCanSleep" STRING ;
BA_DEF_  "GenNWMApCanOn" STRING ;
BA_DEF_  "GenNWMApCanOff" STRING ;
BA_DEF_  "GenNWMApCanNormal" STRING ;
BA_DEF_  "GenNWMApBusSleep" STRING ;
BA_DEF_ BO_  "GenMsgSendType" ENUM  "Cyclic","Event","NotUsed","NotUsed","NotUsed","Cyclic","NotUsed","IfActive","NoMsgSendType","NotUsed";
BA_DEF_ BO_  "GenMsgILSupport" ENUM  "No","Yes";
BA_DEF_ BO_  "GenMsgCycleTime" INT 0 65535;
BA_DEF_ BO_  "CANFD_BRS" ENUM  "0","1";
BA_DEF_ BO_  "VFrameFormat" ENUM  "StandardCAN","ExtendedCAN","reserved","reserved","reserved","reserved","reserved","reserved","reserved","reserved","reserved","reserved","reserved","reserved","StandardCAN_FD","ExtendedCAN_FD";
BA_DEF_DEF_  "GenSigStartValue" 0;
BA_DEF_DEF_  "GenSigInvalidValue" "/";
BA_DEF_DEF_  "GenSigCycleTime" 0;
BA_DEF_DEF_  "GenSigSendType" "Cyclic";
BA_DEF_DEF_  "Baudrate" 500000;
BA_DEF_DEF_  "NmType" "";
BA_DEF_DEF_  "Manufacturer" "CHANA";
BA_DEF_DEF_  "VersionYear" 2010;
BA_DEF_DEF_  "VersionNumber" 0;
BA_DEF_DEF_  "VersionMonth" 11;
BA_DEF_DEF_  "VersionDay" 0;
BA_DEF_DEF_  "NodeLayerModules" "OSEKNM01.dll,CANoeILNLVector.dll";
BA_DEF_DEF_  "ILUsed" "Yes";
BA_DEF_DEF_  "GenNWMTalkNM" "TalkNM()";
BA_DEF_DEF_  "GenNWMGotoMode_BusSleep" "GotoMode_BusSleep()";
BA_DEF_DEF_  "GenNWMGotoMode_Awake" "GotoMode_Awake()";
BA_DEF_DEF_  "GenNWMApCanWakeUp" "apCanWakeUp()";
BA_DEF_DEF_  "GenNWMApCanSleep" "apCanSleep()";
BA_DEF_DEF_  "GenNWMApCanOn" "apCanOn()";
BA_DEF_DEF_  "GenNWMApCanOff" "apCanOff()";
BA_DEF_DEF_  "GenNWMApCanNormal" "apCanNormal()";
BA_DEF_DEF_  "GenNWMApBusSleep" "apBusSleep()";
BA_DEF_DEF_  "GenMsgSendType" "NoMsgSendType";
BA_DEF_DEF_  "GenMsgILSupport" "Yes";
BA_DEF_DEF_  "GenMsgCycleTime" 0;
BA_DEF_DEF_  "CANFD_BRS" "1";
BA_DEF_DEF_  "VFrameFormat" "StandardCAN";
BA_ "NmType" "OSEK";
BA_ "Baudrate" 2000000;
BA_ "VersionDay" 22;
BA_ "VersionMonth" 6;
BA_ "VersionNumber" 11;
BA_ "VersionYear" 2020;
BA_ "GenMsgSendType" BO_ 400 0;
BA_ "GenMsgCycleTime" BO_ 400 100;
BA_ "VFrameFormat" BO_ 400 14;
BA_ "GenMsgSendType" BO_ 401 0;
BA_ "GenMsgCycleTime" BO_ 401 100;
BA_ "VFrameFormat" BO_ 401 14;
BA_ "GenMsgSendType" BO_ 402 0;
BA_ "GenMsgCycleTime" BO_ 402 100;
BA_ "VFrameFormat" BO_ 402 14;
BA_ "GenMsgSendType" BO_ 403 0;
BA_ "GenMsgCycleTime" BO_ 403 100;
BA_ "VFrameFormat" BO_ 403 14;
BA_ "GenMsgSendType" BO_ 404 0;
BA_ "GenMsgCycleTime" BO_ 404 100;
BA_ "VFrameFormat" BO_ 404 14;
BA_ "GenMsgSendType" BO_ 405 0;
BA_ "GenMsgCycleTime" BO_ 405 60;
BA_ "VFrameFormat" BO_ 405 14;
BA_ "GenMsgSendType" BO_ 406 0;
BA_ "GenMsgCycleTime" BO_ 406 60;
BA_ "VFrameFormat" BO_ 406 14;
BA_ "GenMsgSendType" BO_ 407 0;
BA_ "GenMsgCycleTime" BO_ 407 60;
BA_ "VFrameFormat" BO_ 407 14;
BA_ "GenMsgSendType" BO_ 408 0;
BA_ "GenMsgCycleTime" BO_ 408 60;
BA_ "VFrameFormat" BO_ 408 14;
BA_ "GenMsgSendType" BO_ 409 0;
BA_ "GenMsgCycleTime" BO_ 409 60;
BA_ "VFrameFormat" BO_ 409 14;
BA_ "GenMsgSendType" BO_ 410 0;
BA_ "GenMsgCycleTime" BO_ 410 60;
BA_ "VFrameFormat" BO_ 410 14;
BA_ "GenMsgSendType" BO_ 411 0;
BA_ "GenMsgCycleTime" BO_ 411 60;
BA_ "VFrameFormat" BO_ 411 14;
BA_ "GenMsgSendType" BO_ 412 0;
BA_ "GenMsgCycleTime" BO_ 412 60;
BA_ "VFrameFormat" BO_ 412 14;
BA_ "GenMsgSendType" BO_ 413 0;
BA_ "GenMsgCycleTime" BO_ 413 60;
BA_ "VFrameFormat" BO_ 413 14;
BA_ "GenMsgSendType" BO_ 414 0;
BA_ "GenMsgCycleTime" BO_ 414 60;
BA_ "VFrameFormat" BO_ 414 14;
BA_ "GenMsgSendType" BO_ 415 0;
BA_ "GenMsgCycleTime" BO_ 415 60;
BA_ "VFrameFormat" BO_ 415 14;
BA_ "GenMsgSendType" BO_ 416 0;
BA_ "GenMsgCycleTime" BO_ 416 60;
BA_ "VFrameFormat" BO_ 416 14;
BA_ "GenMsgSendType" BO_ 417 0;
BA_ "GenMsgCycleTime" BO_ 417 60;
BA_ "VFrameFormat" BO_ 417 14;
BA_ "GenMsgSendType" BO_ 418 0;
BA_ "GenMsgCycleTime" BO_ 418 60;
BA_ "VFrameFormat" BO_ 418 14;
BA_ "GenMsgSendType" BO_ 419 0;
BA_ "GenMsgCycleTime" BO_ 419 60;
BA_ "VFrameFormat" BO_ 419 14;
BA_ "GenMsgSendType" BO_ 420 0;
BA_ "GenMsgCycleTime" BO_ 420 60;
BA_ "VFrameFormat" BO_ 420 14;
BA_ "GenMsgSendType" BO_ 421 0;
BA_ "GenMsgCycleTime" BO_ 421 60;
BA_ "VFrameFormat" BO_ 421 14;
BA_ "GenMsgSendType" BO_ 422 0;
BA_ "GenMsgCycleTime" BO_ 422 60;
BA_ "VFrameFormat" BO_ 422 14;
BA_ "GenMsgSendType" BO_ 424 0;
BA_ "GenMsgCycleTime" BO_ 424 20;
BA_ "VFrameFormat" BO_ 424 14;
BA_ "GenMsgSendType" BO_ 444 0;
BA_ "GenMsgCycleTime" BO_ 444 20;
BA_ "VFrameFormat" BO_ 444 14;
BA_ "GenMsgSendType" BO_ 445 0;
BA_ "GenMsgCycleTime" BO_ 445 10;
BA_ "VFrameFormat" BO_ 445 14;
BA_ "GenMsgSendType" BO_ 447 0;
BA_ "GenMsgCycleTime" BO_ 447 20;
BA_ "VFrameFormat" BO_ 447 14;
BA_ "GenMsgSendType" BO_ 448 0;
BA_ "GenMsgCycleTime" BO_ 448 100;
BA_ "VFrameFormat" BO_ 448 14;
BA_ "GenMsgSendType" BO_ 423 0;
BA_ "GenMsgCycleTime" BO_ 423 100;
BA_ "VFrameFormat" BO_ 423 14;
BA_ "GenSigCycleTime" SG_ 400 FC_Line03_BlockCtr 100;
BA_ "GenSigCycleTime" SG_ 400 FC_RollingCounter_190 100;
BA_ "GenSigCycleTime" SG_ 400 FC_CRCCheck_190 100;
BA_ "GenSigCycleTime" SG_ 400 FC_Line_03_MeasureType 100;
BA_ "GenSigStartValue" SG_ 400 FC_Line_03_curvature_alteration 2048;
BA_ "GenSigCycleTime" SG_ 400 FC_Line_03_curvature_alteration 100;
BA_ "GenSigStartValue" SG_ 400 FC_Line_03__curve 4096;
BA_ "GenSigCycleTime" SG_ 400 FC_Line_03__curve 100;
BA_ "GenSigStartValue" SG_ 400 FC_Line_03_HeadingAngle 3277;
BA_ "GenSigCycleTime" SG_ 400 FC_Line_03_HeadingAngle 100;
BA_ "GenSigCycleTime" SG_ 400 FC_Line_03_dy 100;
BA_ "GenSigCycleTime" SG_ 400 FC_Line_03_dx_End_std 100;
BA_ "GenSigCycleTime" SG_ 400 FC_Line_03__dx_End 100;
BA_ "GenSigCycleTime" SG_ 400 FC_Line_03_dx_Start_std 100;
BA_ "GenSigCycleTime" SG_ 400 FC_Line_03_dx_Start 100;
BA_ "GenSigCycleTime" SG_ 400 FC_Line_03_Width 100;
BA_ "GenSigCycleTime" SG_ 400 FC_Line_03_color 100;
BA_ "GenSigStartValue" SG_ 400 FC_Line_03_Id 1;
BA_ "GenSigCycleTime" SG_ 400 FC_Line_03_Id 100;
BA_ "GenSigCycleTime" SG_ 400 FC_Line_03_TypeConfidence 100;
BA_ "GenSigCycleTime" SG_ 400 FC_Line_03_Type 100;
BA_ "GenSigCycleTime" SG_ 400 FC_Line_02__exist_prob 100;
BA_ "GenSigCycleTime" SG_ 400 FC_Line_02_MeasureType 100;
BA_ "GenSigStartValue" SG_ 400 FC_Line_02_curvature_alteration 2048;
BA_ "GenSigCycleTime" SG_ 400 FC_Line_02_curvature_alteration 100;
BA_ "GenSigStartValue" SG_ 400 FC_Line_02__curve 4096;
BA_ "GenSigCycleTime" SG_ 400 FC_Line_02__curve 100;
BA_ "GenSigStartValue" SG_ 400 FC_Line_02_HeadingAngle 3277;
BA_ "GenSigCycleTime" SG_ 400 FC_Line_02_HeadingAngle 100;
BA_ "GenSigCycleTime" SG_ 400 FC_Line_02_dy 100;
BA_ "GenSigCycleTime" SG_ 400 FC_Line_02_dx_End_std 100;
BA_ "GenSigCycleTime" SG_ 400 FC_Line_02__dx_End 100;
BA_ "GenSigCycleTime" SG_ 400 FC_Line_02_dx_Start_std 100;
BA_ "GenSigCycleTime" SG_ 400 FC_Line_02_dx_Start 100;
BA_ "GenSigCycleTime" SG_ 400 FC_Line_02_Width 100;
BA_ "GenSigCycleTime" SG_ 400 FC_Line_02_color 100;
BA_ "GenSigStartValue" SG_ 400 FC_Line_02_Id 1;
BA_ "GenSigCycleTime" SG_ 400 FC_Line_02_Id 100;
BA_ "GenSigCycleTime" SG_ 400 FC_Line_02_TypeConfidence 100;
BA_ "GenSigCycleTime" SG_ 400 FC_Line_02_Type 100;
BA_ "GenSigCycleTime" SG_ 400 FC_Line02_BlockCtr 100;
BA_ "GenSigCycleTime" SG_ 400 FC_Line01_BlockCtr 100;
BA_ "GenSigCycleTime" SG_ 400 FC_LineTiOut 100;
BA_ "GenSigCycleTime" SG_ 400 FC_LineTiLeap 100;
BA_ "GenSigCycleTime" SG_ 400 FC_LineTiBas 100;
BA_ "GenSigCycleTime" SG_ 400 FC_LineTiStamp 100;
BA_ "GenSigCycleTime" SG_ 400 FC_Line_01__exist_prob 100;
BA_ "GenSigCycleTime" SG_ 400 FC_Line_01_MeasureType 100;
BA_ "GenSigStartValue" SG_ 400 FC_Line_01_curvature_alteration 2048;
BA_ "GenSigCycleTime" SG_ 400 FC_Line_01_curvature_alteration 100;
BA_ "GenSigStartValue" SG_ 400 FC_Line_01__curve 4096;
BA_ "GenSigCycleTime" SG_ 400 FC_Line_01__curve 100;
BA_ "GenSigStartValue" SG_ 400 FC_Line_01_HeadingAngle 3277;
BA_ "GenSigCycleTime" SG_ 400 FC_Line_01_HeadingAngle 100;
BA_ "GenSigCycleTime" SG_ 400 FC_Line_01_dy 100;
BA_ "GenSigCycleTime" SG_ 400 FC_Line_01_dx_End_std 100;
BA_ "GenSigCycleTime" SG_ 400 FC_Line_01__dx_End 100;
BA_ "GenSigCycleTime" SG_ 400 FC_Line_01_dx_Start_std 100;
BA_ "GenSigCycleTime" SG_ 400 FC_Line_01_dx_Start 100;
BA_ "GenSigCycleTime" SG_ 400 FC_Line_01_Width 100;
BA_ "GenSigCycleTime" SG_ 400 FC_Line_01_color 100;
BA_ "GenSigStartValue" SG_ 400 FC_Line_01_Id 1;
BA_ "GenSigCycleTime" SG_ 400 FC_Line_01_Id 100;
BA_ "GenSigCycleTime" SG_ 400 FC_Line_01_TypeConfidence 100;
BA_ "GenSigCycleTime" SG_ 400 FC_Line_01_Type 100;
BA_ "GenSigCycleTime" SG_ 401 FC_RollingCounter_191 100;
BA_ "GenSigCycleTime" SG_ 401 FC_CRCCheck_191 100;
BA_ "GenSigCycleTime" SG_ 401 FC_Line_06__exist_prob 100;
BA_ "GenSigCycleTime" SG_ 401 FC_Line_06_MeasureType 100;
BA_ "GenSigStartValue" SG_ 401 FC_Line_06_curvature_alteration 2048;
BA_ "GenSigCycleTime" SG_ 401 FC_Line_06_curvature_alteration 100;
BA_ "GenSigStartValue" SG_ 401 FC_Line_06__curve 4096;
BA_ "GenSigCycleTime" SG_ 401 FC_Line_06__curve 100;
BA_ "GenSigStartValue" SG_ 401 FC_Line_06_HeadingAngle 3277;
BA_ "GenSigCycleTime" SG_ 401 FC_Line_06_HeadingAngle 100;
BA_ "GenSigCycleTime" SG_ 401 FC_Line_06_dy 100;
BA_ "GenSigCycleTime" SG_ 401 FC_Line_06_dx_End_std 100;
BA_ "GenSigCycleTime" SG_ 401 FC_Line_06__dx_End 100;
BA_ "GenSigCycleTime" SG_ 401 FC_Line_06_dx_Start_std 100;
BA_ "GenSigCycleTime" SG_ 401 FC_Line_06_dx_Start 100;
BA_ "GenSigCycleTime" SG_ 401 FC_Line_06_Width 100;
BA_ "GenSigCycleTime" SG_ 401 FC_Line_06_color 100;
BA_ "GenSigStartValue" SG_ 401 FC_Line_06_Id 1;
BA_ "GenSigCycleTime" SG_ 401 FC_Line_06_Id 100;
BA_ "GenSigCycleTime" SG_ 401 FC_Line_06_TypeConfidence 100;
BA_ "GenSigCycleTime" SG_ 401 FC_Line_06_Type 100;
BA_ "GenSigCycleTime" SG_ 401 FC_Line_05__exist_prob 100;
BA_ "GenSigCycleTime" SG_ 401 FC_Line_05_MeasureType 100;
BA_ "GenSigStartValue" SG_ 401 FC_Line_05_curvature_alteration 2048;
BA_ "GenSigCycleTime" SG_ 401 FC_Line_05_curvature_alteration 100;
BA_ "GenSigStartValue" SG_ 401 FC_Line_05__curve 4096;
BA_ "GenSigCycleTime" SG_ 401 FC_Line_05__curve 100;
BA_ "GenSigStartValue" SG_ 401 FC_Line_05_HeadingAngle 3277;
BA_ "GenSigCycleTime" SG_ 401 FC_Line_05_HeadingAngle 100;
BA_ "GenSigCycleTime" SG_ 401 FC_Line_05_dy 100;
BA_ "GenSigCycleTime" SG_ 401 FC_Line_05_dx_End_std 100;
BA_ "GenSigCycleTime" SG_ 401 FC_Line_05__dx_End 100;
BA_ "GenSigCycleTime" SG_ 401 FC_Line_05_dx_Start_std 100;
BA_ "GenSigCycleTime" SG_ 401 FC_Line_05_dx_Start 100;
BA_ "GenSigCycleTime" SG_ 401 FC_Line_05_Width 100;
BA_ "GenSigCycleTime" SG_ 401 FC_Line_05_color 100;
BA_ "GenSigStartValue" SG_ 401 FC_Line_05_Id 1;
BA_ "GenSigCycleTime" SG_ 401 FC_Line_05_Id 100;
BA_ "GenSigCycleTime" SG_ 401 FC_Line_05_TypeConfidence 100;
BA_ "GenSigCycleTime" SG_ 401 FC_Line_05_Type 100;
BA_ "GenSigCycleTime" SG_ 401 FC_Line_04__exist_prob 100;
BA_ "GenSigCycleTime" SG_ 401 FC_Line_04_MeasureType 100;
BA_ "GenSigStartValue" SG_ 401 FC_Line_04_curvature_alteration 2048;
BA_ "GenSigCycleTime" SG_ 401 FC_Line_04_curvature_alteration 100;
BA_ "GenSigStartValue" SG_ 401 FC_Line_04__curve 4096;
BA_ "GenSigCycleTime" SG_ 401 FC_Line_04__curve 100;
BA_ "GenSigStartValue" SG_ 401 FC_Line_04_HeadingAngle 3277;
BA_ "GenSigCycleTime" SG_ 401 FC_Line_04_HeadingAngle 100;
BA_ "GenSigCycleTime" SG_ 401 FC_Line_04_dy 100;
BA_ "GenSigCycleTime" SG_ 401 FC_Line_04_dx_End_std 100;
BA_ "GenSigCycleTime" SG_ 401 FC_Line_04__dx_End 100;
BA_ "GenSigCycleTime" SG_ 401 FC_Line_04_dx_Start_std 100;
BA_ "GenSigCycleTime" SG_ 401 FC_Line_04_dx_Start 100;
BA_ "GenSigCycleTime" SG_ 401 FC_Line_04_Width 100;
BA_ "GenSigCycleTime" SG_ 401 FC_Line_04_color 100;
BA_ "GenSigStartValue" SG_ 401 FC_Line_04_Id 1;
BA_ "GenSigCycleTime" SG_ 401 FC_Line_04_Id 100;
BA_ "GenSigCycleTime" SG_ 401 FC_Line_04_TypeConfidence 100;
BA_ "GenSigCycleTime" SG_ 401 FC_Line_04_Type 100;
BA_ "GenSigCycleTime" SG_ 401 FC_Line_03__exist_prob 100;
BA_ "GenSigCycleTime" SG_ 401 FC_Line06_BlockCtr 100;
BA_ "GenSigCycleTime" SG_ 401 FC_Line05_BlockCtr 100;
BA_ "GenSigCycleTime" SG_ 401 FC_Line04_BlockCtr 100;
BA_ "GenSigCycleTime" SG_ 402 FC_RoadSignTiOut 100;
BA_ "GenSigCycleTime" SG_ 402 FC_RoadSignTiLeap 100;
BA_ "GenSigCycleTime" SG_ 402 FC_RoadSignTiBas 100;
BA_ "GenSigCycleTime" SG_ 402 FC_RoadSignTiStamp 100;
BA_ "GenSigCycleTime" SG_ 402 FC_RollingCounter_192 100;
BA_ "GenSigCycleTime" SG_ 402 FC_CRCCheck_192 100;
BA_ "GenSigCycleTime" SG_ 402 FC_Line_08__exist_prob 100;
BA_ "GenSigCycleTime" SG_ 402 FC_Line_08_MeasureType 100;
BA_ "GenSigStartValue" SG_ 402 FC_Line_08_curvature_alteration 2048;
BA_ "GenSigCycleTime" SG_ 402 FC_Line_08_curvature_alteration 100;
BA_ "GenSigStartValue" SG_ 402 FC_Line_08__curve 4096;
BA_ "GenSigCycleTime" SG_ 402 FC_Line_08__curve 100;
BA_ "GenSigStartValue" SG_ 402 FC_Line_08_HeadingAngle 3277;
BA_ "GenSigCycleTime" SG_ 402 FC_Line_08_HeadingAngle 100;
BA_ "GenSigCycleTime" SG_ 402 FC_Line_08_dy 100;
BA_ "GenSigCycleTime" SG_ 402 FC_Line_08_dx_End_std 100;
BA_ "GenSigCycleTime" SG_ 402 FC_Line_08__dx_End 100;
BA_ "GenSigCycleTime" SG_ 402 FC_Line_08_dx_Start_std 100;
BA_ "GenSigCycleTime" SG_ 402 FC_Line_08_dx_Start 100;
BA_ "GenSigCycleTime" SG_ 402 FC_Line_08_Width 100;
BA_ "GenSigCycleTime" SG_ 402 FC_Line_08_color 100;
BA_ "GenSigStartValue" SG_ 402 FC_Line_08_Id 1;
BA_ "GenSigCycleTime" SG_ 402 FC_Line_08_Id 100;
BA_ "GenSigCycleTime" SG_ 402 FC_Line_08_TypeConfidence 100;
BA_ "GenSigCycleTime" SG_ 402 FC_Line_08_Type 100;
BA_ "GenSigCycleTime" SG_ 402 FC_Line_07__exist_prob 100;
BA_ "GenSigCycleTime" SG_ 402 FC_Line_07_MeasureType 100;
BA_ "GenSigStartValue" SG_ 402 FC_Line_07_curvature_alteration 2048;
BA_ "GenSigCycleTime" SG_ 402 FC_Line_07_curvature_alteration 100;
BA_ "GenSigStartValue" SG_ 402 FC_Line_07__curve 4096;
BA_ "GenSigCycleTime" SG_ 402 FC_Line_07__curve 100;
BA_ "GenSigStartValue" SG_ 402 FC_Line_07_HeadingAngle 3277;
BA_ "GenSigCycleTime" SG_ 402 FC_Line_07_HeadingAngle 100;
BA_ "GenSigCycleTime" SG_ 402 FC_Line_07_dy 100;
BA_ "GenSigCycleTime" SG_ 402 FC_Line_07_dx_End_std 100;
BA_ "GenSigCycleTime" SG_ 402 FC_Line_07__dx_End 100;
BA_ "GenSigCycleTime" SG_ 402 FC_Line_07_dx_Start_std 100;
BA_ "GenSigCycleTime" SG_ 402 FC_Line_07_dx_Start 100;
BA_ "GenSigCycleTime" SG_ 402 FC_Line_07_Width 100;
BA_ "GenSigCycleTime" SG_ 402 FC_Line_07_color 100;
BA_ "GenSigStartValue" SG_ 402 FC_Line_07_Id 1;
BA_ "GenSigCycleTime" SG_ 402 FC_Line_07_Id 100;
BA_ "GenSigCycleTime" SG_ 402 FC_Line_07_TypeConfidence 100;
BA_ "GenSigCycleTime" SG_ 402 FC_Line_07_Type 100;
BA_ "GenSigCycleTime" SG_ 402 FC_Line08_BlockCtr 100;
BA_ "GenSigCycleTime" SG_ 402 FC_Line07_BlockCtr 100;
BA_ "GenSigCycleTime" SG_ 403 FC_SignBoardTiOut 100;
BA_ "GenSigCycleTime" SG_ 403 FC_SignBoardTiLeap 100;
BA_ "GenSigCycleTime" SG_ 403 FC_SignBoardTiBas 100;
BA_ "GenSigCycleTime" SG_ 403 FC_SignBoardTiStamp 100;
BA_ "GenSigCycleTime" SG_ 403 FC_RollingCounter_193 100;
BA_ "GenSigCycleTime" SG_ 403 FC_CRCCheck_193 100;
BA_ "GenSigCycleTime" SG_ 403 FC_SignBoardConfidence_3 100;
BA_ "GenSigCycleTime" SG_ 403 FC_SignBoardLength_3 100;
BA_ "GenSigCycleTime" SG_ 403 FC_SignBoardWidth_3 100;
BA_ "GenSigCycleTime" SG_ 403 FC_SignBoardHeight_3 100;
BA_ "GenSigCycleTime" SG_ 403 FC_SignBoardCenterLatRange_3 100;
BA_ "GenSigCycleTime" SG_ 403 FC_SignBoardCenterLngRange_3 100;
BA_ "GenSigCycleTime" SG_ 403 FC_SpeedLimit_3 100;
BA_ "GenSigCycleTime" SG_ 403 FC_SignBoardType_3 100;
BA_ "GenSigCycleTime" SG_ 403 FC_SignBoardConfidence_2 100;
BA_ "GenSigCycleTime" SG_ 403 FC_SignBoardLength_2 100;
BA_ "GenSigCycleTime" SG_ 403 FC_SignBoardWidth_2 100;
BA_ "GenSigCycleTime" SG_ 403 FC_SignBoardHeight_2 100;
BA_ "GenSigCycleTime" SG_ 403 FC_SignBoardCenterLatRange_2 100;
BA_ "GenSigCycleTime" SG_ 403 FC_SignBoardCenterLngRange_2 100;
BA_ "GenSigCycleTime" SG_ 403 FC_SpeedLimit_2 100;
BA_ "GenSigCycleTime" SG_ 403 FC_SignBoardType_2 100;
BA_ "GenSigCycleTime" SG_ 403 FC_SignBoardConfidence_1 100;
BA_ "GenSigCycleTime" SG_ 403 FC_SignBoardLength_1 100;
BA_ "GenSigCycleTime" SG_ 403 FC_SignBoardWidth_1 100;
BA_ "GenSigCycleTime" SG_ 403 FC_SignBoardHeight_1 100;
BA_ "GenSigCycleTime" SG_ 403 FC_SignBoardCenterLatRange_1 100;
BA_ "GenSigCycleTime" SG_ 403 FC_SignBoardCenterLngRange_1 100;
BA_ "GenSigCycleTime" SG_ 403 FC_SpeedLimit_1 100;
BA_ "GenSigCycleTime" SG_ 403 FC_SignBoardType_1 100;
BA_ "GenSigCycleTime" SG_ 403 FC_RoadSignConfidence_4 100;
BA_ "GenSigCycleTime" SG_ 403 FC_RoadSignLength_4 100;
BA_ "GenSigCycleTime" SG_ 403 FC_RoadSignWidth_4 100;
BA_ "GenSigCycleTime" SG_ 403 FC_RoadSignCenterLatRange_4 100;
BA_ "GenSigCycleTime" SG_ 403 FC_RoadSignCenterLngRange_4 100;
BA_ "GenSigCycleTime" SG_ 403 FC_RoadSignType_4 100;
BA_ "GenSigCycleTime" SG_ 403 FC_RoadSignConfidence_3 100;
BA_ "GenSigCycleTime" SG_ 403 FC_RoadSignLength_3 100;
BA_ "GenSigCycleTime" SG_ 403 FC_RoadSignWidth_3 100;
BA_ "GenSigCycleTime" SG_ 403 FC_RoadSignCenterLatRange_3 100;
BA_ "GenSigCycleTime" SG_ 403 FC_RoadSignCenterLngRange_3 100;
BA_ "GenSigCycleTime" SG_ 403 FC_RoadSignType_3 100;
BA_ "GenSigCycleTime" SG_ 403 FC_RoadSignConfidence_2 100;
BA_ "GenSigCycleTime" SG_ 403 FC_RoadSignLength_2 100;
BA_ "GenSigCycleTime" SG_ 403 FC_RoadSignWidth_2 100;
BA_ "GenSigCycleTime" SG_ 403 FC_RoadSignCenterLatRange_2 100;
BA_ "GenSigCycleTime" SG_ 403 FC_RoadSignCenterLngRange_2 100;
BA_ "GenSigCycleTime" SG_ 403 FC_RoadSignType_2 100;
BA_ "GenSigCycleTime" SG_ 403 FC_RoadSignConfidence_1 100;
BA_ "GenSigCycleTime" SG_ 403 FC_RoadSignLength_1 100;
BA_ "GenSigCycleTime" SG_ 403 FC_RoadSignWidth_1 100;
BA_ "GenSigCycleTime" SG_ 403 FC_RoadSignCenterLatRange_1 100;
BA_ "GenSigCycleTime" SG_ 403 FC_RoadSignCenterLngRange_1 100;
BA_ "GenSigCycleTime" SG_ 403 FC_RoadSignType_1 100;
BA_ "GenSigCycleTime" SG_ 403 FC_SignBoard03_BlockCtr 100;
BA_ "GenSigCycleTime" SG_ 403 FC_SignBoardn02_BlockCtr 100;
BA_ "GenSigCycleTime" SG_ 403 FC_SignBoard01_BlockCtr 100;
BA_ "GenSigCycleTime" SG_ 403 FC_RoadSign04_BlockCtr 100;
BA_ "GenSigCycleTime" SG_ 403 FC_RoadSign03_BlockCtr 100;
BA_ "GenSigCycleTime" SG_ 403 FC_RoadSign02_BlockCtr 100;
BA_ "GenSigCycleTime" SG_ 403 FC_RoadSign01_BlockCtr 100;
BA_ "GenSigCycleTime" SG_ 404 FC_TFLTiOut 100;
BA_ "GenSigCycleTime" SG_ 404 FC_TFLTiLeap 100;
BA_ "GenSigCycleTime" SG_ 404 FC_TFLTiBas 100;
BA_ "GenSigCycleTime" SG_ 404 FC_TFLTiStamp 100;
BA_ "GenSigCycleTime" SG_ 404 FC_RollingCounter_194 100;
BA_ "GenSigCycleTime" SG_ 404 FC_CRCCheck_194 100;
BA_ "GenSigCycleTime" SG_ 404 FC_Num_Of_TFL_Objects 100;
BA_ "GenSigCycleTime" SG_ 404 FC_TFL6_Confidence 100;
BA_ "GenSigCycleTime" SG_ 404 FC_TFL6_Direction 100;
BA_ "GenSigCycleTime" SG_ 404 FC_TFL6_Type 100;
BA_ "GenSigStartValue" SG_ 404 FC_TFL6_PosZ 12;
BA_ "GenSigCycleTime" SG_ 404 FC_TFL6_PosZ 100;
BA_ "GenSigCycleTime" SG_ 404 FC_TFL6_PosY 100;
BA_ "GenSigCycleTime" SG_ 404 FC_TFL6_PosX 100;
BA_ "GenSigCycleTime" SG_ 404 FC_TFL5_Confidence 100;
BA_ "GenSigCycleTime" SG_ 404 FC_TFL5_Direction 100;
BA_ "GenSigCycleTime" SG_ 404 FC_TFL5_Type 100;
BA_ "GenSigStartValue" SG_ 404 FC_TFL5_PosZ 12;
BA_ "GenSigCycleTime" SG_ 404 FC_TFL5_PosZ 100;
BA_ "GenSigCycleTime" SG_ 404 FC_TFL5_PosY 100;
BA_ "GenSigCycleTime" SG_ 404 FC_TFL5_PosX 100;
BA_ "GenSigCycleTime" SG_ 404 FC_TFL4_Confidence 100;
BA_ "GenSigCycleTime" SG_ 404 FC_TFL4_Direction 100;
BA_ "GenSigCycleTime" SG_ 404 FC_TFL4_Type 100;
BA_ "GenSigStartValue" SG_ 404 FC_TFL4_PosZ 12;
BA_ "GenSigCycleTime" SG_ 404 FC_TFL4_PosZ 100;
BA_ "GenSigCycleTime" SG_ 404 FC_TFL4_PosY 100;
BA_ "GenSigCycleTime" SG_ 404 FC_TFL4_PosX 100;
BA_ "GenSigCycleTime" SG_ 404 FC_TFL3_Confidence 100;
BA_ "GenSigCycleTime" SG_ 404 FC_TFL3_Direction 100;
BA_ "GenSigCycleTime" SG_ 404 FC_TFL3_Type 100;
BA_ "GenSigStartValue" SG_ 404 FC_TFL3_PosZ 12;
BA_ "GenSigCycleTime" SG_ 404 FC_TFL3_PosZ 100;
BA_ "GenSigCycleTime" SG_ 404 FC_TFL3_PosY 100;
BA_ "GenSigCycleTime" SG_ 404 FC_TFL3_PosX 100;
BA_ "GenSigCycleTime" SG_ 404 FC_TFL2_Confidence 100;
BA_ "GenSigCycleTime" SG_ 404 FC_TFL2_Direction 100;
BA_ "GenSigCycleTime" SG_ 404 FC_TFL2_Type 100;
BA_ "GenSigStartValue" SG_ 404 FC_TFL2_PosZ 12;
BA_ "GenSigCycleTime" SG_ 404 FC_TFL2_PosZ 100;
BA_ "GenSigCycleTime" SG_ 404 FC_TFL2_PosY 100;
BA_ "GenSigCycleTime" SG_ 404 FC_TFL2_PosX 100;
BA_ "GenSigCycleTime" SG_ 404 FC_TFL1_Confidence 100;
BA_ "GenSigCycleTime" SG_ 404 FC_TFL1_Direction 100;
BA_ "GenSigCycleTime" SG_ 404 FC_TFL1_Type 100;
BA_ "GenSigStartValue" SG_ 404 FC_TFL1_PosZ 12;
BA_ "GenSigCycleTime" SG_ 404 FC_TFL1_PosZ 100;
BA_ "GenSigCycleTime" SG_ 404 FC_TFL1_PosY 100;
BA_ "GenSigCycleTime" SG_ 404 FC_TFL1_PosX 100;
BA_ "GenSigCycleTime" SG_ 404 FC_SignBoardConfidence_4 100;
BA_ "GenSigCycleTime" SG_ 404 FC_SignBoardLength_4 100;
BA_ "GenSigCycleTime" SG_ 404 FC_SignBoardWidth_4 100;
BA_ "GenSigCycleTime" SG_ 404 FC_SignBoardHeight_4 100;
BA_ "GenSigCycleTime" SG_ 404 FC_SignBoardCenterLatRange_4 100;
BA_ "GenSigCycleTime" SG_ 404 FC_SignBoardCenterLngRange_4 100;
BA_ "GenSigCycleTime" SG_ 404 FC_SpeedLimit_4 100;
BA_ "GenSigCycleTime" SG_ 404 FC_SignBoardType_4 100;
BA_ "GenSigCycleTime" SG_ 404 FC_SignBoard04_BlockCtr 100;
BA_ "GenSigCycleTime" SG_ 404 FC_TFL06_BlockCtr 100;
BA_ "GenSigCycleTime" SG_ 404 FC_TFL05_BlockCtr 100;
BA_ "GenSigCycleTime" SG_ 404 FC_TFL04_BlockCtr 100;
BA_ "GenSigCycleTime" SG_ 404 FC_TFL03_BlockCtr 100;
BA_ "GenSigCycleTime" SG_ 404 FC_TFL02_BlockCtr 100;
BA_ "GenSigCycleTime" SG_ 404 FC_TFL01_BlockCtr 100;
BA_ "GenSigCycleTime" SG_ 405 FC_Obj9_Dx_Vnce 60;
BA_ "GenSigCycleTime" SG_ 405 FC_Obj9_Dx 60;
BA_ "GenSigCycleTime" SG_ 405 FC_Obj9_ClassifiedView 60;
BA_ "GenSigCycleTime" SG_ 405 FC_Obj9_Vy 60;
BA_ "GenSigCycleTime" SG_ 405 FC_Obj9_Vx 60;
BA_ "GenSigCycleTime" SG_ 405 FC_Obj9_Ay 60;
BA_ "GenSigCycleTime" SG_ 405 FC_Obj9_Ax 60;
BA_ "GenSigCycleTime" SG_ 405 FC_Obj9_TypeProb 60;
BA_ "GenSigCycleTime" SG_ 405 FC_Obj9_Type 60;
BA_ "GenSigCycleTime" SG_ 405 FC_Obj9_Track_Age 60;
BA_ "GenSigCycleTime" SG_ 405 FC_Obj9_Track_ID 60;
BA_ "GenSigCycleTime" SG_ 405 FC_RollingCounter_195 60;
BA_ "GenSigCycleTime" SG_ 405 FC_CRCCheck_195 60;
BA_ "GenSigCycleTime" SG_ 405 FC_ObjTiOut 60;
BA_ "GenSigCycleTime" SG_ 405 FC_ObjTiLeap 60;
BA_ "GenSigCycleTime" SG_ 405 FC_ObjTiBas 60;
BA_ "GenSigCycleTime" SG_ 405 FC_ObjTiStamp 60;
BA_ "GenSigCycleTime" SG_ 405 FC_obj1_Brakelight_Info 60;
BA_ "GenSigCycleTime" SG_ 405 FC_obj1_Taillight_Info 60;
BA_ "GenSigCycleTime" SG_ 405 FC_Obj1_PhiTop 60;
BA_ "GenSigCycleTime" SG_ 405 FC_Obj1_PhiRightVel 60;
BA_ "GenSigCycleTime" SG_ 405 FC_Obj1_PhiRight 60;
BA_ "GenSigCycleTime" SG_ 405 FC_Obj1_PhiMid 60;
BA_ "GenSigCycleTime" SG_ 405 FC_Obj1_PhiLeftVel 60;
BA_ "GenSigCycleTime" SG_ 405 FC_Obj1_PhiLeft 60;
BA_ "GenSigCycleTime" SG_ 405 FC_Obj1_PhiBottom 60;
BA_ "GenSigCycleTime" SG_ 405 FC_Obj1_Width 60;
BA_ "GenSigCycleTime" SG_ 405 FC_Obj1_Length 60;
BA_ "GenSigCycleTime" SG_ 405 FC_Obj1_Height 60;
BA_ "GenSigCycleTime" SG_ 405 FC_Obj1_HeadOrientation 60;
BA_ "GenSigCycleTime" SG_ 405 FC_Obj1_HeadingAngle 60;
BA_ "GenSigCycleTime" SG_ 405 FC_Obj1_ExistProb 60;
BA_ "GenSigCycleTime" SG_ 405 FC_Obj1_Dy_Vnce 60;
BA_ "GenSigCycleTime" SG_ 405 FC_Obj1_Dy 60;
BA_ "GenSigCycleTime" SG_ 405 FC_Obj1_Dx_Vnce 60;
BA_ "GenSigCycleTime" SG_ 405 FC_Obj1_Dx 60;
BA_ "GenSigCycleTime" SG_ 405 FC_Obj1_ClassifiedView 60;
BA_ "GenSigCycleTime" SG_ 405 FC_Obj1_Vy 60;
BA_ "GenSigCycleTime" SG_ 405 FC_Obj1_Vx 60;
BA_ "GenSigCycleTime" SG_ 405 FC_Obj1_Ay 60;
BA_ "GenSigCycleTime" SG_ 405 FC_Obj1_Ax 60;
BA_ "GenSigCycleTime" SG_ 405 FC_Obj1_TypeProb 60;
BA_ "GenSigCycleTime" SG_ 405 FC_Obj1_Type 60;
BA_ "GenSigCycleTime" SG_ 405 FC_Obj1_Track_Age 60;
BA_ "GenSigCycleTime" SG_ 405 FC_Obj1_Track_ID 60;
BA_ "GenSigCycleTime" SG_ 405 FC_Obj01_BlockCtr 60;
BA_ "GenSigCycleTime" SG_ 406 FC_Obj9_PhiLeft 60;
BA_ "GenSigCycleTime" SG_ 406 FC_Obj9_PhiBottom 60;
BA_ "GenSigCycleTime" SG_ 406 FC_Obj9_Width 60;
BA_ "GenSigCycleTime" SG_ 406 FC_Obj9_Length 60;
BA_ "GenSigCycleTime" SG_ 406 FC_Obj9_Height 60;
BA_ "GenSigCycleTime" SG_ 406 FC_Obj9_HeadOrientation 60;
BA_ "GenSigCycleTime" SG_ 406 FC_Obj9_HeadingAngle 60;
BA_ "GenSigCycleTime" SG_ 406 FC_Obj9_ExistProb 60;
BA_ "GenSigCycleTime" SG_ 406 FC_Obj9_Dy_Vnce 60;
BA_ "GenSigCycleTime" SG_ 406 FC_Obj9_Dy 60;
BA_ "GenSigCycleTime" SG_ 406 FC_RollingCounter_196 60;
BA_ "GenSigCycleTime" SG_ 406 FC_CRCCheck_196 60;
BA_ "GenSigCycleTime" SG_ 406 FC_obj2_Brakelight_Info 60;
BA_ "GenSigCycleTime" SG_ 406 FC_obj2_Taillight_Info 60;
BA_ "GenSigCycleTime" SG_ 406 FC_Obj2_PhiTop 60;
BA_ "GenSigCycleTime" SG_ 406 FC_Obj2_PhiRightVel 60;
BA_ "GenSigCycleTime" SG_ 406 FC_Obj2_PhiRight 60;
BA_ "GenSigCycleTime" SG_ 406 FC_Obj2_PhiMid 60;
BA_ "GenSigCycleTime" SG_ 406 FC_Obj2_PhiLeftVel 60;
BA_ "GenSigCycleTime" SG_ 406 FC_Obj2_PhiLeft 60;
BA_ "GenSigCycleTime" SG_ 406 FC_Obj2_PhiBottom 60;
BA_ "GenSigCycleTime" SG_ 406 FC_Obj2_Width 60;
BA_ "GenSigCycleTime" SG_ 406 FC_Obj2_Length 60;
BA_ "GenSigCycleTime" SG_ 406 FC_Obj2_Height 60;
BA_ "GenSigCycleTime" SG_ 406 FC_Obj2_HeadOrientation 60;
BA_ "GenSigCycleTime" SG_ 406 FC_Obj2_HeadingAngle 60;
BA_ "GenSigCycleTime" SG_ 406 FC_Obj2_ExistProb 60;
BA_ "GenSigCycleTime" SG_ 406 FC_Obj2_Dy_Vnce 60;
BA_ "GenSigCycleTime" SG_ 406 FC_Obj2_Dy 60;
BA_ "GenSigCycleTime" SG_ 406 FC_Obj2_Dx_Vnce 60;
BA_ "GenSigCycleTime" SG_ 406 FC_Obj2_Dx 60;
BA_ "GenSigCycleTime" SG_ 406 FC_Obj2_ClassifiedView 60;
BA_ "GenSigCycleTime" SG_ 406 FC_Obj2_Vy 60;
BA_ "GenSigCycleTime" SG_ 406 FC_Obj2_Vx 60;
BA_ "GenSigCycleTime" SG_ 406 FC_Obj2_Ay 60;
BA_ "GenSigCycleTime" SG_ 406 FC_Obj2_Ax 60;
BA_ "GenSigCycleTime" SG_ 406 FC_Obj2_TypeProb 60;
BA_ "GenSigCycleTime" SG_ 406 FC_Obj2_Type 60;
BA_ "GenSigCycleTime" SG_ 406 FC_Obj2_Track_Age 60;
BA_ "GenSigCycleTime" SG_ 406 FC_Obj2_Track_ID 60;
BA_ "GenSigCycleTime" SG_ 406 FC_Obj09_BlockCtr 60;
BA_ "GenSigCycleTime" SG_ 406 FC_Obj02_BlockCtr 60;
BA_ "GenSigCycleTime" SG_ 407 FC_obj9_Brakelight_Info 60;
BA_ "GenSigCycleTime" SG_ 407 FC_obj9_Taillight_Info 60;
BA_ "GenSigCycleTime" SG_ 407 FC_Obj9_PhiTop 60;
BA_ "GenSigCycleTime" SG_ 407 FC_Obj9_PhiRightVel 60;
BA_ "GenSigCycleTime" SG_ 407 FC_Obj9_PhiRight 60;
BA_ "GenSigCycleTime" SG_ 407 FC_Obj9_PhiMid 60;
BA_ "GenSigCycleTime" SG_ 407 FC_Obj9_PhiLeftVel 60;
BA_ "GenSigCycleTime" SG_ 407 FC_RollingCounter_197 60;
BA_ "GenSigCycleTime" SG_ 407 FC_CRCCheck_197 60;
BA_ "GenSigCycleTime" SG_ 407 FC_obj3_Brakelight_Info 60;
BA_ "GenSigCycleTime" SG_ 407 FC_obj3_Taillight_Info 60;
BA_ "GenSigCycleTime" SG_ 407 FC_Obj3_PhiTop 60;
BA_ "GenSigCycleTime" SG_ 407 FC_Obj3_PhiRightVel 60;
BA_ "GenSigCycleTime" SG_ 407 FC_Obj3_PhiRight 60;
BA_ "GenSigCycleTime" SG_ 407 FC_Obj3_PhiMid 60;
BA_ "GenSigCycleTime" SG_ 407 FC_Obj3_PhiLeftVel 60;
BA_ "GenSigCycleTime" SG_ 407 FC_Obj3_PhiLeft 60;
BA_ "GenSigCycleTime" SG_ 407 FC_Obj3_PhiBottom 60;
BA_ "GenSigCycleTime" SG_ 407 FC_Obj3_Width 60;
BA_ "GenSigCycleTime" SG_ 407 FC_Obj3_Length 60;
BA_ "GenSigCycleTime" SG_ 407 FC_Obj3_Height 60;
BA_ "GenSigCycleTime" SG_ 407 FC_Obj3_HeadOrientation 60;
BA_ "GenSigCycleTime" SG_ 407 FC_Obj3_HeadingAngle 60;
BA_ "GenSigCycleTime" SG_ 407 FC_Obj3_ExistProb 60;
BA_ "GenSigCycleTime" SG_ 407 FC_Obj3_Dy_Vnce 60;
BA_ "GenSigCycleTime" SG_ 407 FC_Obj3_Dy 60;
BA_ "GenSigCycleTime" SG_ 407 FC_Obj3_Dx_Vnce 60;
BA_ "GenSigCycleTime" SG_ 407 FC_Obj3_Dx 60;
BA_ "GenSigCycleTime" SG_ 407 FC_Obj3_ClassifiedView 60;
BA_ "GenSigCycleTime" SG_ 407 FC_Obj3_Vy 60;
BA_ "GenSigCycleTime" SG_ 407 FC_Obj3_Vx 60;
BA_ "GenSigCycleTime" SG_ 407 FC_Obj3_Ay 60;
BA_ "GenSigCycleTime" SG_ 407 FC_Obj3_Ax 60;
BA_ "GenSigCycleTime" SG_ 407 FC_Obj3_TypeProb 60;
BA_ "GenSigCycleTime" SG_ 407 FC_Obj3_Type 60;
BA_ "GenSigCycleTime" SG_ 407 FC_Obj3_Track_Age 60;
BA_ "GenSigCycleTime" SG_ 407 FC_Obj3_Track_ID 60;
BA_ "GenSigCycleTime" SG_ 407 FC_Obj03_BlockCtr 60;
BA_ "GenSigCycleTime" SG_ 408 FC_Obj11_Dx_Vnce 60;
BA_ "GenSigCycleTime" SG_ 408 FC_Obj11_Dx 60;
BA_ "GenSigCycleTime" SG_ 408 FC_Obj11_ClassifiedView 60;
BA_ "GenSigCycleTime" SG_ 408 FC_Obj11_Vy 60;
BA_ "GenSigCycleTime" SG_ 408 FC_Obj11_Vx 60;
BA_ "GenSigCycleTime" SG_ 408 FC_Obj11_Ay 60;
BA_ "GenSigCycleTime" SG_ 408 FC_Obj11_Ax 60;
BA_ "GenSigCycleTime" SG_ 408 FC_Obj11_TypeProb 60;
BA_ "GenSigCycleTime" SG_ 408 FC_Obj11_Type 60;
BA_ "GenSigCycleTime" SG_ 408 FC_Obj11_Track_Age 60;
BA_ "GenSigCycleTime" SG_ 408 FC_Obj11_Track_ID 60;
BA_ "GenSigCycleTime" SG_ 408 FC_RollingCounter_198 60;
BA_ "GenSigCycleTime" SG_ 408 FC_CRCCheck_198 60;
BA_ "GenSigCycleTime" SG_ 408 FC_obj4_Brakelight_Info 60;
BA_ "GenSigCycleTime" SG_ 408 FC_obj4_Taillight_Info 60;
BA_ "GenSigCycleTime" SG_ 408 FC_Obj4_PhiTop 60;
BA_ "GenSigCycleTime" SG_ 408 FC_Obj4_PhiRightVel 60;
BA_ "GenSigCycleTime" SG_ 408 FC_Obj4_PhiRight 60;
BA_ "GenSigCycleTime" SG_ 408 FC_Obj4_PhiMid 60;
BA_ "GenSigCycleTime" SG_ 408 FC_Obj4_PhiLeftVel 60;
BA_ "GenSigCycleTime" SG_ 408 FC_Obj4_PhiLeft 60;
BA_ "GenSigCycleTime" SG_ 408 FC_Obj4_PhiBottom 60;
BA_ "GenSigCycleTime" SG_ 408 FC_Obj4_Width 60;
BA_ "GenSigCycleTime" SG_ 408 FC_Obj4_Length 60;
BA_ "GenSigCycleTime" SG_ 408 FC_Obj4_Height 60;
BA_ "GenSigCycleTime" SG_ 408 FC_Obj4_HeadOrientation 60;
BA_ "GenSigCycleTime" SG_ 408 FC_Obj4_HeadingAngle 60;
BA_ "GenSigCycleTime" SG_ 408 FC_Obj4_ExistProb 60;
BA_ "GenSigCycleTime" SG_ 408 FC_Obj4_Dy_Vnce 60;
BA_ "GenSigCycleTime" SG_ 408 FC_Obj4_Dy 60;
BA_ "GenSigCycleTime" SG_ 408 FC_Obj4_Dx_Vnce 60;
BA_ "GenSigCycleTime" SG_ 408 FC_Obj4_Dx 60;
BA_ "GenSigCycleTime" SG_ 408 FC_Obj4_ClassifiedView 60;
BA_ "GenSigCycleTime" SG_ 408 FC_Obj4_Vy 60;
BA_ "GenSigCycleTime" SG_ 408 FC_Obj4_Vx 60;
BA_ "GenSigCycleTime" SG_ 408 FC_Obj4_Ay 60;
BA_ "GenSigCycleTime" SG_ 408 FC_Obj4_Ax 60;
BA_ "GenSigCycleTime" SG_ 408 FC_Obj4_TypeProb 60;
BA_ "GenSigCycleTime" SG_ 408 FC_Obj4_Type 60;
BA_ "GenSigCycleTime" SG_ 408 FC_Obj4_Track_Age 60;
BA_ "GenSigCycleTime" SG_ 408 FC_Obj4_Track_ID 60;
BA_ "GenSigCycleTime" SG_ 408 FC_Obj04_BlockCtr 60;
BA_ "GenSigCycleTime" SG_ 409 FC_Obj11_PhiLeft 60;
BA_ "GenSigCycleTime" SG_ 409 FC_Obj11_PhiBottom 60;
BA_ "GenSigCycleTime" SG_ 409 FC_Obj11_Width 60;
BA_ "GenSigCycleTime" SG_ 409 FC_Obj11_Length 60;
BA_ "GenSigCycleTime" SG_ 409 FC_Obj11_Height 60;
BA_ "GenSigCycleTime" SG_ 409 FC_Obj11_HeadOrientation 60;
BA_ "GenSigCycleTime" SG_ 409 FC_Obj11_HeadingAngle 60;
BA_ "GenSigCycleTime" SG_ 409 FC_Obj11_ExistProb 60;
BA_ "GenSigCycleTime" SG_ 409 FC_Obj11_Dy_Vnce 60;
BA_ "GenSigCycleTime" SG_ 409 FC_Obj11_Dy 60;
BA_ "GenSigCycleTime" SG_ 409 FC_RollingCounter_199 60;
BA_ "GenSigCycleTime" SG_ 409 FC_CRCCheck_199 60;
BA_ "GenSigCycleTime" SG_ 409 FC_obj5_Brakelight_Info 60;
BA_ "GenSigCycleTime" SG_ 409 FC_obj5_Taillight_Info 60;
BA_ "GenSigCycleTime" SG_ 409 FC_Obj5_PhiTop 60;
BA_ "GenSigCycleTime" SG_ 409 FC_Obj5_PhiRightVel 60;
BA_ "GenSigCycleTime" SG_ 409 FC_Obj5_PhiRight 60;
BA_ "GenSigCycleTime" SG_ 409 FC_Obj5_PhiMid 60;
BA_ "GenSigCycleTime" SG_ 409 FC_Obj5_PhiLeftVel 60;
BA_ "GenSigCycleTime" SG_ 409 FC_Obj5_PhiLeft 60;
BA_ "GenSigCycleTime" SG_ 409 FC_Obj5_PhiBottom 60;
BA_ "GenSigCycleTime" SG_ 409 FC_Obj5_Width 60;
BA_ "GenSigCycleTime" SG_ 409 FC_Obj5_Length 60;
BA_ "GenSigCycleTime" SG_ 409 FC_Obj5_Height 60;
BA_ "GenSigCycleTime" SG_ 409 FC_Obj5_HeadOrientation 60;
BA_ "GenSigCycleTime" SG_ 409 FC_Obj5_HeadingAngle 60;
BA_ "GenSigCycleTime" SG_ 409 FC_Obj5_ExistProb 60;
BA_ "GenSigCycleTime" SG_ 409 FC_Obj5_Dy_Vnce 60;
BA_ "GenSigCycleTime" SG_ 409 FC_Obj5_Dy 60;
BA_ "GenSigCycleTime" SG_ 409 FC_Obj5_Dx_Vnce 60;
BA_ "GenSigCycleTime" SG_ 409 FC_Obj5_Dx 60;
BA_ "GenSigCycleTime" SG_ 409 FC_Obj5_ClassifiedView 60;
BA_ "GenSigCycleTime" SG_ 409 FC_Obj5_Vy 60;
BA_ "GenSigCycleTime" SG_ 409 FC_Obj5_Vx 60;
BA_ "GenSigCycleTime" SG_ 409 FC_Obj5_Ay 60;
BA_ "GenSigCycleTime" SG_ 409 FC_Obj5_Ax 60;
BA_ "GenSigCycleTime" SG_ 409 FC_Obj5_TypeProb 60;
BA_ "GenSigCycleTime" SG_ 409 FC_Obj5_Type 60;
BA_ "GenSigCycleTime" SG_ 409 FC_Obj5_Track_Age 60;
BA_ "GenSigCycleTime" SG_ 409 FC_Obj5_Track_ID 60;
BA_ "GenSigCycleTime" SG_ 409 FC_Obj11_BlockCtr 60;
BA_ "GenSigCycleTime" SG_ 409 FC_Obj05_BlockCtr 60;
BA_ "GenSigCycleTime" SG_ 410 FC_obj11_Brakelight_Info 60;
BA_ "GenSigCycleTime" SG_ 410 FC_obj11_Taillight_Info 60;
BA_ "GenSigCycleTime" SG_ 410 FC_Obj11_PhiTop 60;
BA_ "GenSigCycleTime" SG_ 410 FC_Obj11_PhiRightVel 60;
BA_ "GenSigCycleTime" SG_ 410 FC_Obj11_PhiRight 60;
BA_ "GenSigCycleTime" SG_ 410 FC_Obj11_PhiMid 60;
BA_ "GenSigCycleTime" SG_ 410 FC_Obj11_PhiLeftVel 60;
BA_ "GenSigCycleTime" SG_ 410 FC_RollingCounter_19A 60;
BA_ "GenSigCycleTime" SG_ 410 FC_CRCCheck_19A 60;
BA_ "GenSigCycleTime" SG_ 410 FC_obj6_Brakelight_Info 60;
BA_ "GenSigCycleTime" SG_ 410 FC_obj6_Taillight_Info 60;
BA_ "GenSigCycleTime" SG_ 410 FC_Obj6_PhiTop 60;
BA_ "GenSigCycleTime" SG_ 410 FC_Obj6_PhiRightVel 60;
BA_ "GenSigCycleTime" SG_ 410 FC_Obj6_PhiRight 60;
BA_ "GenSigCycleTime" SG_ 410 FC_Obj6_PhiMid 60;
BA_ "GenSigCycleTime" SG_ 410 FC_Obj6_PhiLeftVel 60;
BA_ "GenSigCycleTime" SG_ 410 FC_Obj6_PhiLeft 60;
BA_ "GenSigCycleTime" SG_ 410 FC_Obj6_PhiBottom 60;
BA_ "GenSigCycleTime" SG_ 410 FC_Obj6_Width 60;
BA_ "GenSigCycleTime" SG_ 410 FC_Obj6_Length 60;
BA_ "GenSigCycleTime" SG_ 410 FC_Obj6_Height 60;
BA_ "GenSigCycleTime" SG_ 410 FC_Obj6_HeadOrientation 60;
BA_ "GenSigCycleTime" SG_ 410 FC_Obj6_HeadingAngle 60;
BA_ "GenSigCycleTime" SG_ 410 FC_Obj6_ExistProb 60;
BA_ "GenSigCycleTime" SG_ 410 FC_Obj6_Dy_Vnce 60;
BA_ "GenSigCycleTime" SG_ 410 FC_Obj6_Dy 60;
BA_ "GenSigCycleTime" SG_ 410 FC_Obj6_Dx_Vnce 60;
BA_ "GenSigCycleTime" SG_ 410 FC_Obj6_Dx 60;
BA_ "GenSigCycleTime" SG_ 410 FC_Obj6_ClassifiedView 60;
BA_ "GenSigCycleTime" SG_ 410 FC_Obj6_Vy 60;
BA_ "GenSigCycleTime" SG_ 410 FC_Obj6_Vx 60;
BA_ "GenSigCycleTime" SG_ 410 FC_Obj6_Ay 60;
BA_ "GenSigCycleTime" SG_ 410 FC_Obj6_Ax 60;
BA_ "GenSigCycleTime" SG_ 410 FC_Obj6_TypeProb 60;
BA_ "GenSigCycleTime" SG_ 410 FC_Obj6_Type 60;
BA_ "GenSigCycleTime" SG_ 410 FC_Obj6_Track_Age 60;
BA_ "GenSigCycleTime" SG_ 410 FC_Obj6_Track_ID 60;
BA_ "GenSigCycleTime" SG_ 410 FC_Obj06_BlockCtr 60;
BA_ "GenSigCycleTime" SG_ 411 FC_RollingCounter_19B 60;
BA_ "GenSigCycleTime" SG_ 411 FC_CRCCheck_19B 60;
BA_ "GenSigCycleTime" SG_ 411 FC_obj7_Brakelight_Info 60;
BA_ "GenSigCycleTime" SG_ 411 FC_obj7_Taillight_Info 60;
BA_ "GenSigCycleTime" SG_ 411 FC_Obj7_PhiTop 60;
BA_ "GenSigCycleTime" SG_ 411 FC_Obj7_PhiRightVel 60;
BA_ "GenSigCycleTime" SG_ 411 FC_Obj7_PhiRight 60;
BA_ "GenSigCycleTime" SG_ 411 FC_Obj7_PhiMid 60;
BA_ "GenSigCycleTime" SG_ 411 FC_Obj7_PhiLeftVel 60;
BA_ "GenSigCycleTime" SG_ 411 FC_Obj7_PhiLeft 60;
BA_ "GenSigCycleTime" SG_ 411 FC_Obj7_PhiBottom 60;
BA_ "GenSigCycleTime" SG_ 411 FC_Obj7_Width 60;
BA_ "GenSigCycleTime" SG_ 411 FC_Obj7_Length 60;
BA_ "GenSigCycleTime" SG_ 411 FC_Obj7_Height 60;
BA_ "GenSigCycleTime" SG_ 411 FC_Obj7_HeadOrientation 60;
BA_ "GenSigCycleTime" SG_ 411 FC_Obj7_HeadingAngle 60;
BA_ "GenSigCycleTime" SG_ 411 FC_Obj7_ExistProb 60;
BA_ "GenSigCycleTime" SG_ 411 FC_Obj7_Dy_Vnce 60;
BA_ "GenSigCycleTime" SG_ 411 FC_Obj7_Dy 60;
BA_ "GenSigCycleTime" SG_ 411 FC_Obj7_Dx_Vnce 60;
BA_ "GenSigCycleTime" SG_ 411 FC_Obj7_Dx 60;
BA_ "GenSigCycleTime" SG_ 411 FC_Obj7_ClassifiedView 60;
BA_ "GenSigCycleTime" SG_ 411 FC_Obj7_Vy 60;
BA_ "GenSigCycleTime" SG_ 411 FC_Obj7_Vx 60;
BA_ "GenSigCycleTime" SG_ 411 FC_Obj7_Ay 60;
BA_ "GenSigCycleTime" SG_ 411 FC_Obj7_Ax 60;
BA_ "GenSigCycleTime" SG_ 411 FC_Obj7_TypeProb 60;
BA_ "GenSigCycleTime" SG_ 411 FC_Obj7_Type 60;
BA_ "GenSigCycleTime" SG_ 411 FC_Obj7_Track_Age 60;
BA_ "GenSigCycleTime" SG_ 411 FC_Obj7_Track_ID 60;
BA_ "GenSigCycleTime" SG_ 411 FC_Obj07_BlockCtr 60;
BA_ "GenSigCycleTime" SG_ 412 FC_RollingCounter_19C 60;
BA_ "GenSigCycleTime" SG_ 412 FC_CRCCheck_19C 60;
BA_ "GenSigCycleTime" SG_ 412 FC_obj8_Brakelight_Info 60;
BA_ "GenSigCycleTime" SG_ 412 FC_obj8_Taillight_Info 60;
BA_ "GenSigCycleTime" SG_ 412 FC_Obj8_PhiTop 60;
BA_ "GenSigCycleTime" SG_ 412 FC_Obj8_PhiRightVel 60;
BA_ "GenSigCycleTime" SG_ 412 FC_Obj8_PhiRight 60;
BA_ "GenSigCycleTime" SG_ 412 FC_Obj8_PhiMid 60;
BA_ "GenSigCycleTime" SG_ 412 FC_Obj8_PhiLeftVel 60;
BA_ "GenSigCycleTime" SG_ 412 FC_Obj8_PhiLeft 60;
BA_ "GenSigCycleTime" SG_ 412 FC_Obj8_PhiBottom 60;
BA_ "GenSigCycleTime" SG_ 412 FC_Obj8_Width 60;
BA_ "GenSigCycleTime" SG_ 412 FC_Obj8_Length 60;
BA_ "GenSigCycleTime" SG_ 412 FC_Obj8_Height 60;
BA_ "GenSigCycleTime" SG_ 412 FC_Obj8_HeadOrientation 60;
BA_ "GenSigCycleTime" SG_ 412 FC_Obj8_HeadingAngle 60;
BA_ "GenSigCycleTime" SG_ 412 FC_Obj8_ExistProb 60;
BA_ "GenSigCycleTime" SG_ 412 FC_Obj8_Dy_Vnce 60;
BA_ "GenSigCycleTime" SG_ 412 FC_Obj8_Dy 60;
BA_ "GenSigCycleTime" SG_ 412 FC_Obj8_Dx_Vnce 60;
BA_ "GenSigCycleTime" SG_ 412 FC_Obj8_Dx 60;
BA_ "GenSigCycleTime" SG_ 412 FC_Obj8_ClassifiedView 60;
BA_ "GenSigCycleTime" SG_ 412 FC_Obj8_Vy 60;
BA_ "GenSigCycleTime" SG_ 412 FC_Obj8_Vx 60;
BA_ "GenSigCycleTime" SG_ 412 FC_Obj8_Ay 60;
BA_ "GenSigCycleTime" SG_ 412 FC_Obj8_Ax 60;
BA_ "GenSigCycleTime" SG_ 412 FC_Obj8_TypeProb 60;
BA_ "GenSigCycleTime" SG_ 412 FC_Obj8_Type 60;
BA_ "GenSigCycleTime" SG_ 412 FC_Obj8_Track_Age 60;
BA_ "GenSigCycleTime" SG_ 412 FC_Obj8_Track_ID 60;
BA_ "GenSigCycleTime" SG_ 412 FC_Obj08_BlockCtr 60;
BA_ "GenSigCycleTime" SG_ 413 FC_RollingCounter_19D 60;
BA_ "GenSigCycleTime" SG_ 413 FC_CRCCheck_19D 60;
BA_ "GenSigCycleTime" SG_ 413 FC_obj10_Brakelight_Info 60;
BA_ "GenSigCycleTime" SG_ 413 FC_obj10_Taillight_Info 60;
BA_ "GenSigCycleTime" SG_ 413 FC_Obj10_PhiTop 60;
BA_ "GenSigCycleTime" SG_ 413 FC_Obj10_PhiRightVel 60;
BA_ "GenSigCycleTime" SG_ 413 FC_Obj10_PhiRight 60;
BA_ "GenSigCycleTime" SG_ 413 FC_Obj10_PhiMid 60;
BA_ "GenSigCycleTime" SG_ 413 FC_Obj10_PhiLeftVel 60;
BA_ "GenSigCycleTime" SG_ 413 FC_Obj10_PhiLeft 60;
BA_ "GenSigCycleTime" SG_ 413 FC_Obj10_PhiBottom 60;
BA_ "GenSigCycleTime" SG_ 413 FC_Obj10_Width 60;
BA_ "GenSigCycleTime" SG_ 413 FC_Obj10_Length 60;
BA_ "GenSigCycleTime" SG_ 413 FC_Obj10_Height 60;
BA_ "GenSigCycleTime" SG_ 413 FC_Obj10_HeadOrientation 60;
BA_ "GenSigCycleTime" SG_ 413 FC_Obj10_HeadingAngle 60;
BA_ "GenSigCycleTime" SG_ 413 FC_Obj10_ExistProb 60;
BA_ "GenSigCycleTime" SG_ 413 FC_Obj10_Dy_Vnce 60;
BA_ "GenSigCycleTime" SG_ 413 FC_Obj10_Dy 60;
BA_ "GenSigCycleTime" SG_ 413 FC_Obj10_Dx_Vnce 60;
BA_ "GenSigCycleTime" SG_ 413 FC_Obj10_Dx 60;
BA_ "GenSigCycleTime" SG_ 413 FC_Obj10_ClassifiedView 60;
BA_ "GenSigCycleTime" SG_ 413 FC_Obj10_Vy 60;
BA_ "GenSigCycleTime" SG_ 413 FC_Obj10_Vx 60;
BA_ "GenSigCycleTime" SG_ 413 FC_Obj10_Ay 60;
BA_ "GenSigCycleTime" SG_ 413 FC_Obj10_Ax 60;
BA_ "GenSigCycleTime" SG_ 413 FC_Obj10_TypeProb 60;
BA_ "GenSigCycleTime" SG_ 413 FC_Obj10_Type 60;
BA_ "GenSigCycleTime" SG_ 413 FC_Obj10_Track_Age 60;
BA_ "GenSigCycleTime" SG_ 413 FC_Obj10_Track_ID 60;
BA_ "GenSigCycleTime" SG_ 413 FC_Obj10_BlockCtr 60;
BA_ "GenSigCycleTime" SG_ 414 FC_RollingCounter_19E 60;
BA_ "GenSigCycleTime" SG_ 414 FC_CRCCheck_19E 60;
BA_ "GenSigCycleTime" SG_ 414 FC_obj12_Brakelight_Info 60;
BA_ "GenSigCycleTime" SG_ 414 FC_obj12_Taillight_Info 60;
BA_ "GenSigCycleTime" SG_ 414 FC_Obj12_PhiTop 60;
BA_ "GenSigCycleTime" SG_ 414 FC_Obj12_PhiRightVel 60;
BA_ "GenSigCycleTime" SG_ 414 FC_Obj12_PhiRight 60;
BA_ "GenSigCycleTime" SG_ 414 FC_Obj12_PhiMid 60;
BA_ "GenSigCycleTime" SG_ 414 FC_Obj12_PhiLeftVel 60;
BA_ "GenSigCycleTime" SG_ 414 FC_Obj12_PhiLeft 60;
BA_ "GenSigCycleTime" SG_ 414 FC_Obj12_PhiBottom 60;
BA_ "GenSigCycleTime" SG_ 414 FC_Obj12_Width 60;
BA_ "GenSigCycleTime" SG_ 414 FC_Obj12_Length 60;
BA_ "GenSigCycleTime" SG_ 414 FC_Obj12_Height 60;
BA_ "GenSigCycleTime" SG_ 414 FC_Obj12_HeadOrientation 60;
BA_ "GenSigCycleTime" SG_ 414 FC_Obj12_HeadingAngle 60;
BA_ "GenSigCycleTime" SG_ 414 FC_Obj12_ExistProb 60;
BA_ "GenSigCycleTime" SG_ 414 FC_Obj12_Dy_Vnce 60;
BA_ "GenSigCycleTime" SG_ 414 FC_Obj12_Dy 60;
BA_ "GenSigCycleTime" SG_ 414 FC_Obj12_Dx_Vnce 60;
BA_ "GenSigCycleTime" SG_ 414 FC_Obj12_Dx 60;
BA_ "GenSigCycleTime" SG_ 414 FC_Obj12_ClassifiedView 60;
BA_ "GenSigCycleTime" SG_ 414 FC_Obj12_Vy 60;
BA_ "GenSigCycleTime" SG_ 414 FC_Obj12_Vx 60;
BA_ "GenSigCycleTime" SG_ 414 FC_Obj12_Ay 60;
BA_ "GenSigCycleTime" SG_ 414 FC_Obj12_Ax 60;
BA_ "GenSigCycleTime" SG_ 414 FC_Obj12_TypeProb 60;
BA_ "GenSigCycleTime" SG_ 414 FC_Obj12_Type 60;
BA_ "GenSigCycleTime" SG_ 414 FC_Obj12_Track_Age 60;
BA_ "GenSigCycleTime" SG_ 414 FC_Obj12_Track_ID 60;
BA_ "GenSigCycleTime" SG_ 414 FC_Obj12_BlockCtr 60;
BA_ "GenSigCycleTime" SG_ 415 FC_RollingCounter_19F 60;
BA_ "GenSigCycleTime" SG_ 415 FC_CRCCheck_19F 60;
BA_ "GenSigCycleTime" SG_ 415 FC_obj13_Brakelight_Info 60;
BA_ "GenSigCycleTime" SG_ 415 FC_obj13_Taillight_Info 60;
BA_ "GenSigCycleTime" SG_ 415 FC_Obj13_PhiTop 60;
BA_ "GenSigCycleTime" SG_ 415 FC_Obj13_PhiRightVel 60;
BA_ "GenSigCycleTime" SG_ 415 FC_Obj13_PhiRight 60;
BA_ "GenSigCycleTime" SG_ 415 FC_Obj13_PhiMid 60;
BA_ "GenSigCycleTime" SG_ 415 FC_Obj13_PhiLeftVel 60;
BA_ "GenSigCycleTime" SG_ 415 FC_Obj13_PhiLeft 60;
BA_ "GenSigCycleTime" SG_ 415 FC_Obj13_PhiBottom 60;
BA_ "GenSigCycleTime" SG_ 415 FC_Obj13_Width 60;
BA_ "GenSigCycleTime" SG_ 415 FC_Obj13_Length 60;
BA_ "GenSigCycleTime" SG_ 415 FC_Obj13_Height 60;
BA_ "GenSigCycleTime" SG_ 415 FC_Obj13_HeadOrientation 60;
BA_ "GenSigCycleTime" SG_ 415 FC_Obj13_HeadingAngle 60;
BA_ "GenSigCycleTime" SG_ 415 FC_Obj13_ExistProb 60;
BA_ "GenSigCycleTime" SG_ 415 FC_Obj13_Dy_Vnce 60;
BA_ "GenSigCycleTime" SG_ 415 FC_Obj13_Dy 60;
BA_ "GenSigCycleTime" SG_ 415 FC_Obj13_Dx_Vnce 60;
BA_ "GenSigCycleTime" SG_ 415 FC_Obj13_Dx 60;
BA_ "GenSigCycleTime" SG_ 415 FC_Obj13_ClassifiedView 60;
BA_ "GenSigCycleTime" SG_ 415 FC_Obj13_Vy 60;
BA_ "GenSigCycleTime" SG_ 415 FC_Obj13_Vx 60;
BA_ "GenSigCycleTime" SG_ 415 FC_Obj13_Ay 60;
BA_ "GenSigCycleTime" SG_ 415 FC_Obj13_Ax 60;
BA_ "GenSigCycleTime" SG_ 415 FC_Obj13_TypeProb 60;
BA_ "GenSigCycleTime" SG_ 415 FC_Obj13_Type 60;
BA_ "GenSigCycleTime" SG_ 415 FC_Obj13_Track_Age 60;
BA_ "GenSigCycleTime" SG_ 415 FC_Obj13_Track_ID 60;
BA_ "GenSigCycleTime" SG_ 415 FC_Obj13_BlockCtr 60;
BA_ "GenSigCycleTime" SG_ 416 FC_RollingCounter_1A0 60;
BA_ "GenSigCycleTime" SG_ 416 FC_CRCCheck_1A0 60;
BA_ "GenSigCycleTime" SG_ 416 FC_obj14_Brakelight_Info 60;
BA_ "GenSigCycleTime" SG_ 416 FC_obj14_Taillight_Info 60;
BA_ "GenSigCycleTime" SG_ 416 FC_Obj14_PhiTop 60;
BA_ "GenSigCycleTime" SG_ 416 FC_Obj14_PhiRightVel 60;
BA_ "GenSigCycleTime" SG_ 416 FC_Obj14_PhiRight 60;
BA_ "GenSigCycleTime" SG_ 416 FC_Obj14_PhiMid 60;
BA_ "GenSigCycleTime" SG_ 416 FC_Obj14_PhiLeftVel 60;
BA_ "GenSigCycleTime" SG_ 416 FC_Obj14_PhiLeft 60;
BA_ "GenSigCycleTime" SG_ 416 FC_Obj14_PhiBottom 60;
BA_ "GenSigCycleTime" SG_ 416 FC_Obj14_Width 60;
BA_ "GenSigCycleTime" SG_ 416 FC_Obj14_Length 60;
BA_ "GenSigCycleTime" SG_ 416 FC_Obj14_Height 60;
BA_ "GenSigCycleTime" SG_ 416 FC_Obj14_HeadOrientation 60;
BA_ "GenSigCycleTime" SG_ 416 FC_Obj14_HeadingAngle 60;
BA_ "GenSigCycleTime" SG_ 416 FC_Obj14_ExistProb 60;
BA_ "GenSigCycleTime" SG_ 416 FC_Obj14_Dy_Vnce 60;
BA_ "GenSigCycleTime" SG_ 416 FC_Obj14_Dy 60;
BA_ "GenSigCycleTime" SG_ 416 FC_Obj14_Dx_Vnce 60;
BA_ "GenSigCycleTime" SG_ 416 FC_Obj14_Dx 60;
BA_ "GenSigCycleTime" SG_ 416 FC_Obj14_ClassifiedView 60;
BA_ "GenSigCycleTime" SG_ 416 FC_Obj14_Vy 60;
BA_ "GenSigCycleTime" SG_ 416 FC_Obj14_Vx 60;
BA_ "GenSigCycleTime" SG_ 416 FC_Obj14_Ay 60;
BA_ "GenSigCycleTime" SG_ 416 FC_Obj14_Ax 60;
BA_ "GenSigCycleTime" SG_ 416 FC_Obj14_TypeProb 60;
BA_ "GenSigCycleTime" SG_ 416 FC_Obj14_Type 60;
BA_ "GenSigCycleTime" SG_ 416 FC_Obj14_Track_Age 60;
BA_ "GenSigCycleTime" SG_ 416 FC_Obj14_Track_ID 60;
BA_ "GenSigCycleTime" SG_ 416 FC_Obj14_BlockCtr 60;
BA_ "GenSigCycleTime" SG_ 417 FC_RollingCounter_1A1 60;
BA_ "GenSigCycleTime" SG_ 417 FC_CRCCheck_1A1 60;
BA_ "GenSigCycleTime" SG_ 417 FC_obj15_Brakelight_Info 60;
BA_ "GenSigCycleTime" SG_ 417 FC_obj15_Taillight_Info 60;
BA_ "GenSigCycleTime" SG_ 417 FC_Obj15_PhiTop 60;
BA_ "GenSigCycleTime" SG_ 417 FC_Obj15_PhiRightVel 60;
BA_ "GenSigCycleTime" SG_ 417 FC_Obj15_PhiRight 60;
BA_ "GenSigCycleTime" SG_ 417 FC_Obj15_PhiMid 60;
BA_ "GenSigCycleTime" SG_ 417 FC_Obj15_PhiLeftVel 60;
BA_ "GenSigCycleTime" SG_ 417 FC_Obj15_PhiLeft 60;
BA_ "GenSigCycleTime" SG_ 417 FC_Obj15_PhiBottom 60;
BA_ "GenSigCycleTime" SG_ 417 FC_Obj15_Width 60;
BA_ "GenSigCycleTime" SG_ 417 FC_Obj15_Length 60;
BA_ "GenSigCycleTime" SG_ 417 FC_Obj15_Height 60;
BA_ "GenSigCycleTime" SG_ 417 FC_Obj15_HeadOrientation 60;
BA_ "GenSigCycleTime" SG_ 417 FC_Obj15_HeadingAngle 60;
BA_ "GenSigCycleTime" SG_ 417 FC_Obj15_ExistProb 60;
BA_ "GenSigCycleTime" SG_ 417 FC_Obj15_Dy_Vnce 60;
BA_ "GenSigCycleTime" SG_ 417 FC_Obj15_Dy 60;
BA_ "GenSigCycleTime" SG_ 417 FC_Obj15_Dx_Vnce 60;
BA_ "GenSigCycleTime" SG_ 417 FC_Obj15_Dx 60;
BA_ "GenSigCycleTime" SG_ 417 FC_Obj15_ClassifiedView 60;
BA_ "GenSigCycleTime" SG_ 417 FC_Obj15_Vy 60;
BA_ "GenSigCycleTime" SG_ 417 FC_Obj15_Vx 60;
BA_ "GenSigCycleTime" SG_ 417 FC_Obj15_Ay 60;
BA_ "GenSigCycleTime" SG_ 417 FC_Obj15_Ax 60;
BA_ "GenSigCycleTime" SG_ 417 FC_Obj15_TypeProb 60;
BA_ "GenSigCycleTime" SG_ 417 FC_Obj15_Type 60;
BA_ "GenSigCycleTime" SG_ 417 FC_Obj15_Track_Age 60;
BA_ "GenSigCycleTime" SG_ 417 FC_Obj15_Track_ID 60;
BA_ "GenSigCycleTime" SG_ 417 FC_Obj15_BlockCtr 60;
BA_ "GenSigCycleTime" SG_ 418 FC_RollingCounter_1A2 60;
BA_ "GenSigCycleTime" SG_ 418 FC_CRCCheck_1A2 60;
BA_ "GenSigCycleTime" SG_ 418 FC_obj16_Brakelight_Info 60;
BA_ "GenSigCycleTime" SG_ 418 FC_obj16_Taillight_Info 60;
BA_ "GenSigCycleTime" SG_ 418 FC_Obj16_PhiTop 60;
BA_ "GenSigCycleTime" SG_ 418 FC_Obj16_PhiRightVel 60;
BA_ "GenSigCycleTime" SG_ 418 FC_Obj16_PhiRight 60;
BA_ "GenSigCycleTime" SG_ 418 FC_Obj16_PhiMid 60;
BA_ "GenSigCycleTime" SG_ 418 FC_Obj16_PhiLeftVel 60;
BA_ "GenSigCycleTime" SG_ 418 FC_Obj16_PhiLeft 60;
BA_ "GenSigCycleTime" SG_ 418 FC_Obj16_PhiBottom 60;
BA_ "GenSigCycleTime" SG_ 418 FC_Obj16_Width 60;
BA_ "GenSigCycleTime" SG_ 418 FC_Obj16_Length 60;
BA_ "GenSigCycleTime" SG_ 418 FC_Obj16_Height 60;
BA_ "GenSigCycleTime" SG_ 418 FC_Obj16_HeadOrientation 60;
BA_ "GenSigCycleTime" SG_ 418 FC_Obj16_HeadingAngle 60;
BA_ "GenSigCycleTime" SG_ 418 FC_Obj16_ExistProb 60;
BA_ "GenSigCycleTime" SG_ 418 FC_Obj16_Dy_Vnce 60;
BA_ "GenSigCycleTime" SG_ 418 FC_Obj16_Dy 60;
BA_ "GenSigCycleTime" SG_ 418 FC_Obj16_Dx_Vnce 60;
BA_ "GenSigCycleTime" SG_ 418 FC_Obj16_Dx 60;
BA_ "GenSigCycleTime" SG_ 418 FC_Obj16_ClassifiedView 60;
BA_ "GenSigCycleTime" SG_ 418 FC_Obj16_Vy 60;
BA_ "GenSigCycleTime" SG_ 418 FC_Obj16_Vx 60;
BA_ "GenSigCycleTime" SG_ 418 FC_Obj16_Ay 60;
BA_ "GenSigCycleTime" SG_ 418 FC_Obj16_Ax 60;
BA_ "GenSigCycleTime" SG_ 418 FC_Obj16_TypeProb 60;
BA_ "GenSigCycleTime" SG_ 418 FC_Obj16_Type 60;
BA_ "GenSigCycleTime" SG_ 418 FC_Obj16_Track_Age 60;
BA_ "GenSigCycleTime" SG_ 418 FC_Obj16_Track_ID 60;
BA_ "GenSigCycleTime" SG_ 418 FC_Obj16_BlockCtr 60;
BA_ "GenSigCycleTime" SG_ 419 FC_RollingCounter_1A3 60;
BA_ "GenSigCycleTime" SG_ 419 FC_CRCCheck_1A3 60;
BA_ "GenSigCycleTime" SG_ 419 FC_obj17_Brakelight_Info 60;
BA_ "GenSigCycleTime" SG_ 419 FC_obj17_Taillight_Info 60;
BA_ "GenSigCycleTime" SG_ 419 FC_Obj17_PhiTop 60;
BA_ "GenSigCycleTime" SG_ 419 FC_Obj17_PhiRightVel 60;
BA_ "GenSigCycleTime" SG_ 419 FC_Obj17_PhiRight 60;
BA_ "GenSigCycleTime" SG_ 419 FC_Obj17_PhiMid 60;
BA_ "GenSigCycleTime" SG_ 419 FC_Obj17_PhiLeftVel 60;
BA_ "GenSigCycleTime" SG_ 419 FC_Obj17_PhiLeft 60;
BA_ "GenSigCycleTime" SG_ 419 FC_Obj17_PhiBottom 60;
BA_ "GenSigCycleTime" SG_ 419 FC_Obj17_Width 60;
BA_ "GenSigCycleTime" SG_ 419 FC_Obj17_Length 60;
BA_ "GenSigCycleTime" SG_ 419 FC_Obj17_Height 60;
BA_ "GenSigCycleTime" SG_ 419 FC_Obj17_HeadOrientation 60;
BA_ "GenSigCycleTime" SG_ 419 FC_Obj17_HeadingAngle 60;
BA_ "GenSigCycleTime" SG_ 419 FC_Obj17_ExistProb 60;
BA_ "GenSigCycleTime" SG_ 419 FC_Obj17_Dy_Vnce 60;
BA_ "GenSigCycleTime" SG_ 419 FC_Obj17_Dy 60;
BA_ "GenSigCycleTime" SG_ 419 FC_Obj17_Dx_Vnce 60;
BA_ "GenSigCycleTime" SG_ 419 FC_Obj17_Dx 60;
BA_ "GenSigCycleTime" SG_ 419 FC_Obj17_ClassifiedView 60;
BA_ "GenSigCycleTime" SG_ 419 FC_Obj17_Vy 60;
BA_ "GenSigCycleTime" SG_ 419 FC_Obj17_Vx 60;
BA_ "GenSigCycleTime" SG_ 419 FC_Obj17_Ay 60;
BA_ "GenSigCycleTime" SG_ 419 FC_Obj17_Ax 60;
BA_ "GenSigCycleTime" SG_ 419 FC_Obj17_TypeProb 60;
BA_ "GenSigCycleTime" SG_ 419 FC_Obj17_Type 60;
BA_ "GenSigCycleTime" SG_ 419 FC_Obj17_Track_Age 60;
BA_ "GenSigCycleTime" SG_ 419 FC_Obj17_Track_ID 60;
BA_ "GenSigCycleTime" SG_ 419 FC_Obj17_BlockCtr 60;
BA_ "GenSigCycleTime" SG_ 420 FC_RollingCounter_1A4 60;
BA_ "GenSigCycleTime" SG_ 420 FC_CRCCheck_1A4 60;
BA_ "GenSigCycleTime" SG_ 420 FC_obj18_Brakelight_Info 60;
BA_ "GenSigCycleTime" SG_ 420 FC_obj18_Taillight_Info 60;
BA_ "GenSigCycleTime" SG_ 420 FC_Obj18_PhiTop 60;
BA_ "GenSigCycleTime" SG_ 420 FC_Obj18_PhiRightVel 60;
BA_ "GenSigCycleTime" SG_ 420 FC_Obj18_PhiRight 60;
BA_ "GenSigCycleTime" SG_ 420 FC_Obj18_PhiMid 60;
BA_ "GenSigCycleTime" SG_ 420 FC_Obj18_PhiLeftVel 60;
BA_ "GenSigCycleTime" SG_ 420 FC_Obj18_PhiLeft 60;
BA_ "GenSigCycleTime" SG_ 420 FC_Obj18_PhiBottom 60;
BA_ "GenSigCycleTime" SG_ 420 FC_Obj18_Width 60;
BA_ "GenSigCycleTime" SG_ 420 FC_Obj18_Length 60;
BA_ "GenSigCycleTime" SG_ 420 FC_Obj18_Height 60;
BA_ "GenSigCycleTime" SG_ 420 FC_Obj18_HeadOrientation 60;
BA_ "GenSigCycleTime" SG_ 420 FC_Obj18_HeadingAngle 60;
BA_ "GenSigCycleTime" SG_ 420 FC_Obj18_ExistProb 60;
BA_ "GenSigCycleTime" SG_ 420 FC_Obj18_Dy_Vnce 60;
BA_ "GenSigCycleTime" SG_ 420 FC_Obj18_Dy 60;
BA_ "GenSigCycleTime" SG_ 420 FC_Obj18_Dx_Vnce 60;
BA_ "GenSigCycleTime" SG_ 420 FC_Obj18_Dx 60;
BA_ "GenSigCycleTime" SG_ 420 FC_Obj18_ClassifiedView 60;
BA_ "GenSigCycleTime" SG_ 420 FC_Obj18_Vy 60;
BA_ "GenSigCycleTime" SG_ 420 FC_Obj18_Vx 60;
BA_ "GenSigCycleTime" SG_ 420 FC_Obj18_Ay 60;
BA_ "GenSigCycleTime" SG_ 420 FC_Obj18_Ax 60;
BA_ "GenSigCycleTime" SG_ 420 FC_Obj18_TypeProb 60;
BA_ "GenSigCycleTime" SG_ 420 FC_Obj18_Type 60;
BA_ "GenSigCycleTime" SG_ 420 FC_Obj18_Track_Age 60;
BA_ "GenSigCycleTime" SG_ 420 FC_Obj18_Track_ID 60;
BA_ "GenSigCycleTime" SG_ 420 FC_Obj18_BlockCtr 60;
BA_ "GenSigCycleTime" SG_ 421 FC_RollingCounter_1A5 60;
BA_ "GenSigCycleTime" SG_ 421 FC_CRCCheck_1A5 60;
BA_ "GenSigCycleTime" SG_ 421 FC_obj19_Brakelight_Info 60;
BA_ "GenSigCycleTime" SG_ 421 FC_obj19_Taillight_Info 60;
BA_ "GenSigCycleTime" SG_ 421 FC_Obj19_PhiTop 60;
BA_ "GenSigCycleTime" SG_ 421 FC_Obj19_PhiRightVel 60;
BA_ "GenSigCycleTime" SG_ 421 FC_Obj19_PhiRight 60;
BA_ "GenSigCycleTime" SG_ 421 FC_Obj19_PhiMid 60;
BA_ "GenSigCycleTime" SG_ 421 FC_Obj19_PhiLeftVel 60;
BA_ "GenSigCycleTime" SG_ 421 FC_Obj19_PhiLeft 60;
BA_ "GenSigCycleTime" SG_ 421 FC_Obj19_PhiBottom 60;
BA_ "GenSigCycleTime" SG_ 421 FC_Obj19_Width 60;
BA_ "GenSigCycleTime" SG_ 421 FC_Obj19_Length 60;
BA_ "GenSigCycleTime" SG_ 421 FC_Obj19_Height 60;
BA_ "GenSigCycleTime" SG_ 421 FC_Obj19_HeadOrientation 60;
BA_ "GenSigCycleTime" SG_ 421 FC_Obj19_HeadingAngle 60;
BA_ "GenSigCycleTime" SG_ 421 FC_Obj19_ExistProb 60;
BA_ "GenSigCycleTime" SG_ 421 FC_Obj19_Dy_Vnce 60;
BA_ "GenSigCycleTime" SG_ 421 FC_Obj19_Dy 60;
BA_ "GenSigCycleTime" SG_ 421 FC_Obj19_Dx_Vnce 60;
BA_ "GenSigCycleTime" SG_ 421 FC_Obj19_Dx 60;
BA_ "GenSigCycleTime" SG_ 421 FC_Obj19_ClassifiedView 60;
BA_ "GenSigCycleTime" SG_ 421 FC_Obj19_Vy 60;
BA_ "GenSigCycleTime" SG_ 421 FC_Obj19_Vx 60;
BA_ "GenSigCycleTime" SG_ 421 FC_Obj19_Ay 60;
BA_ "GenSigCycleTime" SG_ 421 FC_Obj19_Ax 60;
BA_ "GenSigCycleTime" SG_ 421 FC_Obj19_TypeProb 60;
BA_ "GenSigCycleTime" SG_ 421 FC_Obj19_Type 60;
BA_ "GenSigCycleTime" SG_ 421 FC_Obj19_Track_Age 60;
BA_ "GenSigCycleTime" SG_ 421 FC_Obj19_Track_ID 60;
BA_ "GenSigCycleTime" SG_ 421 FC_Obj19_BlockCtr 60;
BA_ "GenSigCycleTime" SG_ 422 FC_RollingCounter_1A6 60;
BA_ "GenSigCycleTime" SG_ 422 FC_CRCCheck_1A6 60;
BA_ "GenSigCycleTime" SG_ 422 FC_obj20_Brakelight_Info 60;
BA_ "GenSigCycleTime" SG_ 422 FC_obj20_Taillight_Info 60;
BA_ "GenSigCycleTime" SG_ 422 FC_Obj20_PhiTop 60;
BA_ "GenSigCycleTime" SG_ 422 FC_Obj20_PhiRightVel 60;
BA_ "GenSigCycleTime" SG_ 422 FC_Obj20_PhiRight 60;
BA_ "GenSigCycleTime" SG_ 422 FC_Obj20_PhiMid 60;
BA_ "GenSigCycleTime" SG_ 422 FC_Obj20_PhiLeftVel 60;
BA_ "GenSigCycleTime" SG_ 422 FC_Obj20_PhiLeft 60;
BA_ "GenSigCycleTime" SG_ 422 FC_Obj20_PhiBottom 60;
BA_ "GenSigCycleTime" SG_ 422 FC_Obj20_Width 60;
BA_ "GenSigCycleTime" SG_ 422 FC_Obj20_Length 60;
BA_ "GenSigCycleTime" SG_ 422 FC_Obj20_Height 60;
BA_ "GenSigCycleTime" SG_ 422 FC_Obj20_HeadOrientation 60;
BA_ "GenSigCycleTime" SG_ 422 FC_Obj20_HeadingAngle 60;
BA_ "GenSigCycleTime" SG_ 422 FC_Obj20_ExistProb 60;
BA_ "GenSigCycleTime" SG_ 422 FC_Obj20_Dy_Vnce 60;
BA_ "GenSigCycleTime" SG_ 422 FC_Obj20_Dy 60;
BA_ "GenSigCycleTime" SG_ 422 FC_Obj20_Dx_Vnce 60;
BA_ "GenSigCycleTime" SG_ 422 FC_Obj20_Dx 60;
BA_ "GenSigCycleTime" SG_ 422 FC_Obj20_ClassifiedView 60;
BA_ "GenSigCycleTime" SG_ 422 FC_Obj20_Vy 60;
BA_ "GenSigCycleTime" SG_ 422 FC_Obj20_Vx 60;
BA_ "GenSigCycleTime" SG_ 422 FC_Obj20_Ay 60;
BA_ "GenSigCycleTime" SG_ 422 FC_Obj20_Ax 60;
BA_ "GenSigCycleTime" SG_ 422 FC_Obj20_TypeProb 60;
BA_ "GenSigCycleTime" SG_ 422 FC_Obj20_Type 60;
BA_ "GenSigCycleTime" SG_ 422 FC_Obj20_Track_Age 60;
BA_ "GenSigCycleTime" SG_ 422 FC_Obj20_Track_ID 60;
BA_ "GenSigCycleTime" SG_ 422 FC_Obj20_BlockCtr 60;
BA_ "GenSigInvalidValue" SG_ 424 FC_TSRRightLaneStatus "7";
BA_ "GenSigCycleTime" SG_ 424 FC_TSRRightLaneStatus 20;
BA_ "GenSigInvalidValue" SG_ 424 FC_TSRLeftLaneStatus "7";
BA_ "GenSigCycleTime" SG_ 424 FC_TSRLeftLaneStatus 20;
BA_ "GenSigInvalidValue" SG_ 424 FC_TSRRightLaneSpdLimit "254";
BA_ "GenSigCycleTime" SG_ 424 FC_TSRRightLaneSpdLimit 20;
BA_ "GenSigInvalidValue" SG_ 424 FC_TSRLeftLaneSpdLimit "254";
BA_ "GenSigCycleTime" SG_ 424 FC_TSRLeftLaneSpdLimit 20;
BA_ "GenSigStartValue" SG_ 424 FC_TLAStopLine_HostLane 255;
BA_ "GenSigCycleTime" SG_ 424 FC_TLAStopLine_HostLane 20;
BA_ "GenSigStartValue" SG_ 424 FC_TLADistance_HostLane 255;
BA_ "GenSigCycleTime" SG_ 424 FC_TLADistance_HostLane 20;
BA_ "GenSigCycleTime" SG_ 424 FC_TLACountDownTime_HostLane 20;
BA_ "GenSigCycleTime" SG_ 424 FC_TSRMandatorySign 20;
BA_ "GenSigCycleTime" SG_ 424 FC_TSRWarningSign 20;
BA_ "GenSigCycleTime" SG_ 424 FC_TSRProhibitionSign 20;
BA_ "GenSigCycleTime" SG_ 424 FC_OverspeedSoundWarningEnSt 20;
BA_ "GenSigCycleTime" SG_ 424 FC_TSREnable 20;
BA_ "GenSigCycleTime" SG_ 424 FC_HMAEnableStatus 20;
BA_ "GenSigCycleTime" SG_ 424 FC_HMALightDistribution 20;
BA_ "GenSigInvalidValue" SG_ 424 FC_HMAStatus "3";
BA_ "GenSigCycleTime" SG_ 424 FC_HMAStatus 20;
BA_ "GenSigInvalidValue" SG_ 424 FC_TSRHostSpdLimitUnits "0";
BA_ "GenSigCycleTime" SG_ 424 FC_TSRHostSpdLimitUnits 20;
BA_ "GenSigInvalidValue" SG_ 424 FC_TSRHostSpdLimit "254";
BA_ "GenSigCycleTime" SG_ 424 FC_TSRHostSpdLimit 20;
BA_ "GenSigInvalidValue" SG_ 424 FC_TSRStatus "7";
BA_ "GenSigCycleTime" SG_ 424 FC_TSRStatus 20;
BA_ "GenSigInvalidValue" SG_ 424 FC_FrontCameraFailureStatus "3";
BA_ "GenSigCycleTime" SG_ 424 FC_FrontCameraFailureStatus 20;
BA_ "GenSigStartValue" SG_ 424 FC_OverspeedWarningOffset 10;
BA_ "GenSigCycleTime" SG_ 424 FC_OverspeedWarningOffset 20;
BA_ "GenSigCycleTime" SG_ 424 FC_OverspeedWarningEnableStatus 20;
BA_ "GenSigCycleTime" SG_ 424 FC_OverspeedSoundWarning 20;
BA_ "GenSigCycleTime" SG_ 424 FC_OverspeedVisualWarning 20;
BA_ "GenSigCycleTime" SG_ 424 FC_TLAArrowDirection_RightLane 20;
BA_ "GenSigCycleTime" SG_ 424 FC_TLAObjectType_RightLane 20;
BA_ "GenSigCycleTime" SG_ 424 FC_TLAObjectStatus_RightLane 20;
BA_ "GenSigCycleTime" SG_ 424 FC_TLAObjectColour_RightLane 20;
BA_ "GenSigCycleTime" SG_ 424 FC_TLAObjectDetection_RightLane 20;
BA_ "GenSigCycleTime" SG_ 424 FC_TLAArrowDirection_LeftLane 20;
BA_ "GenSigCycleTime" SG_ 424 FC_TLAObjectType_LeftLane 20;
BA_ "GenSigCycleTime" SG_ 424 FC_TLAObjectStatus_LeftLane 20;
BA_ "GenSigCycleTime" SG_ 424 FC_TLAObjectColour_LeftLane 20;
BA_ "GenSigCycleTime" SG_ 424 FC_TLAObjectDetection_LeftLane 20;
BA_ "GenSigCycleTime" SG_ 424 FC_TLAArrowDirection_HostLane 20;
BA_ "GenSigCycleTime" SG_ 424 FC_TLAObjectStatus_HostLane 20;
BA_ "GenSigCycleTime" SG_ 424 FC_TLAObjectType_HostLane 20;
BA_ "GenSigCycleTime" SG_ 424 FC_TLAObjectColour_HostLane 20;
BA_ "GenSigCycleTime" SG_ 424 FC_TLAObjectDetection_HostLane 20;
BA_ "GenSigCycleTime" SG_ 424 FC_TLAWarninglevel 20;
BA_ "GenSigInvalidValue" SG_ 424 FC_TLAStatus "3";
BA_ "GenSigCycleTime" SG_ 424 FC_TLAStatus 20;
BA_ "GenSigCycleTime" SG_ 424 FC_TLAEnable 20;
BA_ "GenSigCycleTime" SG_ 424 FC_RollingCounter_1A8 20;
BA_ "GenSigCycleTime" SG_ 424 FC_CRCCheck_1A8 20;
BA_ "GenSigInvalidValue" SG_ 424 FC_FrontCameraCalibrationStatus "3";
BA_ "GenSigCycleTime" SG_ 424 FC_FrontCameraCalibrationStatus 20;
BA_ "GenSigCycleTime" SG_ 424 FC_SLASpdLimit 20;
BA_ "GenSigStartValue" SG_ 424 FC_LaneCurvature_80m 60;
BA_ "GenSigCycleTime" SG_ 424 FC_LaneCurvature_80m 20;
BA_ "GenSigStartValue" SG_ 424 FC_LaneCurvature_50m 60;
BA_ "GenSigCycleTime" SG_ 424 FC_LaneCurvature_50m 20;
BA_ "GenSigStartValue" SG_ 424 FC_LaneCurvature_10m 60;
BA_ "GenSigCycleTime" SG_ 424 FC_LaneCurvature_10m 20;
BA_ "GenSigStartValue" SG_ 424 FC_LaneCurvature_0m 60;
BA_ "GenSigCycleTime" SG_ 424 FC_LaneCurvature_0m 20;
BA_ "GenSigCycleTime" SG_ 424 FC_LaneChangeStatus 20;
BA_ "GenSigCycleTime" SG_ 444 FC_ELKEnableStatus 20;
BA_ "GenSigCycleTime" SG_ 444 FC_HostLaneLeftStatus 20;
BA_ "GenSigCycleTime" SG_ 444 FC_HostLaneRightStatus 20;
BA_ "GenSigCycleTime" SG_ 444 FC_Voiceinfo 20;
BA_ "GenSigCycleTime" SG_ 444 FC_ELKInterventionMode 20;
BA_ "GenSigInvalidValue" SG_ 444 FC_ELKMode "3";
BA_ "GenSigCycleTime" SG_ 444 FC_ELKMode 20;
BA_ "GenSigStartValue" SG_ 444 FC_LDWShakeLevStatus 2;
BA_ "GenSigCycleTime" SG_ 444 FC_LDWShakeLevStatus 20;
BA_ "GenSigStartValue" SG_ 444 FC_LASWarningModeSelectionSts 2;
BA_ "GenSigCycleTime" SG_ 444 FC_LASWarningModeSelectionSts 20;
BA_ "GenSigStartValue" SG_ 444 FC_LASModeSelectionStatus 1;
BA_ "GenSigCycleTime" SG_ 444 FC_LASModeSelectionStatus 20;
BA_ "GenSigCycleTime" SG_ 444 FC_RollingCounter_1BC 20;
BA_ "GenSigCycleTime" SG_ 444 FC_CRCCheck_1BC 20;
BA_ "GenSigCycleTime" SG_ 444 FC_LKATakeoverReq 20;
BA_ "GenSigInvalidValue" SG_ 444 FC_LKAStatus "3";
BA_ "GenSigCycleTime" SG_ 444 FC_LKAStatus 20;
BA_ "GenSigCycleTime" SG_ 444 FC_LDWVibrationWarningReq 20;
BA_ "GenSigInvalidValue" SG_ 444 FC_LDWStatus "3";
BA_ "GenSigCycleTime" SG_ 444 FC_LDWStatus 20;
BA_ "GenSigCycleTime" SG_ 445 FC_RollingCounter_1BD 10;
BA_ "GenSigCycleTime" SG_ 445 FC_CRCCheck_1BD 10;
BA_ "GenSigCycleTime" SG_ 445 FC_LatAngReqActive 10;
BA_ "GenSigCycleTime" SG_ 445 FC_LatAngReq 10;
BA_ "GenSigCycleTime" SG_ 445 FC_MotorTorqueMinLimitRequest 10;
BA_ "GenSigCycleTime" SG_ 445 FC_MotorTorqueMaxLimitRequest 10;
BA_ "GenSigCycleTime" SG_ 447 ADS_SYNC_SyncTime 20;
BA_ "GenSigCycleTime" SG_ 447 ADS_SYNC_Reserved 20;
BA_ "GenSigCycleTime" SG_ 447 ADS_SYNC_SGW 20;
BA_ "GenSigCycleTime" SG_ 447 ADS_SYNC_OVS 20;
BA_ "GenSigCycleTime" SG_ 447 ADS_SYNC_TimeDomain 20;
BA_ "GenSigCycleTime" SG_ 447 ADS_SYNC_SequenceCnt 20;
BA_ "GenSigCycleTime" SG_ 447 ADS_SYNC_CRC 20;
BA_ "GenSigCycleTime" SG_ 447 ADS_SYNC_Type 20;
BA_ "GenSigInvalidValue" SG_ 448 ADS_UDLCStatus "6";
BA_ "GenSigCycleTime" SG_ 448 ADS_UDLCStatus 100;
BA_ "GenSigInvalidValue" SG_ 448 ADS_IACCHWAMode "7";
BA_ "GenSigCycleTime" SG_ 448 ADS_IACCHWAMode 100;
BA_ "GenSigCycleTime" SG_ 423 FC_RollingCounter_1A7 100;
BA_ "GenSigCycleTime" SG_ 423 FC_CRCCheck_1A7 100;
BA_ "GenSigCycleTime" SG_ 423 FC_PostLine_BlockCtr 100;
BA_ "GenSigCycleTime" SG_ 423 FC_PostLineTiOut 100;
BA_ "GenSigCycleTime" SG_ 423 FC_PostLineTiLeap 100;
BA_ "GenSigCycleTime" SG_ 423 FC_PostLineTiBas 100;
BA_ "GenSigCycleTime" SG_ 423 FC_PostLineTiStamp 100;
BA_ "GenSigCycleTime" SG_ 423 FC_Line_Trajectory__dx_Range 100;
BA_ "GenSigCycleTime" SG_ 423 FC_Line_Trajectory_Reliability 100;
BA_ "GenSigCycleTime" SG_ 423 FC_Line_Trajectory_Valid 100;
BA_ "GenSigStartValue" SG_ 423 FC_Line_Trajectory_curvature_alt 2048;
BA_ "GenSigCycleTime" SG_ 423 FC_Line_Trajectory_curvature_alt 100;
BA_ "GenSigStartValue" SG_ 423 FC_Line_Trajectory__curve 4096;
BA_ "GenSigCycleTime" SG_ 423 FC_Line_Trajectory__curve 100;
BA_ "GenSigStartValue" SG_ 423 FC_Line_Trajectory_HeadingAngle 3277;
BA_ "GenSigCycleTime" SG_ 423 FC_Line_Trajectory_HeadingAngle 100;
BA_ "GenSigCycleTime" SG_ 423 FC_Line_Trajectory_dy 100;
BA_ "GenSigStartValue" SG_ 423 FC_Line_Right_curvature_alt 2048;
BA_ "GenSigCycleTime" SG_ 423 FC_Line_Right_curvature_alt 100;
BA_ "GenSigStartValue" SG_ 423 FC_Line_Right__curve 4096;
BA_ "GenSigCycleTime" SG_ 423 FC_Line_Right__curve 100;
BA_ "GenSigStartValue" SG_ 423 FC_Line_Right_HeadingAngle 3277;
BA_ "GenSigCycleTime" SG_ 423 FC_Line_Right_HeadingAngle 100;
BA_ "GenSigCycleTime" SG_ 423 FC_Line_Right_dy 100;
BA_ "GenSigStartValue" SG_ 423 FC_Line_Left_curvature_alt 2048;
BA_ "GenSigCycleTime" SG_ 423 FC_Line_Left_curvature_alt 100;
BA_ "GenSigStartValue" SG_ 423 FC_Line_Left__curve 4096;
BA_ "GenSigCycleTime" SG_ 423 FC_Line_Left__curve 100;
BA_ "GenSigStartValue" SG_ 423 FC_Line_Left_HeadingAngle 3277;
BA_ "GenSigCycleTime" SG_ 423 FC_Line_Left_HeadingAngle 100;
BA_ "GenSigCycleTime" SG_ 423 FC_Line_Left_dy 100;
VAL_ 400 FC_Line_03_MeasureType 0 "unknown" 1 "Virtual" 2 "Measured" ;
VAL_ 400 FC_Line_03_color 0 "Not Detected" 1 "white" 2 "yellow" 3 "white plus yellow" 4 "unknown" 5 "reserved" 6 "reserved" 7 "Invalid" ;
VAL_ 400 FC_Line_03_Type 0 " solid" 1 "dashed" 2 "double_dashed_dashed" 3 "double_dashed_solid" 4 "double_ solid_ dashed" 5 "double_ solid_ solid" 6 " multiple Eu&USA" 7 "multiple_warning Eu&USA" 8 "car_pool" 9 "asphalt_joint USA" 10 "Bot-Dott USA" 11 " road_edge" 12 "guardrail" 13 "curbstone" 14 "wall" 15 "traffic_cone" 16 "delineator_post" 17 "parking_car" 18 "unknown_raised" 19 "fishbone" 20 "unknown" 21 "reserved" ;
VAL_ 400 FC_Line_02_MeasureType 0 "unknown" 1 "Virtual" 2 "Measured" ;
VAL_ 400 FC_Line_02_color 0 "Not Detected" 1 "white" 2 "yellow" 3 "white plus yellow" 4 "unknown" 5 "reserved" 6 "reserved" 7 "Invalid" ;
VAL_ 400 FC_Line_02_Type 0 " solid" 1 "dashed" 2 "double_dashed_dashed" 3 "double_dashed_solid" 4 "double_ solid_ dashed" 5 "double_ solid_ solid" 6 " multiple Eu&USA" 7 "multiple_warning Eu&USA" 8 "car_pool" 9 "asphalt_joint USA" 10 "Bot-Dott USA" 11 " road_edge" 12 "guardrail" 13 "curbstone" 14 "wall" 15 "traffic_cone" 16 "delineator_post" 17 "parking_car" 18 "unknown_raised" 19 "fishbone" 20 "unknown" 21 "reserved" ;
VAL_ 400 FC_LineTiOut 0 "no timeout" 1 "timeout" ;
VAL_ 400 FC_Line_01_MeasureType 0 "unknown" 1 "Virtual" 2 "Measured" ;
VAL_ 400 FC_Line_01_color 0 "Not Detected" 1 "white" 2 "yellow" 3 "white plus yellow" 4 "unknown" 5 "reserved" 6 "reserved" 7 "Invalid" ;
VAL_ 400 FC_Line_01_Type 0 " solid" 1 "dashed" 2 "double_dashed_dashed" 3 "double_dashed_solid" 4 "double_ solid_ dashed" 5 "double_ solid_ solid" 6 " multiple Eu&USA" 7 "multiple_warning Eu&USA" 8 "car_pool" 9 "asphalt_joint USA" 10 "Bot-Dott USA" 11 " road_edge" 12 "guardrail" 13 "curbstone" 14 "wall" 15 "traffic_cone" 16 "delineator_post" 17 "parking_car" 18 "unknown_raised" 19 "fishbone" 20 "unknown" 21 "reserved" ;
VAL_ 401 FC_Line_06_MeasureType 0 "unknown" 1 "Virtual" 2 "Measured" ;
VAL_ 401 FC_Line_06_color 0 "Not Detected" 1 "white" 2 "yellow" 3 "white plus yellow" 4 "unknown" 5 "reserved" 6 "reserved" 7 "Invalid" ;
VAL_ 401 FC_Line_06_Type 0 " solid" 1 "dashed" 2 "double_dashed_dashed" 3 "double_dashed_solid" 4 "double_ solid_ dashed" 5 "double_ solid_ solid" 6 " multiple Eu&USA" 7 "multiple_warning Eu&USA" 8 "car_pool" 9 "asphalt_joint USA" 10 "Bot-Dott USA" 11 " road_edge" 12 "guardrail" 13 "curbstone" 14 "wall" 15 "traffic_cone" 16 "delineator_post" 17 "parking_car" 18 "unknown_raised" 19 "fishbone" 20 "unknown" 21 "reserved" ;
VAL_ 401 FC_Line_05_MeasureType 0 "unknown" 1 "Virtual" 2 "Measured" ;
VAL_ 401 FC_Line_05_color 0 "Not Detected" 1 "white" 2 "yellow" 3 "white plus yellow" 4 "unknown" 5 "reserved" 6 "reserved" 7 "Invalid" ;
VAL_ 401 FC_Line_05_Type 0 " solid" 1 "dashed" 2 "double_dashed_dashed" 3 "double_dashed_solid" 4 "double_ solid_ dashed" 5 "double_ solid_ solid" 6 " multiple Eu&USA" 7 "multiple_warning Eu&USA" 8 "car_pool" 9 "asphalt_joint USA" 10 "Bot-Dott USA" 11 " road_edge" 12 "guardrail" 13 "curbstone" 14 "wall" 15 "traffic_cone" 16 "delineator_post" 17 "parking_car" 18 "unknown_raised" 19 "fishbone" 20 "unknown" 21 "reserved" ;
VAL_ 401 FC_Line_04_MeasureType 0 "unknown" 1 "Virtual" 2 "Measured" ;
VAL_ 401 FC_Line_04_color 0 "Not Detected" 1 "white" 2 "yellow" 3 "white plus yellow" 4 "unknown" 5 "reserved" 6 "reserved" 7 "Invalid" ;
VAL_ 401 FC_Line_04_Type 0 " solid" 1 "dashed" 2 "double_dashed_dashed" 3 "double_dashed_solid" 4 "double_ solid_ dashed" 5 "double_ solid_ solid" 6 " multiple Eu&USA" 7 "multiple_warning Eu&USA" 8 "car_pool" 9 "asphalt_joint USA" 10 "Bot-Dott USA" 11 " road_edge" 12 "guardrail" 13 "curbstone" 14 "wall" 15 "traffic_cone" 16 "delineator_post" 17 "parking_car" 18 "unknown_raised" 19 "fishbone" 20 "unknown" 21 "reserved" ;
VAL_ 402 FC_RoadSignTiOut 0 "no timeout" 1 "timeout" ;
VAL_ 402 FC_Line_08_MeasureType 0 "unknown" 1 "Virtual" 2 "Measured" ;
VAL_ 402 FC_Line_08_color 0 "Not Detected" 1 "white" 2 "yellow" 3 "white plus yellow" 4 "unknown" 5 "reserved" 6 "reserved" 7 "Invalid" ;
VAL_ 402 FC_Line_08_Type 0 " solid" 1 "dashed" 2 "double_dashed_dashed" 3 "double_dashed_solid" 4 "double_ solid_ dashed" 5 "double_ solid_ solid" 6 " multiple Eu&USA" 7 "multiple_warning Eu&USA" 8 "car_pool" 9 "asphalt_joint USA" 10 "Bot-Dott USA" 11 " road_edge" 12 "guardrail" 13 "curbstone" 14 "wall" 15 "traffic_cone" 16 "delineator_post" 17 "parking_car" 18 "unknown_raised" 19 "fishbone" 20 "unknown" 21 "reserved" ;
VAL_ 402 FC_Line_07_MeasureType 0 "unknown" 1 "Virtual" 2 "Measured" ;
VAL_ 402 FC_Line_07_color 0 "Not Detected" 1 "white" 2 "yellow" 3 "white plus yellow" 4 "unknown" 5 "reserved" 6 "reserved" 7 "Invalid" ;
VAL_ 402 FC_Line_07_Type 0 " solid" 1 "dashed" 2 "double_dashed_dashed" 3 "double_dashed_solid" 4 "double_ solid_ dashed" 5 "double_ solid_ solid" 6 " multiple Eu&USA" 7 "multiple_warning Eu&USA" 8 "car_pool" 9 "asphalt_joint USA" 10 "Bot-Dott USA" 11 " road_edge" 12 "guardrail" 13 "curbstone" 14 "wall" 15 "traffic_cone" 16 "delineator_post" 17 "parking_car" 18 "unknown_raised" 19 "fishbone" 20 "unknown" 21 "reserved" ;
VAL_ 403 FC_SignBoardTiOut 0 "no timeout" 1 "timeout" ;
VAL_ 403 FC_SignBoardLength_3 0 "(0.05*X)" 61 "Reserved" ;
VAL_ 403 FC_SignBoardWidth_3 0 "(0.05*X)" 33 "Reserved" ;
VAL_ 403 FC_SignBoardHeight_3 0 "(0.5*X)" 21 "Reserved" ;
VAL_ 403 FC_SignBoardCenterLatRange_3 0 "(-8)+(0.05*X)" 321 "Reserved" ;
VAL_ 403 FC_SignBoardCenterLngRange_3 0 "(0.1*X)" 501 "Reserved" ;
VAL_ 403 FC_SpeedLimit_3 0 "Unknown" 1 "Unlimited" 2 "SL5" 3 "SL10" 4 "SL15" 5 "SL20" 6 "SL25" 7 "SL30" 8 "SL35" 9 "SL40" 10 "SL45" 11 "SL50" 12 "SL55" 13 "SL60" 14 "SL65" 15 "SL70" 16 "SL75" 17 "SL80" 18 "SL85" 19 "SL90" 20 "SL95" 21 "SL100" 22 "SL105" 23 "SL110" 24 "SL115" 25 "SL120" 26 "SL125" 27 "SL130" 28 "SL135" 29 "SL140" 30 "SL145" 31 "SL150" 32 "SL155" 33 "SL160" 34 "SL165" 35 "SL170" 36 "SL175" 36 "SL180" 38 " Reserved" ;
VAL_ 403 FC_SignBoardType_3 0 "Not Detected" 1 "Speed Limits" 2 "Overtaking Signs" 3 "Stop/Yield Signs" 4 "City Limits entry/exit" 5 "Motorway, Highway" 6 "Preference Road" 7 "Residential Area Signs" 8 "NoEntry, NoAll" 9 "Danger Signs" 10 "Weather Condition" 11 "Vehicle Category" 12 "Exit" 13 "Zone" 15 "Text Signs" 16 "Time Condition" 17 "Distance Condition" 18 "Weight Condition" 19 "Recognition of Sign Plates" 20 "Determination of Lane Relevance on Lane Plates" 21 "Suppression of false positives" 22 "Text recognition for additional signs" 23 "Support of further add sign classes based on recognition on segmented text strings" 24 "other" 25 "reserved" 31 "Invalid" ;
VAL_ 403 FC_SignBoardLength_2 0 "(0.05*X)" 61 "Reserved" ;
VAL_ 403 FC_SignBoardWidth_2 0 "(0.05*X)" 33 "Reserved" ;
VAL_ 403 FC_SignBoardHeight_2 0 "(0.5*X)" 21 "Reserved" ;
VAL_ 403 FC_SignBoardCenterLatRange_2 0 "(-8)+(0.05*X)" 321 "Reserved" ;
VAL_ 403 FC_SignBoardCenterLngRange_2 0 "(0.1*X)" 501 "Reserved" ;
VAL_ 403 FC_SpeedLimit_2 0 "Unknown" 1 "Unlimited" 2 "SL5" 3 "SL10" 4 "SL15" 5 "SL20" 6 "SL25" 7 "SL30" 8 "SL35" 9 "SL40" 10 "SL45" 11 "SL50" 12 "SL55" 13 "SL60" 14 "SL65" 15 "SL70" 16 "SL75" 17 "SL80" 18 "SL85" 19 "SL90" 20 "SL95" 21 "SL100" 22 "SL105" 23 "SL110" 24 "SL115" 25 "SL120" 26 "SL125" 27 "SL130" 28 "SL135" 29 "SL140" 30 "SL145" 31 "SL150" 32 "SL155" 33 "SL160" 34 "SL165" 35 "SL170" 36 "SL175" 36 "SL180" 38 " Reserved" ;
VAL_ 403 FC_SignBoardType_2 0 "Not Detected" 1 "Speed Limits" 2 "Overtaking Signs" 3 "Stop/Yield Signs" 4 "City Limits entry/exit" 5 "Motorway, Highway" 6 "Preference Road" 7 "Residential Area Signs" 8 "NoEntry, NoAll" 9 "Danger Signs" 10 "Weather Condition" 11 "Vehicle Category" 12 "Exit" 13 "Zone" 15 "Text Signs" 16 "Time Condition" 17 "Distance Condition" 18 "Weight Condition" 19 "Recognition of Sign Plates" 20 "Determination of Lane Relevance on Lane Plates" 21 "Suppression of false positives" 22 "Text recognition for additional signs" 23 "Support of further add sign classes based on recognition on segmented text strings" 24 "other" 25 "reserved" 31 "Invalid" ;
VAL_ 403 FC_SignBoardLength_1 0 "(0.05*X)" 61 "Reserved" ;
VAL_ 403 FC_SignBoardWidth_1 0 "(0.05*X)" 33 "Reserved" ;
VAL_ 403 FC_SignBoardHeight_1 0 "(0.5*X)" 21 "Reserved" ;
VAL_ 403 FC_SignBoardCenterLatRange_1 0 "(-8)+(0.05*X)" 321 "Reserved" ;
VAL_ 403 FC_SignBoardCenterLngRange_1 0 "(0.1*X)" 501 "Reserved" ;
VAL_ 403 FC_SpeedLimit_1 0 "Unknown" 1 "Unlimited" 2 "SL5" 3 "SL10" 4 "SL15" 5 "SL20" 6 "SL25" 7 "SL30" 8 "SL35" 9 "SL40" 10 "SL45" 11 "SL50" 12 "SL55" 13 "SL60" 14 "SL65" 15 "SL70" 16 "SL75" 17 "SL80" 18 "SL85" 19 "SL90" 20 "SL95" 21 "SL100" 22 "SL105" 23 "SL110" 24 "SL115" 25 "SL120" 26 "SL125" 27 "SL130" 28 "SL135" 29 "SL140" 30 "SL145" 31 "SL150" 32 "SL155" 33 "SL160" 34 "SL165" 35 "SL170" 36 "SL175" 36 "SL180" 38 " Reserved" ;
VAL_ 403 FC_SignBoardType_1 0 "Not Detected" 1 "Speed Limits" 2 "Overtaking Signs" 3 "Stop/Yield Signs" 4 "City Limits entry/exit" 5 "Motorway, Highway" 6 "Preference Road" 7 "Residential Area Signs" 8 "NoEntry, NoAll" 9 "Danger Signs" 10 "Weather Condition" 11 "Vehicle Category" 12 "Exit" 13 "Zone" 15 "Text Signs" 16 "Time Condition" 17 "Distance Condition" 18 "Weight Condition" 19 "Recognition of Sign Plates" 20 "Determination of Lane Relevance on Lane Plates" 21 "Suppression of false positives" 22 "Text recognition for additional signs" 23 "Support of further add sign classes based on recognition on segmented text strings" 24 "other" 25 "reserved" 31 "Invalid" ;
VAL_ 403 FC_RoadSignLength_4 0 "(0.05*X)" 61 "Reserved" ;
VAL_ 403 FC_RoadSignWidth_4 0 "(0.05*X)" 33 "Reserved" ;
VAL_ 403 FC_RoadSignCenterLatRange_4 0 "(-8)+(0.05*X)" 321 "Reserved" ;
VAL_ 403 FC_RoadSignCenterLngRange_4 0 "(0.1*X)m" 501 "Reserved" ;
VAL_ 403 FC_RoadSignType_4 0 "Not Detected" 1 "road Arrow Straight" 2 "road Arrow TurnRight" 3 "road Arrow TurnLeft" 4 "road Arrow Straight and TurnRight" 5 "road Arrow Straight and  TurnLeft" 6 "road Arrow Oncoming" 7 "Chinese Characteristics" 8 "Number " 9 "traffic guidance zone" 10 "Undecided" 11 "Reserved" ;
VAL_ 403 FC_RoadSignLength_3 0 "(0.05*X)" 61 "Reserved" ;
VAL_ 403 FC_RoadSignWidth_3 0 "(0.05*X)" 33 "Reserved" ;
VAL_ 403 FC_RoadSignCenterLatRange_3 0 "(-8)+(0.05*X)" 321 "Reserved" ;
VAL_ 403 FC_RoadSignCenterLngRange_3 0 "(0.1*X)m" 501 "Reserved" ;
VAL_ 403 FC_RoadSignType_3 0 "Not Detected" 1 "road Arrow Straight" 2 "road Arrow TurnRight" 3 "road Arrow TurnLeft" 4 "road Arrow Straight and TurnRight" 5 "road Arrow Straight and  TurnLeft" 6 "road Arrow Oncoming" 7 "Chinese Characteristics" 8 "Number " 9 "traffic guidance zone" 10 "Undecided" 11 "Reserved" ;
VAL_ 403 FC_RoadSignLength_2 0 "(0.05*X)" 61 "Reserved" ;
VAL_ 403 FC_RoadSignWidth_2 0 "(0.05*X)" 33 "Reserved" ;
VAL_ 403 FC_RoadSignCenterLatRange_2 0 "(-8)+(0.05*X)" 321 "Reserved" ;
VAL_ 403 FC_RoadSignCenterLngRange_2 0 "(0.1*X)m" 501 "Reserved" ;
VAL_ 403 FC_RoadSignType_2 0 "Not Detected" 1 "road Arrow Straight" 2 "road Arrow TurnRight" 3 "road Arrow TurnLeft" 4 "road Arrow Straight and TurnRight" 5 "road Arrow Straight and  TurnLeft" 6 "road Arrow Oncoming" 7 "Chinese Characteristics" 8 "Number " 9 "traffic guidance zone" 10 "Undecided" 11 "Reserved" ;
VAL_ 403 FC_RoadSignLength_1 0 "(0.05*X)" 61 "Reserved" ;
VAL_ 403 FC_RoadSignWidth_1 0 "(0.05*X)" 33 "Reserved" ;
VAL_ 403 FC_RoadSignCenterLatRange_1 0 "(-8)+(0.05*X)" 321 "Reserved" ;
VAL_ 403 FC_RoadSignCenterLngRange_1 0 "(0.1*X)m" 501 "Reserved" ;
VAL_ 403 FC_RoadSignType_1 0 "Not Detected" 1 "road Arrow Straight" 2 "road Arrow TurnRight" 3 "road Arrow TurnLeft" 4 "road Arrow Straight and TurnRight" 5 "road Arrow Straight and  TurnLeft" 6 "road Arrow Oncoming" 7 "Chinese Characteristics" 8 "Number " 9 "traffic guidance zone" 10 "Undecided" 11 "Reserved" ;
VAL_ 404 FC_TFLTiOut 0 "no timeout" 1 "timeout" ;
VAL_ 404 FC_SignBoardLength_4 0 "(0.05*X)" 61 "Reserved" ;
VAL_ 404 FC_SignBoardWidth_4 0 "(0.05*X)" 33 "Reserved" ;
VAL_ 404 FC_SignBoardHeight_4 0 "(0.5*X)" 21 "Reserved" ;
VAL_ 404 FC_SignBoardCenterLatRange_4 0 "(-8)+(0.05*X)" 321 "Reserved" ;
VAL_ 404 FC_SignBoardCenterLngRange_4 0 "(0.1*X)" 501 "Reserved" ;
VAL_ 404 FC_SpeedLimit_4 0 "Unknown" 1 "Unlimited" 2 "SL5" 3 "SL10" 4 "SL15" 5 "SL20" 6 "SL25" 7 "SL30" 8 "SL35" 9 "SL40" 10 "SL45" 11 "SL50" 12 "SL55" 13 "SL60" 14 "SL65" 15 "SL70" 16 "SL75" 17 "SL80" 18 "SL85" 19 "SL90" 20 "SL95" 21 "SL100" 22 "SL105" 23 "SL110" 24 "SL115" 25 "SL120" 26 "SL125" 27 "SL130" 28 "SL135" 29 "SL140" 30 "SL145" 31 "SL150" 32 "SL155" 33 "SL160" 34 "SL165" 35 "SL170" 36 "SL175" 36 "SL180" 38 " Reserved" ;
VAL_ 404 FC_SignBoardType_4 0 "Not Detected" 1 "Speed Limits" 2 "Overtaking Signs" 3 "Stop/Yield Signs" 4 "City Limits entry/exit" 5 "Motorway, Highway" 6 "Preference Road" 7 "Residential Area Signs" 8 "NoEntry, NoAll" 9 "Danger Signs" 10 "Weather Condition" 11 "Vehicle Category" 12 "Exit" 13 "Zone" 15 "Text Signs" 16 "Time Condition" 17 "Distance Condition" 18 "Weight Condition" 19 "Recognition of Sign Plates" 20 "Determination of Lane Relevance on Lane Plates" 21 "Suppression of false positives" 22 "Text recognition for additional signs" 23 "Support of further add sign classes based on recognition on segmented text strings" 24 "other" 25 "reserved" 31 "Invalid" ;
VAL_ 405 FC_Obj9_ClassifiedView 0 "unknow" 1 "Front" 2 "Rear" 3 "left" 4 "Right
0X5=~0X7=Reserved" ;
VAL_ 405 FC_Obj9_Type 0 "Not Detected" 1 "car" 2 "truck" 3 "bicycle/motorbike" 4 "pedestrian" 5 "general" 6 "animal" 7 "uncertain" ;
VAL_ 405 FC_ObjTiOut 0 "no timeout" 1 "timeout" ;
VAL_ 405 FC_obj1_Brakelight_Info 0 "off" 1 "on " ;
VAL_ 405 FC_obj1_Taillight_Info 0 "off" 1 "left" 2 "right" 3 "left and right" 4 "invalid" 5 "reserved" ;
VAL_ 405 FC_Obj1_HeadOrientation 0 "Unknown" 1 "Head Front" 2 "Head Left Front" 3 "Head Left" 4 "Head Left Back" 5 "Head Back" 6 "Head Right Back" 7 "Head Right" 8 "Head right front" 9 "Reserved" ;
VAL_ 405 FC_Obj1_ClassifiedView 0 "unknow" 1 "Front" 2 "Rear" 3 "left" 4 "Right
0X5=~0X7=Reserved" ;
VAL_ 405 FC_Obj1_Type 0 "Not Detected" 1 "car" 2 "truck" 3 "bicycle/motorbike" 4 "pedestrian" 5 "general" 6 "animal" 7 "uncertain" ;
VAL_ 406 FC_Obj9_HeadOrientation 0 "Unknown" 1 "Head Front" 2 "Head Left Front" 3 "Head Left" 4 "Head Left Back" 5 "Head Back" 6 "Head Right Back" 7 "Head Right" 8 "Head right front" 9 "Reserved" ;
VAL_ 406 FC_obj2_Brakelight_Info 0 "off" 1 "on " ;
VAL_ 406 FC_obj2_Taillight_Info 0 "off" 1 "left" 2 "right" 3 "left and right" 4 "invalid" 5 "reserved" ;
VAL_ 406 FC_Obj2_HeadOrientation 0 "Unknown" 1 "Head Front" 2 "Head Left Front" 3 "Head Left" 4 "Head Left Back" 5 "Head Back" 6 "Head Right Back" 7 "Head Right" 8 "Head right front" 9 "Reserved" ;
VAL_ 406 FC_Obj2_ClassifiedView 0 "unknow" 1 "Front" 2 "Rear" 3 "left" 4 "Right
0X5=~0X7=Reserved" ;
VAL_ 406 FC_Obj2_Type 0 "Not Detected" 1 "car" 2 "truck" 3 "bicycle/motorbike" 4 "pedestrian" 5 "general" 6 "animal" 7 "uncertain" ;
VAL_ 407 FC_obj9_Brakelight_Info 0 "off" 1 "on" ;
VAL_ 407 FC_obj9_Taillight_Info 0 "off" 1 "left" 2 "right" 3 "left and right" 4 "invalid" 5 "reserved" ;
VAL_ 407 FC_obj3_Brakelight_Info 0 "off" 1 "on " ;
VAL_ 407 FC_obj3_Taillight_Info 0 "off" 1 "left" 2 "right" 3 "left and right" 4 "invalid" 5 "reserved" ;
VAL_ 407 FC_Obj3_HeadOrientation 0 "Unknown" 1 "Head Front" 2 "Head Left Front" 3 "Head Left" 4 "Head Left Back" 5 "Head Back" 6 "Head Right Back" 7 "Head Right" 8 "Head right front" 9 "Reserved" ;
VAL_ 407 FC_Obj3_ClassifiedView 0 "unknow" 1 "Front" 2 "Rear" 3 "left" 4 "Right
0X5=~0X7=Reserved" ;
VAL_ 407 FC_Obj3_Type 0 "Not Detected" 1 "car" 2 "truck" 3 "bicycle/motorbike" 4 "pedestrian" 5 "general" 6 "animal" 7 "uncertain" ;
VAL_ 408 FC_Obj11_ClassifiedView 0 "unknow" 1 "Front" 2 "Rear" 3 "left" 4 "Right
0X5=~0X7=Reserved" ;
VAL_ 408 FC_Obj11_Type 0 "Not Detected" 1 "car" 2 "truck" 3 "bicycle/motorbike" 4 "pedestrian" 5 "general" 6 "animal" 7 "uncertain" ;
VAL_ 408 FC_obj4_Brakelight_Info 0 "off" 1 "on " ;
VAL_ 408 FC_obj4_Taillight_Info 0 "off" 1 "left" 2 "right" 3 "left and right" 4 "invalid" 5 "reserved" ;
VAL_ 408 FC_Obj4_HeadOrientation 0 "Unknown" 1 "Head Front" 2 "Head Left Front" 3 "Head Left" 4 "Head Left Back" 5 "Head Back" 6 "Head Right Back" 7 "Head Right" 8 "Head right front" 9 "Reserved" ;
VAL_ 408 FC_Obj4_ClassifiedView 0 "unknow" 1 "Front" 2 "Rear" 3 "left" 4 "Right
0X5=~0X7=Reserved" ;
VAL_ 408 FC_Obj4_Type 0 "Not Detected" 1 "car" 2 "truck" 3 "bicycle/motorbike" 4 "pedestrian" 5 "general" 6 "animal" 7 "uncertain" ;
VAL_ 409 FC_Obj11_HeadOrientation 0 "Unknown" 1 "Head Front" 2 "Head Left Front" 3 "Head Left" 4 "Head Left Back" 5 "Head Back" 6 "Head Right Back" 7 "Head Right" 8 "Head right front" 9 "Reserved" ;
VAL_ 409 FC_obj5_Brakelight_Info 0 "off" 1 "on " ;
VAL_ 409 FC_obj5_Taillight_Info 0 "off" 1 "left" 2 "right" 3 "left and right" 4 "invalid" 5 "reserved" ;
VAL_ 409 FC_Obj5_HeadOrientation 0 "Unknown" 1 "Head Front" 2 "Head Left Front" 3 "Head Left" 4 "Head Left Back" 5 "Head Back" 6 "Head Right Back" 7 "Head Right" 8 "Head right front" 9 "Reserved" ;
VAL_ 409 FC_Obj5_ClassifiedView 0 "unknow" 1 "Front" 2 "Rear" 3 "left" 4 "Right
0X5=~0X7=Reserved" ;
VAL_ 409 FC_Obj5_Type 0 "Not Detected" 1 "car" 2 "truck" 3 "bicycle/motorbike" 4 "pedestrian" 5 "general" 6 "animal" 7 "uncertain" ;
VAL_ 410 FC_obj11_Brakelight_Info 0 "off" 1 "on" ;
VAL_ 410 FC_obj11_Taillight_Info 0 "off" 1 "left" 2 "right" 3 "left and right" 4 "invalid" 5 "reserved" ;
VAL_ 410 FC_obj6_Brakelight_Info 0 "off" 1 "on " ;
VAL_ 410 FC_obj6_Taillight_Info 0 "off" 1 "left" 2 "right" 3 "left and right" 4 "invalid" 5 "reserved" ;
VAL_ 410 FC_Obj6_HeadOrientation 0 "Unknown" 1 "Head Front" 2 "Head Left Front" 3 "Head Left" 4 "Head Left Back" 5 "Head Back" 6 "Head Right Back" 7 "Head Right" 8 "Head right front" 9 "Reserved" ;
VAL_ 410 FC_Obj6_ClassifiedView 0 "unknow" 1 "Front" 2 "Rear" 3 "left" 4 "Right
0X5=~0X7=Reserved" ;
VAL_ 410 FC_Obj6_Type 0 "Not Detected" 1 "car" 2 "truck" 3 "bicycle/motorbike" 4 "pedestrian" 5 "general" 6 "animal" 7 "uncertain" ;
VAL_ 411 FC_obj7_Brakelight_Info 0 "off" 1 "on" ;
VAL_ 411 FC_obj7_Taillight_Info 0 "off" 1 "left" 2 "right" 3 "left and right" 4 "invalid" 5 "reserved" ;
VAL_ 411 FC_Obj7_HeadOrientation 0 "Unknown" 1 "Head Front" 2 "Head Left Front" 3 "Head Left" 4 "Head Left Back" 5 "Head Back" 6 "Head Right Back" 7 "Head Right" 8 "Head right front" 9 "Reserved" ;
VAL_ 411 FC_Obj7_ClassifiedView 0 "unknow" 1 "Front" 2 "Rear" 3 "left" 4 "Right
0X5=~0X7=Reserved" ;
VAL_ 411 FC_Obj7_Type 0 "Not Detected" 1 "car" 2 "truck" 3 "bicycle/motorbike" 4 "pedestrian" 5 "general" 6 "animal" 7 "uncertain" ;
VAL_ 412 FC_obj8_Brakelight_Info 0 "off" 1 "on" ;
VAL_ 412 FC_obj8_Taillight_Info 0 "off" 1 "left" 2 "right" 3 "left and right" 4 "invalid" 5 "reserved" ;
VAL_ 412 FC_Obj8_HeadOrientation 0 "Unknown" 1 "Head Front" 2 "Head Left Front" 3 "Head Left" 4 "Head Left Back" 5 "Head Back" 6 "Head Right Back" 7 "Head Right" 8 "Head right front" 9 "Reserved" ;
VAL_ 412 FC_Obj8_ClassifiedView 0 "unknow" 1 "Front" 2 "Rear" 3 "left" 4 "Right
0X5=~0X7=Reserved" ;
VAL_ 412 FC_Obj8_Type 0 "Not Detected" 1 "car" 2 "truck" 3 "bicycle/motorbike" 4 "pedestrian" 5 "general" 6 "animal" 7 "uncertain" ;
VAL_ 413 FC_obj10_Brakelight_Info 0 "off" 1 "on" ;
VAL_ 413 FC_obj10_Taillight_Info 0 "off" 1 "left" 2 "right" 3 "left and right" 4 "invalid" 5 "reserved" ;
VAL_ 413 FC_Obj10_HeadOrientation 0 "Unknown" 1 "Head Front" 2 "Head Left Front" 3 "Head Left" 4 "Head Left Back" 5 "Head Back" 6 "Head Right Back" 7 "Head Right" 8 "Head right front" 9 "Reserved" ;
VAL_ 413 FC_Obj10_ClassifiedView 0 "unknow" 1 "Front" 2 "Rear" 3 "left" 4 "Right
0X5=~0X7=Reserved" ;
VAL_ 413 FC_Obj10_Type 0 "Not Detected" 1 "car" 2 "truck" 3 "bicycle/motorbike" 4 "pedestrian" 5 "general" 6 "animal" 7 "uncertain" ;
VAL_ 414 FC_obj12_Brakelight_Info 0 "off" 1 "on" ;
VAL_ 414 FC_obj12_Taillight_Info 0 "off" 1 "left" 2 "right" 3 "left and right" 4 "invalid" 5 "reserved" ;
VAL_ 414 FC_Obj12_HeadOrientation 0 "Unknown" 1 "Head Front" 2 "Head Left Front" 3 "Head Left" 4 "Head Left Back" 5 "Head Back" 6 "Head Right Back" 7 "Head Right" 8 "Head right front" 9 "Reserved" ;
VAL_ 414 FC_Obj12_ClassifiedView 0 "unknow" 1 "Front" 2 "Rear" 3 "left" 4 "Right
0X5=~0X7=Reserved" ;
VAL_ 414 FC_Obj12_Type 0 "Not Detected" 1 "car" 2 "truck" 3 "bicycle/motorbike" 4 "pedestrian" 5 "general" 6 "animal" 7 "uncertain" ;
VAL_ 415 FC_obj13_Brakelight_Info 0 "off" 1 "on" ;
VAL_ 415 FC_obj13_Taillight_Info 0 "off" 1 "left" 2 "right" 3 "left and right" 4 "invalid" 5 "reserved" ;
VAL_ 415 FC_Obj13_HeadOrientation 0 "Unknown" 1 "Head Front" 2 "Head Left Front" 3 "Head Left" 4 "Head Left Back" 5 "Head Back" 6 "Head Right Back" 7 "Head Right" 8 "Head right front" 9 "Reserved" ;
VAL_ 415 FC_Obj13_ClassifiedView 0 "unknow" 1 "Front" 2 "Rear" 3 "left" 4 "Right
0X5=~0X7=Reserved" ;
VAL_ 415 FC_Obj13_Type 0 "Not Detected" 1 "car" 2 "truck" 3 "bicycle/motorbike" 4 "pedestrian" 5 "general" 6 "animal" 7 "uncertain" ;
VAL_ 416 FC_obj14_Brakelight_Info 0 "off" 1 "on" ;
VAL_ 416 FC_obj14_Taillight_Info 0 "off" 1 "left" 2 "right" 3 "left and right" 4 "invalid" 5 "reserved" ;
VAL_ 416 FC_Obj14_HeadOrientation 0 "Unknown" 1 "Head Front" 2 "Head Left Front" 3 "Head Left" 4 "Head Left Back" 5 "Head Back" 6 "Head Right Back" 7 "Head Right" 8 "Head right front" 9 "Reserved" ;
VAL_ 416 FC_Obj14_ClassifiedView 0 "unknow" 1 "Front" 2 "Rear" 3 "left" 4 "Right
0X5=~0X7=Reserved" ;
VAL_ 416 FC_Obj14_Type 0 "Not Detected" 1 "car" 2 "truck" 3 "bicycle/motorbike" 4 "pedestrian" 5 "general" 6 "animal" 7 "uncertain" ;
VAL_ 417 FC_obj15_Brakelight_Info 0 "off" 1 "on" ;
VAL_ 417 FC_obj15_Taillight_Info 0 "off" 1 "left" 2 "right" 3 "left and right" 4 "invalid" 5 "reserved" ;
VAL_ 417 FC_Obj15_HeadOrientation 0 "Unknown" 1 "Head Front" 2 "Head Left Front" 3 "Head Left" 4 "Head Left Back" 5 "Head Back" 6 "Head Right Back" 7 "Head Right" 8 "Head right front" 9 "Reserved" ;
VAL_ 417 FC_Obj15_ClassifiedView 0 "unknow" 1 "Front" 2 "Rear" 3 "left" 4 "Right
0X5=~0X7=Reserved" ;
VAL_ 417 FC_Obj15_Type 0 "Not Detected" 1 "car" 2 "truck" 3 "bicycle/motorbike" 4 "pedestrian" 5 "general" 6 "animal" 7 "uncertain" ;
VAL_ 418 FC_obj16_Brakelight_Info 0 "off" 1 "on" ;
VAL_ 418 FC_obj16_Taillight_Info 0 "off" 1 "left" 2 "right" 3 "left and right" 4 "invalid" 5 "reserved" ;
VAL_ 418 FC_Obj16_HeadOrientation 0 "Unknown" 1 "Head Front" 2 "Head Left Front" 3 "Head Left" 4 "Head Left Back" 5 "Head Back" 6 "Head Right Back" 7 "Head Right" 8 "Head right front" 9 "Reserved" ;
VAL_ 418 FC_Obj16_ClassifiedView 0 "unknow" 1 "Front" 2 "Rear" 3 "left" 4 "Right
0X5=~0X7=Reserved" ;
VAL_ 418 FC_Obj16_Type 0 "Not Detected" 1 "car" 2 "truck" 3 "bicycle/motorbike" 4 "pedestrian" 5 "general" 6 "animal" 7 "uncertain" ;
VAL_ 419 FC_obj17_Brakelight_Info 0 "off" 1 "on" ;
VAL_ 419 FC_obj17_Taillight_Info 0 "off" 1 "left" 2 "right" 3 "left and right" 4 "invalid" 5 "reserved" ;
VAL_ 419 FC_Obj17_HeadOrientation 0 "Unknown" 1 "Head Front" 2 "Head Left Front" 3 "Head Left" 4 "Head Left Back" 5 "Head Back" 6 "Head Right Back" 7 "Head Right" 8 "Head right front" 9 "Reserved" ;
VAL_ 419 FC_Obj17_ClassifiedView 0 "unknow" 1 "Front" 2 "Rear" 3 "left" 4 "Right
0X5=~0X7=Reserved" ;
VAL_ 419 FC_Obj17_Type 0 "Not Detected" 1 "car" 2 "truck" 3 "bicycle/motorbike" 4 "pedestrian" 5 "general" 6 "animal" 7 "uncertain" ;
VAL_ 420 FC_obj18_Brakelight_Info 0 "off" 1 "on" ;
VAL_ 420 FC_obj18_Taillight_Info 0 "off" 1 "left" 2 "right" 3 "left and right" 4 "invalid" 5 "reserved" ;
VAL_ 420 FC_Obj18_HeadOrientation 0 "Unknown" 1 "Head Front" 2 "Head Left Front" 3 "Head Left" 4 "Head Left Back" 5 "Head Back" 6 "Head Right Back" 7 "Head Right" 8 "Head right front" 9 "Reserved" ;
VAL_ 420 FC_Obj18_ClassifiedView 0 "unknow" 1 "Front" 2 "Rear" 3 "left" 4 "Right
0X5=~0X7=Reserved" ;
VAL_ 420 FC_Obj18_Type 0 "Not Detected" 1 "car" 2 "truck" 3 "bicycle/motorbike" 4 "pedestrian" 5 "general" 6 "animal" 7 "uncertain" ;
VAL_ 421 FC_obj19_Brakelight_Info 0 "off" 1 "on" ;
VAL_ 421 FC_obj19_Taillight_Info 0 "off" 1 "left" 2 "right" 3 "left and right" 4 "invalid" 5 "reserved" ;
VAL_ 421 FC_Obj19_HeadOrientation 0 "Unknown" 1 "Head Front" 2 "Head Left Front" 3 "Head Left" 4 "Head Left Back" 5 "Head Back" 6 "Head Right Back" 7 "Head Right" 8 "Head right front" 9 "Reserved" ;
VAL_ 421 FC_Obj19_ClassifiedView 0 "unknow" 1 "Front" 2 "Rear" 3 "left" 4 "Right
0X5=~0X7=Reserved" ;
VAL_ 421 FC_Obj19_Type 0 "Not Detected" 1 "car" 2 "truck" 3 "bicycle/motorbike" 4 "pedestrian" 5 "general" 6 "animal" 7 "uncertain" ;
VAL_ 422 FC_obj20_Brakelight_Info 0 "off" 1 "on" ;
VAL_ 422 FC_obj20_Taillight_Info 0 "off" 1 "left" 2 "right" 3 "left and right" 4 "invalid" 5 "reserved" ;
VAL_ 422 FC_Obj20_HeadOrientation 0 "Unknown" 1 "Head Front" 2 "Head Left Front" 3 "Head Left" 4 "Head Left Back" 5 "Head Back" 6 "Head Right Back" 7 "Head Right" 8 "Head right front" 9 "Reserved" ;
VAL_ 422 FC_Obj20_ClassifiedView 0 "unknow" 1 "Front" 2 "Rear" 3 "left" 4 "Right
0X5=~0X7=Reserved" ;
VAL_ 422 FC_Obj20_Type 0 "Not Detected" 1 "car" 2 "truck" 3 "bicycle" 3 "motorbike" 4 "pedestrian" 5 "general" 6 "animal" 7 "uncertain" ;
VAL_ 424 FC_TSRRightLaneStatus 0 " off" 1 " fusion mode" 2 " vision only mode" 3 " navigation only mode" 4 " reserved" 5 " reserved" 6 " reserved" 7 " Invalid" ;
VAL_ 424 FC_TSRLeftLaneStatus 0 " off" 1 " fusion mode" 2 " vision only mode" 3 " navigation only mode" 4 " reserved" 5 " reserved" 6 " reserved" 7 " Invalid" ;
VAL_ 424 FC_TSRRightLaneSpdLimit 0 "no speed limit detected" 1 "SL5" 2 "SL10" 3 "SL15" 4 "SL20" 5 "SL25" 6 "SL30" 7 "SL35" 8 "SL40" 9 "SL45" 10 "SL50" 11 "SL55" 12 "SL60" 13 "SL65" 14 "SL70" 15 "SL75" 16 "SL80" 17 "SL85" 18 "SL90" 19 "SL95" 20 "SL100" 21 "SL105" 22 "SL110" 23 "SL115" 24 "SL120" 25 "SL125" 26 "SL130" 27 "SL135" 28 "SL140" 29 "SL145" 30 "SL150" 31 "SL155" 32 "SL160" 33 " Reserved" 254 " Unknown" 255 " SLEND" ;
VAL_ 424 FC_TSRLeftLaneSpdLimit 0 "no speed limit detected" 1 "SL5" 2 "SL10" 3 "SL15" 4 "SL20" 5 "SL25" 6 "SL30" 7 "SL35" 8 "SL40" 9 "SL45" 10 "SL50" 11 "SL55" 12 "SL60" 13 "SL65" 14 "SL70" 15 "SL75" 16 "SL80" 17 "SL85" 18 "SL90" 19 "SL95" 20 "SL100" 21 "SL105" 22 "SL110" 23 "SL115" 24 "SL120" 25 "SL125" 26 "SL130" 27 "SL135" 28 "SL140" 29 "SL145" 30 "SL150" 31 "SL155" 32 "SL160" 33 " Reserved" 254 " Unknown" 255 " SLEND" ;
VAL_ 424 FC_TLAStopLine_HostLane 0 "0-250m" 251 "Reserved" 255 "Out of Range" ;
VAL_ 424 FC_TLADistance_HostLane 0 "0-250m" 251 "Reserved" 255 "Out of Range" ;
VAL_ 424 FC_TLACountDownTime_HostLane 0 "no display" 1 "1-120s Countdown Time" 121 "reserved" 127 "out of range" ;
VAL_ 424 FC_TSRMandatorySign 0 "no display" 1 "Single way (straight)" 2 "Walking" 3 "Main road first" 4 "Oncoming vehicles first" 5 "Crosswalk" 6 "Dedicated lane for bus lines" 7 "reserved" ;
VAL_ 424 FC_TSRWarningSign 0 "no display" 1 "Reverse detour" 2 "Continuous detour" 3 "Beware of pedestrians" 4 "Beware of children" 5 "Slippery road" 6 "Tunnel" 7 "Slow down" 8 "Construction" 9 "reserved" ;
VAL_ 424 FC_TSRProhibitionSign 0 "no display" 1 "Prohibit to go through" 2 "No Entry" 3 "Prohibition of motor vehicles" 4 "Prohibit to turn left" 5 "Prohibit to turn right" 6 "Prohibit going straight" 7 "Prohibit to turn around" 8 "Prohibit overtaking" 9 "Cancel Prohibit overtaking" 10 "Prohibit temporary or long-term parking of vehicles" 11 "Prohibit long-term parking of vehicles" 12 "Prohibit honking" 13 "Stop to make way to other vehicles" 14 "Slow down to make way to other vehicles" 15 "Oncoming vehicles first" 16 "reserved" ;
VAL_ 424 FC_OverspeedSoundWarningEnSt 0 "Off" 1 "On" ;
VAL_ 424 FC_TSREnable 0 "off" 1 "on" ;
VAL_ 424 FC_HMAEnableStatus 0 "off" 1 "on" ;
VAL_ 424 FC_HMALightDistribution 0 " High beam not recommended" 1 " High beam recommended" ;
VAL_ 424 FC_HMAStatus 0 " Off" 1 " Standby" 2 " Active" 3 " Failure" ;
VAL_ 424 FC_TSRHostSpdLimitUnits 0 "no display" 1 "unit kph" 2 "unit mph" 3 "reserved" ;
VAL_ 424 FC_TSRHostSpdLimit 0 "no speed limit detected" 1 "SL5" 2 "SL10" 3 "SL15" 4 "SL20" 5 "SL25" 6 "SL30" 7 "SL35" 8 "SL40" 9 "SL45" 10 "SL50" 11 "SL55" 12 "SL60" 13 "SL65" 14 "SL70" 15 "SL75" 16 "SL80" 17 "SL85" 18 "SL90" 19 "SL95" 20 "SL100" 21 "SL105" 22 "SL110" 23 "SL115" 24 "SL120" 25 "SL125" 26 "SL130" 27 "SL135" 28 "SL140" 29 "SL145" 30 "SL150" 31 "SL155" 32 "SL160" 33 " Reserved" 254 " Unknown" 255 " SLEND" ;
VAL_ 424 FC_TSRStatus 0 " off" 1 " fusion mode" 2 " vision only mode" 3 " navigation only mode" 4 " reserved" 5 " reserved" 6 " reserved" 7 " Invalid" ;
VAL_ 424 FC_FrontCameraFailureStatus 0 "No Error" 1 "camera blocked" 2 "temporary failure" 3 "permanent failure" ;
VAL_ 424 FC_OverspeedWarningOffset 0 "" 21 "Reserved" 31 "Invalid." ;
VAL_ 424 FC_OverspeedWarningEnableStatus 0 "OFF" 1 "ON" ;
VAL_ 424 FC_OverspeedSoundWarning 0 " No Warning" 1 " Warning" ;
VAL_ 424 FC_OverspeedVisualWarning 0 " No Warning" 1 " Warning" ;
VAL_ 424 FC_TLAArrowDirection_RightLane 0 "no display" 1 "Forward" 2 "Left" 3 " Forward +Left" 4 "Right" 5 " Forward +Right" 6 "Right+Left" 7 "Left+ Forward +Right" ;
VAL_ 424 FC_TLAObjectType_RightLane 0 "no display" 1 "Round" 2 "Arrow" 3 "Turn Round" 4 "X-type" 5 "Arrow+Trun" 6 "reserved" 7 "reserved" ;
VAL_ 424 FC_TLAObjectStatus_RightLane 0 "no display" 1 "Lighting" 2 "Flashing" 3 " Disappear" ;
VAL_ 424 FC_TLAObjectColour_RightLane 0 "no display" 1 "Red" 2 "Yellow" 3 "Green" ;
VAL_ 424 FC_TLAObjectDetection_RightLane 0 "Not Detected" 1 "Detected" ;
VAL_ 424 FC_TLAArrowDirection_LeftLane 0 "no display" 1 "Forward" 2 "Left" 3 " Forward +Left" 4 "Right" 5 " Forward +Right" 6 "Right+Left" 7 "Left+ Forward +Right" ;
VAL_ 424 FC_TLAObjectType_LeftLane 0 "no display" 1 "Round" 2 "Arrow" 3 "Turn Round" 4 "X-type" 5 "Arrow+Trun" 6 "reserved" 7 "reserved" ;
VAL_ 424 FC_TLAObjectStatus_LeftLane 0 "no display" 1 "Lighting" 2 "Flashing" 3 " Disappear" ;
VAL_ 424 FC_TLAObjectColour_LeftLane 0 "no display" 1 "Red" 2 "Yellow" 3 "Green" ;
VAL_ 424 FC_TLAObjectDetection_LeftLane 0 "Not Detected" 1 "Detected" ;
VAL_ 424 FC_TLAArrowDirection_HostLane 0 "no display" 1 "Forward" 2 "Left" 3 " Forward +Left" 4 "Right" 5 " Forward +Right" 6 "Right+Left" 7 "Left+ Forward +Right" ;
VAL_ 424 FC_TLAObjectStatus_HostLane 0 "no display" 1 "Lighting" 2 "Flashing" 3 " Disappear" ;
VAL_ 424 FC_TLAObjectType_HostLane 0 "no display" 1 "Round" 2 "Arrow" 3 "Turn Round" 4 "X-type" 5 "Arrow+Trun" 6 "reserved" 7 "reserved" ;
VAL_ 424 FC_TLAObjectColour_HostLane 0 "no display" 1 "Red" 2 "Yellow" 3 "Green" ;
VAL_ 424 FC_TLAObjectDetection_HostLane 0 "Not Detected" 1 "Detected" ;
VAL_ 424 FC_TLAWarninglevel 0 " no warning" 1 " warning level 1" 2 " warning level 2" 3 " warning level 3." ;
VAL_ 424 FC_TLAStatus 0 "OFF" 1 "Standby" 2 "Active" 3 "Failure" ;
VAL_ 424 FC_TLAEnable 0 "OFF" 1 "ON" ;
VAL_ 424 FC_FrontCameraCalibrationStatus 0 " Calibration is ok" 1 " Calibration In Process" 2 " Calibration never done" 3 "  Calibration Failed" ;
VAL_ 424 FC_SLASpdLimit 0 "no speed limit detected" 1 "SL5" 2 "SL10" 3 "SL15" 4 "SL20" 5 "SL25" 6 "SL30" 7 "SL35" 8 "SL40" 9 "SL45" 10 "SL50" 11 "SL55" 12 "SL60" 13 "SL65" 14 "SL70" 15 "SL75" 16 "SL80" 17 "SL85" 18 "SL90" 19 "SL95" 20 "SL100" 21 "SL105" 22 "SL110" 23 "SL115" 24 "SL120" 25 "SL125" 26 "SL130" 27 "SL135" 28 "SL140" 29 "SL145" 30 "SL150" 31 "SL155" 32 "SL160" 33 " Reserved" 254 " Unknown" 255 " SLEND" ;
VAL_ 424 FC_LaneCurvature_80m 0 "-0.03-0.03" 121 "reserved" ;
VAL_ 424 FC_LaneCurvature_50m 0 "-0.03-0.03" 121 "reserved" ;
VAL_ 424 FC_LaneCurvature_10m 0 "-0.03-0.03" 121 "reserved" ;
VAL_ 424 FC_LaneCurvature_0m 0 "-0.03-0.03" 121 "reserved" ;
VAL_ 424 FC_LaneChangeStatus 0 "No LaneChange" 1 "Changing to Left" 2 "Changing to Right" 3 "LaneChange is Over" 4 "Unknow" ;
VAL_ 444 FC_ELKEnableStatus 0 "off" 1 "on" ;
VAL_ 444 FC_HostLaneLeftStatus 0 "No display" 1 " reserved" 2 "Intervention" 3 "Warning" 4 "Centering" 5 "reserved" ;
VAL_ 444 FC_HostLaneRightStatus 0 "No display" 1 " reserved" 2 "Intervention" 3 "Warning" 4 "Centering" 5 "reserved" ;
VAL_ 444 FC_Voiceinfo 0 "no voice" 1 "latentWarning voive" 2 "FCW/AEB voice" 3 " reserved" 6 "Lane Left dangerous warning? voice" 7 "Lane Right dangerous warning? voice" 8 " reserved" 14 "TrafficWarning" 15 "reserved" ;
VAL_ 444 FC_ELKInterventionMode 0 " off" 1 " Road edge" 2 " Overtaking" 3 " Oncoming." ;
VAL_ 444 FC_ELKMode 0 " off" 1 " passive" 2 "active" 3 " fault" 4 " reserved." ;
VAL_ 444 FC_LDWShakeLevStatus 0 "reserved" 1 "low" 2 "normal" 3 "high" ;
VAL_ 444 FC_LASWarningModeSelectionSts 0 "Reserved" 1 "sound" 2 "vibration" 3 "sound and vibration" 4 "Reserved" ;
VAL_ 444 FC_LASModeSelectionStatus 0 "Reserved" 1 "LDW" 2 "LKA" 3 "LCS" 4 "Reserved" 7 "OFF" ;
VAL_ 444 FC_LKATakeoverReq 0 "Not Req" 1 "Req" ;
VAL_ 444 FC_LKAStatus 0 "Off" 1 "Standby" 2 "Active" 3 "Failure" ;
VAL_ 444 FC_LDWVibrationWarningReq 0 " No Warning" 1 " Left Warning" 2 "Right Warning" 3 " reserved" ;
VAL_ 444 FC_LDWStatus 0 "Off" 1 "Standby" 2 "Active" 3 "Failure" ;
VAL_ 445 FC_LatAngReqActive 0 "not Active" 1 "Active" ;
VAL_ 445 FC_LatAngReq 14410 "Reserved" ;
VAL_ 445 FC_MotorTorqueMinLimitRequest 2047 " Reserved" ;
VAL_ 445 FC_MotorTorqueMaxLimitRequest 2047 " Reserved" ;
VAL_ 447 ADS_SYNC_SyncTime 0 "0x20 TSync SyncTimeSec = 32 bit LSB of the 48 bits seconds part of the time
Type=0x28 TSync FUP: SyncTimeNSec = 32 Bit time value in nanoseconds: TSync FUP" ;
VAL_ 447 ADS_SYNC_SGW 0 "SyncToGTM " 1 "SyncToSubDomain" ;
VAL_ 447 ADS_SYNC_Type 32 "TSync " 40 "TSync FUP" ;
VAL_ 448 ADS_UDLCStatus 0 "OFF" 1 "Passive" 2 "Active" 3 "Return to lane by driver" 4 "Return to lane by system " 5 "Maual Override" 6 "Failure" 7 "Reserved" ;
VAL_ 448 ADS_IACCHWAMode 0 "off" 1 "standby" 2 "passive" 3 "active" 4 "suspend" 5 " prohibition" 6 "reserved" 7 "failure" ;
VAL_ 423 FC_PostLineTiOut 0 "no timeout" 1 "timeout" ;
VAL_ 423 FC_Line_Trajectory_Valid 0 "Invalid" 1 "Valid" 2 "reserved" 3 "reserved" ;
